VERSION ""

NS_ :

BS_:

BU_:

BO_ 2566889249 VCU_CHMSL: 8 Vector__XXX
 SG_ FF9F_CHMSL_Status : 4|4@1- (1,0) [0|0] "" Vector__XXX

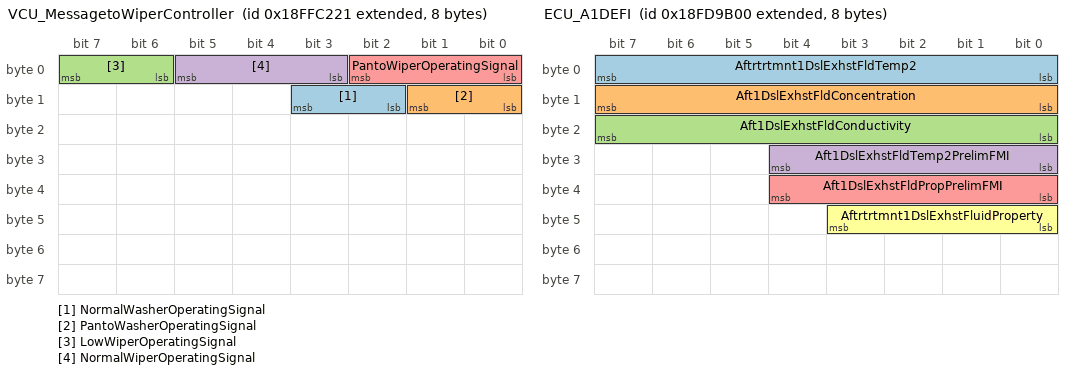
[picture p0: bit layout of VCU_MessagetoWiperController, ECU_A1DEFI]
BO_ 2566898209 VCU_MessagetoWiperController: 8 Vector__XXX
 SG_ NormalWasherOperatingSignal : 10|2@1+ (1,0) [0|3] "bit" Vector__XXX
 SG_ PantoWasherOperatingSignal : 8|2@1+ (1,0) [0|3] "bit" Vector__XXX
 SG_ LowWiperOperatingSignal : 6|2@1+ (1,0) [0|3] "count" Vector__XXX
 SG_ NormalWiperOperatingSignal : 3|3@1+ (1,0) [0|7] "bit" Vector__XXX
 SG_ PantoWiperOperatingSignal : 0|3@1+ (1,0) [0|7] "bit" Vector__XXX

BO_ 2566868921 RPM_Dial_CAN_Type: 8 Vector__XXX
 SG_ FF4F_RPM_Dial_Volt : 0|8@1+ (0.02044,0) [0|0] "" Vector__XXX
 SG_ FF4F_RPM_Dail_Step : 8|4@1+ (1,0) [0|0] "" Vector__XXX

BO_ 2566896387 TCU_TM4V: 8 Vector__XXX
 SG_ FFBB_HSTcutoffSV_State : 4|2@1+ (1,0) [0|3] "" Vector__XXX
 SG_ FFBB_Creep_Symbol : 0|2@1+ (1,0) [0|3] "" Vector__XXX
 SG_ FFBB_2speedSV_State : 2|2@1+ (1,0) [0|3] "" Vector__XXX

BO_ 2566896131 TCU_TM5V: 8 Vector__XXX
 SG_ FFBA_CTL_RH_R_TravelPS : 16|16@1+ (0.0625,0) [0|4095.9375] "bar" Vector__XXX
 SG_ FFBA_CTL_LH_R_TravelPS : 48|16@1+ (0.0625,0) [0|4095.9375] "bar" Vector__XXX
 SG_ FFBA_CTL_LH_F_TravelPS : 32|16@1+ (0.0625,0) [0|4095.9375] "bar" Vector__XXX
 SG_ FFBA_CTL_RH_F_TravelPS : 0|16@1+ (0.0625,0) [0|4095.9375] "bar" Vector__XXX

BO_ 2566575433 EVSE1_ACS1: 8 Vector__XXX
 SG_ EVSE_AC_RMS_Current_Limit_N : 48|16@1+ (0.0625,0) [0|4095.9375] "A" Vector__XXX
 SG_ EVSE_AC_RMS_Current_Limit_3 : 32|16@1+ (0.0625,0) [0|4095.9375] "A" Vector__XXX
 SG_ EVSE_AC_RMS_Current_Limit_2 : 16|16@1+ (0.0625,0) [0|4095.9375] "A" Vector__XXX
 SG_ EVSE_AC_RMS_Current_Limit_1 : 0|16@1+ (0.0625,0) [0|4095.9375] "A" Vector__XXX

BO_ 2365571361 VCU_VM2T: 8 Vector__XXX
 SG_ FFC1_VCU_Counter : 56|4@1+ (1,0) [0|15] "State" Vector__XXX
 SG_ FFC1_VCU_CheckSum : 60|4@1+ (1,0) [0|15] "State" Vector__XXX
 SG_ FFC1_VCU_OPS : 8|2@1+ (1,0) [0|3] "state" Vector__XXX
 SG_ FFC1_VCU_EngineControlDial : 0|8@1+ (0.02044,0) [0|5.11] "V" Vector__XXX

BO_ 2566758144 ECU_ATS1AC1: 8 Vector__XXX
 SG_ FD9F_ATS1AirPressAP : 48|8@1+ (0.4,0) [0|100] "%" Vector__XXX
 SG_ FD9F_ATS1AirPressCTRL : 32|16@1+ (0.0025,0) [0|160.6375] "%" Vector__XXX

BO_ 2566757120 ECU_A1DEFI: 8 Vector__XXX
 SG_ Aftrtrtmnt1DslExhstFldTemp2 : 0|8@1+ (1,-40) [-40|210] "deg C" Vector__XXX
 SG_ Aft1DslExhstFldConcentration : 8|8@1+ (0.25,0) [0|62.5] "%" Vector__XXX
 SG_ Aft1DslExhstFldConductivity : 16|8@1+ (5,0) [0|1250] "uS/mm" Vector__XXX
 SG_ Aft1DslExhstFldTemp2PrelimFMI : 24|5@1+ (1,0) [0|31] "" Vector__XXX
 SG_ Aft1DslExhstFldPropPrelimFMI : 32|5@1+ (1,0) [0|31] "" Vector__XXX
 SG_ Aftrtrtmnt1DslExhstFluidProperty : 40|4@1+ (1,0) [0|15] "" Vector__XXX

BO_ 2566753280 ECU_ATS1GasPara: 8 Vector__XXX
 SG_ FD8C_DPFIntakePress1 : 0|16@1+ (0.1,0) [0|6425.5] "kpa" Vector__XXX

BO_ 2566745344 ECU_ATS1AC2: 8 Vector__XXX
 SG_ FD6D_ATS12edAirPress : 48|16@1+ (0.1,0) [0|6425.5] "kPa" Vector__XXX
 SG_ FD6D_ATS12edAirMassFlow : 32|16@1+ (0.2,0) [0|12851] "kg" Vector__XXX

BO_ 2566743296 ECU_ATS1FC2: 8 Vector__XXX
 SG_ FD65_AT1FuelFlowPress2ActCTRL : 24|16@1+ (0.0025,0) [0|160.6375] "%" Vector__XXX
 SG_ FD65_AT1FuelFlowDiverValveCTRL : 18|2@1+ (1,0) [0|3] "" Vector__XXX
 SG_ FD65_AT1FuelPumpRelayCTRL : 16|2@1+ (1,0) [0|3] "" Vector__XXX
 SG_ FD65_AT1FuelPress2 : 0|16@1+ (0.1,0) [0|6425.5] "kPa" Vector__XXX

BO_ 2566708736 ECU_AT1AC3: 8 Vector__XXX
 SG_ FCDE_AT1SeAirAbPress : 0|16@1+ (0.1,0) [0|6553.5] "kPa" Vector__XXX

BO_ 2566700288 ECU_A1SCRSI2: 8 Vector__XXX
 SG_ FCBD_Af1TotalDieExFluUsed : 0|32@1+ (0.5,0) [0|2105540607.5] "Liter" Vector__XXX

BO_ 2566699264 ECU_AT1S2: 8 Vector__XXX
 SG_ FCB9_Af1DPFTimeToNextActRegen : 0|32@1+ (1,0) [0|4211081215] "Sec" Vector__XXX

BO_ 2566890792 GP_GPCCS: 8 Vector__XXX
 SG_ FFA5_Counter : 56|4@1+ (1,0) [0|15] "State" Vector__XXX
 SG_ FFA5_CheckSum : 60|4@1+ (1,0) [0|15] "State" Vector__XXX
 SG_ FFA5_JoystickPatternChange : 0|3@1+ (1,0) [0|7] "" Vector__XXX

BO_ 2365542433 VCU_Pwr_Work_Btn: 8 Vector__XXX
 SG_ FF50_WorkModeButton : 8|2@1+ (1,0) [0|3] "" Vector__XXX
 SG_ FF50_Power_Btn : 0|3@1+ (1,0) [0|7] "" Vector__XXX

BO_ 2566847521 VCU_DD1: 8 Vector__XXX
 SG_ FEFC_FuelTankLevel2 : 48|8@1+ (0.4,0) [0|102] "%" Vector__XXX
 SG_ FEFC_EngineOilFilterPressure : 24|8@1+ (0.5,0) [0|127.5] "kPa" Vector__XXX
 SG_ FEFC_EngineFuelFilterPressure : 16|8@1+ (2,0) [0|510] "kPa" Vector__XXX
 SG_ FEFC_CargoAmbientTemperature : 32|16@1+ (0.03125,0) [0|2047.96875] "กษ" Vector__XXX
 SG_ FEFC_WasherFluidLevel : 0|8@1+ (0.4,0) [0|102] "%" Vector__XXX
 SG_ FEFC_FuelTankLevel1 : 8|8@1+ (0.4,0) [0|102] "%" Vector__XXX

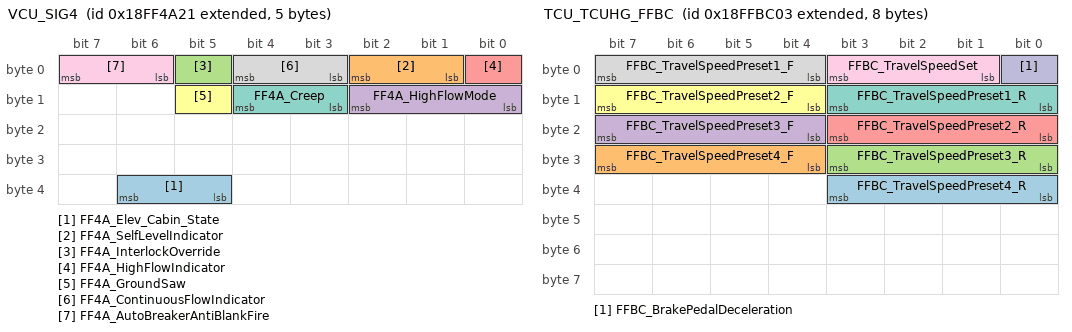
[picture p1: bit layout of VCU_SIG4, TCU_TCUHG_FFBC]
BO_ 2566867489 VCU_SIG4: 5 Vector__XXX
 SG_ FF4A_Elev_Cabin_State : 37|2@1+ (1,0) [0|3] "" Vector__XXX
 SG_ FF4A_SelfLevelIndicator : 1|2@1+ (1,0) [0|3] "" Vector__XXX
 SG_ FF4A_InterlockOverride : 5|1@1+ (1,0) [0|1] "" Vector__XXX
 SG_ FF4A_HighFlowMode : 8|3@1+ (1,0) [0|7] "" Vector__XXX
 SG_ FF4A_HighFlowIndicator : 0|1@1+ (1,0) [0|1] "" Vector__XXX
 SG_ FF4A_GroundSaw : 13|1@1+ (1,0) [0|1] "" Vector__XXX
 SG_ FF4A_Creep : 11|2@1+ (1,0) [0|3] "" Vector__XXX
 SG_ FF4A_ContinuousFlowIndicator : 3|2@1+ (1,0) [0|3] "" Vector__XXX
 SG_ FF4A_AutoBreakerAntiBlankFire : 6|2@1+ (1,0) [0|3] "" Vector__XXX

BO_ 2566835017 OBC_DM02_SA49: 42 Vector__XXX
 SG_ FECA_10_SPNConversionMethod : 335|1@1+ (1,0) [0|1] "" Vector__XXX
 SG_ FECA_10_SPN3 : 325|3@1+ (1,0) [0|7] "" Vector__XXX
 SG_ FECA_10_SPN1_2 : 304|16@1+ (1,0) [0|65535] "" Vector__XXX
 SG_ FECA_10_OccurenceCount : 328|7@1+ (1,0) [0|127] "" Vector__XXX
 SG_ FECA_10_FMI : 320|5@1+ (1,0) [0|31] "" Vector__XXX
 SG_ FECA_09_SPNConversionMethod : 303|1@1+ (1,0) [0|1] "" Vector__XXX
 SG_ FECA_09_SPN3 : 293|3@1+ (1,0) [0|7] "" Vector__XXX
 SG_ FECA_09_SPN1_2 : 272|16@1+ (1,0) [0|65535] "" Vector__XXX
 SG_ FECA_09_OccurenceCount : 296|7@1+ (1,0) [0|127] "" Vector__XXX
 SG_ FECA_09_FMI : 288|5@1+ (1,0) [0|31] "" Vector__XXX
 SG_ FECA_08_SPNConversionMethod : 271|1@1+ (1,0) [0|1] "" Vector__XXX
 SG_ FECA_08_SPN3 : 261|3@1+ (1,0) [0|7] "" Vector__XXX
 SG_ FECA_08_SPN1_2 : 240|16@1+ (1,0) [0|65535] "" Vector__XXX
 SG_ FECA_08_OccurenceCount : 264|7@1+ (1,0) [0|127] "" Vector__XXX
 SG_ FECA_08_FMI : 256|5@1+ (1,0) [0|31] "" Vector__XXX
 SG_ FECA_07_SPNConversionMethod : 239|1@1+ (1,0) [0|1] "" Vector__XXX
 SG_ FECA_07_SPN3 : 229|3@1+ (1,0) [0|7] "" Vector__XXX
 SG_ FECA_07_SPN1_2 : 208|16@1+ (1,0) [0|65535] "" Vector__XXX
 SG_ FECA_07_OccurenceCount : 232|7@1+ (1,0) [0|127] "" Vector__XXX
 SG_ FECA_07_FMI : 224|5@1+ (1,0) [0|31] "" Vector__XXX
 SG_ FECA_06_SPNConversionMethod : 207|1@1+ (1,0) [0|1] "" Vector__XXX
 SG_ FECA_06_SPN3 : 197|3@1+ (1,0) [0|7] "" Vector__XXX
 SG_ FECA_06_SPN1_2 : 176|16@1+ (1,0) [0|65535] "" Vector__XXX
 SG_ FECA_06_OccurenceCount : 200|7@1+ (1,0) [0|127] "" Vector__XXX
 SG_ FECA_06_FMI : 192|5@1+ (1,0) [0|31] "" Vector__XXX
 SG_ FECA_05_SPNConversionMethod : 175|1@1+ (1,0) [0|1] "" Vector__XXX
 SG_ FECA_05_SPN3 : 165|3@1+ (1,0) [0|7] "" Vector__XXX
 SG_ FECA_05_SPN1_2 : 144|16@1+ (1,0) [0|65535] "" Vector__XXX
 SG_ FECA_05_OccurenceCount : 168|7@1+ (1,0) [0|127] "" Vector__XXX
 SG_ FECA_05_FMI : 160|5@1+ (1,0) [0|31] "" Vector__XXX
 SG_ FECA_04_SPNConversionMethod : 143|1@1+ (1,0) [0|1] "" Vector__XXX
 SG_ FECA_04_SPN3 : 133|3@1+ (1,0) [0|7] "" Vector__XXX
 SG_ FECA_04_SPN1_2 : 112|16@1+ (1,0) [0|65535] "" Vector__XXX
 SG_ FECA_04_OccurenceCount : 136|7@1+ (1,0) [0|127] "" Vector__XXX
 SG_ FECA_04_FMI : 128|5@1+ (1,0) [0|31] "" Vector__XXX
 SG_ FECA_03_SPNConversionMethod : 111|1@1+ (1,0) [0|1] "" Vector__XXX
 SG_ FECA_03_SPN3 : 101|3@1+ (1,0) [0|7] "" Vector__XXX
 SG_ FECA_03_SPN1_2 : 80|16@1+ (1,0) [0|65535] "" Vector__XXX
 SG_ FECA_03_OccurenceCount : 104|7@1+ (1,0) [0|127] "" Vector__XXX
 SG_ FECA_03_FMI : 96|5@1+ (1,0) [0|31] "" Vector__XXX
 SG_ FECA_02_SPNConversionMethod : 79|1@1+ (1,0) [0|1] "" Vector__XXX
 SG_ FECA_02_SPN3 : 69|3@1+ (1,0) [0|7] "" Vector__XXX
 SG_ FECA_02_SPN1_2 : 48|16@1+ (1,0) [0|65535] "" Vector__XXX
 SG_ FECA_02_OccurenceCount : 72|7@1+ (1,0) [0|127] "" Vector__XXX
 SG_ FECA_02_FMI : 64|5@1+ (1,0) [0|31] "" Vector__XXX
 SG_ FECA_01_SPNConversionMethod : 47|1@1+ (1,0) [0|1] "" Vector__XXX
 SG_ FECA_01_SPN3 : 37|3@1+ (1,0) [0|7] "" Vector__XXX
 SG_ FECA_01_SPN1_2 : 16|16@1+ (1,0) [0|65535] "" Vector__XXX
 SG_ FECA_01_RedStopLampStatus : 4|2@1+ (1,0) [0|3] "" Vector__XXX
 SG_ FECA_01_ProtectLampStatus : 0|2@1+ (1,0) [0|3] "" Vector__XXX
 SG_ FECA_01_OccurenceCount : 40|7@1+ (1,0) [0|127] "" Vector__XXX
 SG_ FECA_01_MalFucIndicatorStatus : 6|2@1+ (1,0) [0|3] "" Vector__XXX
 SG_ FECA_01_FMI : 32|5@1+ (1,0) [0|31] "" Vector__XXX
 SG_ FECA_01_FlashRedStopLamp : 12|2@1+ (1,0) [0|3] "" Vector__XXX
 SG_ FECA_01_FlashProtectLamp : 8|2@1+ (1,0) [0|3] "" Vector__XXX
 SG_ FECA_01_FlashAmberLamp : 10|2@1+ (1,0) [0|3] "" Vector__XXX
 SG_ FECA_01_Flash_MalFuncIndiLamp : 14|2@1+ (1,0) [0|3] "" Vector__XXX
 SG_ FECA_01_AmberWarmingLampStatus : 2|2@1+ (1,0) [0|3] "" Vector__XXX

BO_ 2566834761 OBC_DM01_SA49: 42 Vector__XXX
 SG_ FECA_10_SPNConversionMethod : 335|1@1+ (1,0) [0|1] "" Vector__XXX
 SG_ FECA_10_SPN3 : 325|3@1+ (1,0) [0|7] "" Vector__XXX
 SG_ FECA_10_SPN1_2 : 304|16@1+ (1,0) [0|65535] "" Vector__XXX
 SG_ FECA_10_OccurenceCount : 328|7@1+ (1,0) [0|127] "" Vector__XXX
 SG_ FECA_10_FMI : 320|5@1+ (1,0) [0|31] "" Vector__XXX
 SG_ FECA_09_SPNConversionMethod : 303|1@1+ (1,0) [0|1] "" Vector__XXX
 SG_ FECA_09_SPN3 : 293|3@1+ (1,0) [0|7] "" Vector__XXX
 SG_ FECA_09_SPN1_2 : 272|16@1+ (1,0) [0|65535] "" Vector__XXX
 SG_ FECA_09_OccurenceCount : 296|7@1+ (1,0) [0|127] "" Vector__XXX
 SG_ FECA_09_FMI : 288|5@1+ (1,0) [0|31] "" Vector__XXX
 SG_ FECA_08_SPNConversionMethod : 271|1@1+ (1,0) [0|1] "" Vector__XXX
 SG_ FECA_08_SPN3 : 261|3@1+ (1,0) [0|7] "" Vector__XXX
 SG_ FECA_08_SPN1_2 : 240|16@1+ (1,0) [0|65535] "" Vector__XXX
 SG_ FECA_08_OccurenceCount : 264|7@1+ (1,0) [0|127] "" Vector__XXX
 SG_ FECA_08_FMI : 256|5@1+ (1,0) [0|31] "" Vector__XXX
 SG_ FECA_07_SPNConversionMethod : 239|1@1+ (1,0) [0|1] "" Vector__XXX
 SG_ FECA_07_SPN3 : 229|3@1+ (1,0) [0|7] "" Vector__XXX
 SG_ FECA_07_SPN1_2 : 208|16@1+ (1,0) [0|65535] "" Vector__XXX
 SG_ FECA_07_OccurenceCount : 232|7@1+ (1,0) [0|127] "" Vector__XXX
 SG_ FECA_07_FMI : 224|5@1+ (1,0) [0|31] "" Vector__XXX
 SG_ FECA_06_SPNConversionMethod : 207|1@1+ (1,0) [0|1] "" Vector__XXX
 SG_ FECA_06_SPN3 : 197|3@1+ (1,0) [0|7] "" Vector__XXX
 SG_ FECA_06_SPN1_2 : 176|16@1+ (1,0) [0|65535] "" Vector__XXX
 SG_ FECA_06_OccurenceCount : 200|7@1+ (1,0) [0|127] "" Vector__XXX
 SG_ FECA_06_FMI : 192|5@1+ (1,0) [0|31] "" Vector__XXX
 SG_ FECA_05_SPNConversionMethod : 175|1@1+ (1,0) [0|1] "" Vector__XXX
 SG_ FECA_05_SPN3 : 165|3@1+ (1,0) [0|7] "" Vector__XXX
 SG_ FECA_05_SPN1_2 : 144|16@1+ (1,0) [0|65535] "" Vector__XXX
 SG_ FECA_05_OccurenceCount : 168|7@1+ (1,0) [0|127] "" Vector__XXX
 SG_ FECA_05_FMI : 160|5@1+ (1,0) [0|31] "" Vector__XXX
 SG_ FECA_04_SPNConversionMethod : 143|1@1+ (1,0) [0|1] "" Vector__XXX
 SG_ FECA_04_SPN3 : 133|3@1+ (1,0) [0|7] "" Vector__XXX
 SG_ FECA_04_SPN1_2 : 112|16@1+ (1,0) [0|65535] "" Vector__XXX
 SG_ FECA_04_OccurenceCount : 136|7@1+ (1,0) [0|127] "" Vector__XXX
 SG_ FECA_04_FMI : 128|5@1+ (1,0) [0|31] "" Vector__XXX
 SG_ FECA_03_SPNConversionMethod : 111|1@1+ (1,0) [0|1] "" Vector__XXX
 SG_ FECA_03_SPN3 : 101|3@1+ (1,0) [0|7] "" Vector__XXX
 SG_ FECA_03_SPN1_2 : 80|16@1+ (1,0) [0|65535] "" Vector__XXX
 SG_ FECA_03_OccurenceCount : 104|7@1+ (1,0) [0|127] "" Vector__XXX
 SG_ FECA_03_FMI : 96|5@1+ (1,0) [0|31] "" Vector__XXX
 SG_ FECA_02_SPNConversionMethod : 79|1@1+ (1,0) [0|1] "" Vector__XXX
 SG_ FECA_02_SPN3 : 69|3@1+ (1,0) [0|7] "" Vector__XXX
 SG_ FECA_02_SPN1_2 : 48|16@1+ (1,0) [0|65535] "" Vector__XXX
 SG_ FECA_02_OccurenceCount : 72|7@1+ (1,0) [0|127] "" Vector__XXX
 SG_ FECA_02_FMI : 64|5@1+ (1,0) [0|31] "" Vector__XXX
 SG_ FECA_01_SPNConversionMethod : 47|1@1+ (1,0) [0|1] "" Vector__XXX
 SG_ FECA_01_SPN3 : 37|3@1+ (1,0) [0|7] "" Vector__XXX
 SG_ FECA_01_SPN1_2 : 16|16@1+ (1,0) [0|65535] "" Vector__XXX
 SG_ FECA_01_RedStopLampStatus : 4|2@1+ (1,0) [0|3] "" Vector__XXX
 SG_ FECA_01_ProtectLampStatus : 0|2@1+ (1,0) [0|3] "" Vector__XXX
 SG_ FECA_01_OccurenceCount : 40|7@1+ (1,0) [0|127] "" Vector__XXX
 SG_ FECA_01_MalFucIndicatorStatus : 6|2@1+ (1,0) [0|3] "" Vector__XXX
 SG_ FECA_01_FMI : 32|5@1+ (1,0) [0|31] "" Vector__XXX
 SG_ FECA_01_FlashRedStopLamp : 12|2@1+ (1,0) [0|3] "" Vector__XXX
 SG_ FECA_01_FlashProtectLamp : 8|2@1+ (1,0) [0|3] "" Vector__XXX
 SG_ FECA_01_FlashAmberLamp : 10|2@1+ (1,0) [0|3] "" Vector__XXX
 SG_ FECA_01_Flash_MalFuncIndiLamp : 14|2@1+ (1,0) [0|3] "" Vector__XXX
 SG_ FECA_01_AmberWarmingLampStatus : 2|2@1+ (1,0) [0|3] "" Vector__XXX

BO_ 2566722633 OBC_BCH2_SA49: 9 Vector__XXX
 SG_ FD14_Bat_Charger2_OutputCurrent : 24|16@1+ (0.05,-1600) [-1600|1676.75] "0" Vector__XXX
 SG_ FD14_Bat_Charger2_OutputVolt : 8|2@1+ (0.05,0) [0|0.15] "" Vector__XXX
 SG_ FD14_Bat_Charger2_RestartState : 6|2@1+ (1,0) [0|3] "" Vector__XXX
 SG_ FD14_Bat_Charger2_PowerLineState : 4|2@1+ (1,0) [0|3] "" Vector__XXX
 SG_ FD14_Bat_Charger2_State : 0|4@1+ (1,0) [0|15] "" Vector__XXX

BO_ 2566722989 OBC_BCH1: 9 Vector__XXX
 SG_ FD15_Reserved : 40|32@1- (1,0) [-2147483648|2147483647] "" Vector__XXX
 SG_ FD15_Battery_Charger1_State : 0|4@1+ (1,0) [0|15] "bit" Vector__XXX
 SG_ FD15_Battery_Charger1_Pow_State : 4|4@1+ (1,0) [0|3] "bit" Vector__XXX
 SG_ FD15_Battery_Charger1_Out_Volt : 8|16@1+ (0.05,0) [0|210] "V" Vector__XXX
 SG_ FD15_Battery_Charger1_Out_Curr : 24|16@1+ (0.05,-1600) [-1600|1612.75] "A" Vector__XXX

BO_ 2566722733 OBC_BCH2: 9 Vector__XXX
 SG_ FD14_Bat_Charger2_OutputCurrent : 24|16@1+ (0.05,-1600) [-1600|1676.75] "0" Vector__XXX
 SG_ FD14_Bat_Charger2_OutputVolt : 8|2@1+ (0.05,0) [0|0.15] "" Vector__XXX
 SG_ FD14_Bat_Charger2_RestartState : 6|2@1+ (1,0) [0|3] "" Vector__XXX
 SG_ FD14_Bat_Charger2_PowerLineState : 4|2@1+ (1,0) [0|3] "" Vector__XXX
 SG_ FD14_Bat_Charger2_State : 0|4@1+ (1,0) [0|15] "" Vector__XXX

BO_ 2354970657 VCU_MG1ReqDC: 8 Vector__XXX
 SG_ _5E00_ReqDC_S_CurMaxRegen : 48|12@1+ (0.0625,-125) [-125|125] "" Vector__XXX
 SG_ _5E00_ReqDC_S_CurMaxDrive : 36|12@1+ (0.0625,-125) [-125|125] "" Vector__XXX
 SG_ _5E00_Reserved : 0|36@1+ (1,0) [0|68719476735] "" Vector__XXX

BO_ 2566901763 TCU_HSDI_FFD0: 8 Vector__XXX
 SG_ FFD0_TCU_Randomvalue : 0|16@1+ (1,0) [0|65535] "" Vector__XXX

BO_ 2566896643 TCU_TCUHG_FFBC: 8 Vector__XXX
 SG_ FFBC_TravelSpeedPreset4_R : 32|4@1+ (1,0) [0|15] "" Vector__XXX
 SG_ FFBC_TravelSpeedPreset4_F : 28|4@1+ (1,0) [0|15] "" Vector__XXX
 SG_ FFBC_TravelSpeedPreset3_R : 24|4@1+ (1,0) [0|15] "" Vector__XXX
 SG_ FFBC_TravelSpeedPreset3_F : 20|4@1+ (1,0) [0|15] "" Vector__XXX
 SG_ FFBC_TravelSpeedPreset2_R : 16|4@1+ (1,0) [0|15] "" Vector__XXX
 SG_ FFBC_TravelSpeedPreset2_F : 12|4@1+ (1,0) [0|15] "" Vector__XXX
 SG_ FFBC_TravelSpeedPreset1_R : 8|4@1+ (1,0) [0|15] "" Vector__XXX
 SG_ FFBC_TravelSpeedPreset1_F : 4|4@1+ (1,0) [0|15] "" Vector__XXX
 SG_ FFBC_TravelSpeedSet : 1|3@1+ (1,0) [0|7] "" Vector__XXX
 SG_ FFBC_BrakePedalDeceleration : 0|1@1+ (1,0) [0|1] "" Vector__XXX

BO_ 2365544737 Keypad_KEYPADI3_xC: 8 Vector__XXX
 SG_ FF59_TrackExpansion_L : 58|2@1+ (1,0) [0|3] "" Vector__XXX
 SG_ FF59_TrackExpansion_Center : 56|2@1+ (1,0) [0|3] "" Vector__XXX
 SG_ FF59_TrackExpansion_R : 54|2@1+ (1,0) [0|3] "" Vector__XXX
 SG_ FF59_Indicate_Wiper_Front_R : 48|2@1+ (1,0) [0|3] "" Vector__XXX
 SG_ FF59_Indicate_Wiper_Front_L : 52|2@1+ (1,0) [0|3] "" Vector__XXX
 SG_ FF59_Indicate_Wiper_Front_C : 50|2@1+ (1,0) [0|3] "" Vector__XXX
 SG_ FF59_Indicate_Wiper_Rear_R : 42|2@1+ (1,0) [0|3] "" Vector__XXX
 SG_ FF59_Indicate_Wiper_Rear_L : 46|2@1+ (1,0) [0|3] "" Vector__XXX
 SG_ FF59_Indicate_Wiper_Rear_C : 44|2@1+ (1,0) [0|3] "" Vector__XXX
 SG_ FF59_Indicate_Wiper_Side_R : 36|2@1+ (1,0) [0|3] "" Vector__XXX
 SG_ FF59_Indicate_Wiper_Side_L : 40|2@1+ (1,0) [0|3] "" Vector__XXX
 SG_ FF59_Indicate_Wiper_Side_C : 38|2@1+ (1,0) [0|3] "" Vector__XXX
 SG_ FF59_Indicate_Washer_Front_R : 30|2@1+ (1,0) [0|3] "" Vector__XXX
 SG_ FF59_Indicate_Washer_Front_L : 34|2@1+ (1,0) [0|3] "" Vector__XXX
 SG_ FF59_Indicate_Washer_Front_C : 32|2@1+ (1,0) [0|3] "" Vector__XXX
 SG_ FF59_Indicate_Washer_Side_R : 24|2@1+ (1,0) [0|3] "" Vector__XXX
 SG_ FF59_Indicate_Washer_Side_L : 28|2@1+ (1,0) [0|3] "" Vector__XXX
 SG_ FF59_Indicate_Washer_Side_C : 26|2@1+ (1,0) [0|3] "" Vector__XXX
 SG_ FF59_Indicate_AirComp_R : 12|2@1+ (1,0) [0|3] "" Vector__XXX
 SG_ FF59_Indicate_AirComp_L : 16|2@1+ (1,0) [0|3] "" Vector__XXX
 SG_ FF59_Indicate_AirComp_C : 14|2@1+ (1,0) [0|3] "" Vector__XXX
 SG_ FF59_Indicate_TraveSpeed_R : 6|2@1+ (1,0) [0|3] "" Vector__XXX
 SG_ FF59_Indicate_TraveSpeed_L : 10|2@1+ (1,0) [0|3] "" Vector__XXX
 SG_ FF59_Indicate_TraveSpeed_C : 8|2@1+ (1,0) [0|3] "" Vector__XXX
 SG_ FF59_Indicate_BuzzerStop_R : 0|2@1+ (1,0) [0|3] "" Vector__XXX
 SG_ FF59_Indicate_BuzzerStop_L : 4|2@1+ (1,0) [0|3] "" Vector__XXX
 SG_ FF59_Indicate_BuzzerStop_C : 2|2@1+ (1,0) [0|3] "" Vector__XXX

BO_ 2566890561 GW_2DMGBC: 8 Vector__XXX
 SG_ FFA4_HeightLimitAlarm : 8|1@1+ (1,0) [0|1] "" Vector__XXX
 SG_ FFA4_LaserStrikeAlarm : 7|1@1+ (1,0) [0|1] "" Vector__XXX
 SG_ FFA4_MGSoundGuidanceStep : 3|4@1+ (1,0) [0|15] "" Vector__XXX
 SG_ FFA4_AlarmState : 0|3@1+ (1,0) [0|7] "" Vector__XXX

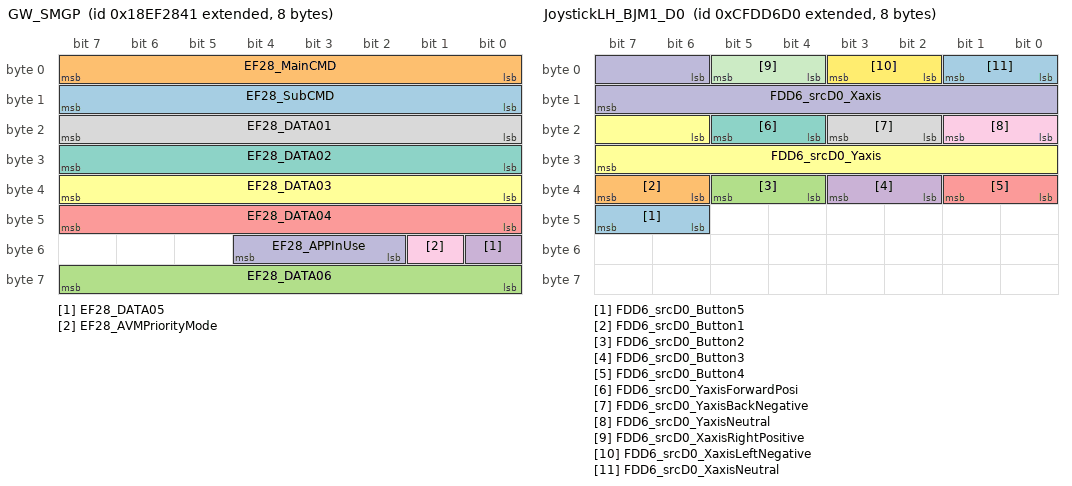
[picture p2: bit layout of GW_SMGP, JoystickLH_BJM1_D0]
BO_ 2565810241 GW_SMGP: 8 Vector__XXX
 SG_ EF28_SubCMD : 8|8@1+ (1,0) [0|255] "" Vector__XXX
 SG_ EF28_MainCMD : 0|8@1+ (1,0) [0|255] "" Vector__XXX
 SG_ EF28_DATA06 : 56|8@1+ (1,0) [0|255] "" Vector__XXX
 SG_ EF28_DATA05 : 48|1@1+ (1,0) [0|1] "" Vector__XXX
 SG_ EF28_DATA04 : 40|8@1+ (1,0) [0|255] "" Vector__XXX
 SG_ EF28_DATA03 : 32|8@1+ (1,0) [0|255] "" Vector__XXX
 SG_ EF28_DATA02 : 24|8@1+ (1,0) [0|255] "" Vector__XXX
 SG_ EF28_DATA01 : 16|8@1+ (1,0) [0|255] "" Vector__XXX
 SG_ EF28_AVMPriorityMode : 49|1@1+ (1,0) [0|1] "" Vector__XXX
 SG_ EF28_APPInUse : 50|3@1+ (1,0) [0|7] "" Vector__XXX

BO_ 2365446096 JoystickLH_EJM1_D0: 8 Vector__XXX
 SG_ FDD7_srcD0_Grip_Xaxis : 6|10@1+ (0.1,0) [0|102.3] "" Vector__XXX
 SG_ FDD7_srcD0_Grip_XaxisRight : 4|2@1+ (1,0) [0|3] "" Vector__XXX
 SG_ FDD7_srcD0_Grip_XaxisLeftNega : 2|2@1+ (1,0) [0|3] "" Vector__XXX
 SG_ FDD7_srcD0_Grip_XaxisNeutral : 0|2@1+ (1,0) [0|3] "" Vector__XXX

BO_ 2365445840 JoystickLH_BJM1_D0: 8 Vector__XXX
 SG_ FDD6_srcD0_Button5 : 46|2@1+ (1,0) [0|3] "" Vector__XXX
 SG_ FDD6_srcD0_Button1 : 38|2@1+ (1,0) [0|3] "" Vector__XXX
 SG_ FDD6_srcD0_Button2 : 36|2@1+ (1,0) [0|3] "" Vector__XXX
 SG_ FDD6_srcD0_Button3 : 34|2@1+ (1,0) [0|3] "" Vector__XXX
 SG_ FDD6_srcD0_Button4 : 32|2@1+ (1,0) [0|3] "" Vector__XXX
 SG_ FDD6_srcD0_Yaxis : 22|10@1+ (0.1,0) [0|102.3] "" Vector__XXX
 SG_ FDD6_srcD0_YaxisForwardPosi : 20|2@1+ (1,0) [0|3] "" Vector__XXX
 SG_ FDD6_srcD0_YaxisBackNegative : 18|2@1+ (1,0) [0|3] "" Vector__XXX
 SG_ FDD6_srcD0_YaxisNeutral : 16|2@1+ (1,0) [0|3] "" Vector__XXX
 SG_ FDD6_srcD0_Xaxis : 6|10@1+ (0.1,0) [0|102.3] "" Vector__XXX
 SG_ FDD6_srcD0_XaxisRightPositive : 4|2@1+ (1,0) [0|3] "" Vector__XXX
 SG_ FDD6_srcD0_XaxisLeftNegative : 2|2@1+ (1,0) [0|3] "" Vector__XXX
 SG_ FDD6_srcD0_XaxisNeutral : 0|2@1+ (1,0) [0|3] "" Vector__XXX

BO_ 2566616464 PMI_MG1IR1: 8 Vector__XXX
 SG_ FB75_MG1InverterReferenceTorque : 16|16@1+ (0.5,0) [0|32127.5] "Nm" Vector__XXX
 SG_ FB75_MG1InverterReferenceSpeed : 32|16@1+ (4,0) [0|257020] "rpm" Vector__XXX
 SG_ FB75_MG1InverterReferencePower : 48|16@1+ (0.0625,0) [0|4015.9375] "kW" Vector__XXX
 SG_ FB75_MG1InverterReference1CRC : 0|8@1+ (1,0) [0|255] "count" Vector__XXX
 SG_ FB75_MG1InverterReference1Count : 8|4@1+ (1,0) [0|15] "bit" Vector__XXX

BO_ 2566835088 PMI_DM02: 42 Vector__XXX
 SG_ FECA_10_SPNConversionMethod : 335|1@1+ (1,0) [0|1] "" Vector__XXX
 SG_ FECA_10_SPN3 : 325|3@1+ (1,0) [0|7] "" Vector__XXX
 SG_ FECA_10_SPN1_2 : 304|16@1+ (1,0) [0|65535] "" Vector__XXX
 SG_ FECA_10_OccurenceCount : 328|7@1+ (1,0) [0|127] "" Vector__XXX
 SG_ FECA_10_FMI : 320|5@1+ (1,0) [0|31] "" Vector__XXX
 SG_ FECA_09_SPNConversionMethod : 303|1@1+ (1,0) [0|1] "" Vector__XXX
 SG_ FECA_09_SPN3 : 293|3@1+ (1,0) [0|7] "" Vector__XXX
 SG_ FECA_09_SPN1_2 : 272|16@1+ (1,0) [0|65535] "" Vector__XXX
 SG_ FECA_09_OccurenceCount : 296|7@1+ (1,0) [0|127] "" Vector__XXX
 SG_ FECA_09_FMI : 288|5@1+ (1,0) [0|31] "" Vector__XXX
 SG_ FECA_08_SPNConversionMethod : 271|1@1+ (1,0) [0|1] "" Vector__XXX
 SG_ FECA_08_SPN3 : 261|3@1+ (1,0) [0|7] "" Vector__XXX
 SG_ FECA_08_SPN1_2 : 240|16@1+ (1,0) [0|65535] "" Vector__XXX
 SG_ FECA_08_OccurenceCount : 264|7@1+ (1,0) [0|127] "" Vector__XXX
 SG_ FECA_08_FMI : 256|5@1+ (1,0) [0|31] "" Vector__XXX
 SG_ FECA_07_SPNConversionMethod : 239|1@1+ (1,0) [0|1] "" Vector__XXX
 SG_ FECA_07_SPN3 : 229|3@1+ (1,0) [0|7] "" Vector__XXX
 SG_ FECA_07_SPN1_2 : 208|16@1+ (1,0) [0|65535] "" Vector__XXX
 SG_ FECA_07_OccurenceCount : 232|7@1+ (1,0) [0|127] "" Vector__XXX
 SG_ FECA_07_FMI : 224|5@1+ (1,0) [0|31] "" Vector__XXX
 SG_ FECA_06_SPNConversionMethod : 207|1@1+ (1,0) [0|1] "" Vector__XXX
 SG_ FECA_06_SPN3 : 197|3@1+ (1,0) [0|7] "" Vector__XXX
 SG_ FECA_06_SPN1_2 : 176|16@1+ (1,0) [0|65535] "" Vector__XXX
 SG_ FECA_06_OccurenceCount : 200|7@1+ (1,0) [0|127] "" Vector__XXX
 SG_ FECA_06_FMI : 192|5@1+ (1,0) [0|31] "" Vector__XXX
 SG_ FECA_05_SPNConversionMethod : 175|1@1+ (1,0) [0|1] "" Vector__XXX
 SG_ FECA_05_SPN3 : 165|3@1+ (1,0) [0|7] "" Vector__XXX
 SG_ FECA_05_SPN1_2 : 144|16@1+ (1,0) [0|65535] "" Vector__XXX
 SG_ FECA_05_OccurenceCount : 168|7@1+ (1,0) [0|127] "" Vector__XXX
 SG_ FECA_05_FMI : 160|5@1+ (1,0) [0|31] "" Vector__XXX
 SG_ FECA_04_SPNConversionMethod : 143|1@1+ (1,0) [0|1] "" Vector__XXX
 SG_ FECA_04_SPN3 : 133|3@1+ (1,0) [0|7] "" Vector__XXX
 SG_ FECA_04_SPN1_2 : 112|16@1+ (1,0) [0|65535] "" Vector__XXX
 SG_ FECA_04_OccurenceCount : 136|7@1+ (1,0) [0|127] "" Vector__XXX
 SG_ FECA_04_FMI : 128|5@1+ (1,0) [0|31] "" Vector__XXX
 SG_ FECA_03_SPNConversionMethod : 111|1@1+ (1,0) [0|1] "" Vector__XXX
 SG_ FECA_03_SPN3 : 101|3@1+ (1,0) [0|7] "" Vector__XXX
 SG_ FECA_03_SPN1_2 : 80|16@1+ (1,0) [0|65535] "" Vector__XXX
 SG_ FECA_03_OccurenceCount : 104|7@1+ (1,0) [0|127] "" Vector__XXX
 SG_ FECA_03_FMI : 96|5@1+ (1,0) [0|31] "" Vector__XXX
 SG_ FECA_02_SPNConversionMethod : 79|1@1+ (1,0) [0|1] "" Vector__XXX
 SG_ FECA_02_SPN3 : 69|3@1+ (1,0) [0|7] "" Vector__XXX
 SG_ FECA_02_SPN1_2 : 48|16@1+ (1,0) [0|65535] "" Vector__XXX
 SG_ FECA_02_OccurenceCount : 72|7@1+ (1,0) [0|127] "" Vector__XXX
 SG_ FECA_02_FMI : 64|5@1+ (1,0) [0|31] "" Vector__XXX
 SG_ FECA_01_SPNConversionMethod : 47|1@1+ (1,0) [0|1] "" Vector__XXX
 SG_ FECA_01_SPN3 : 37|3@1+ (1,0) [0|7] "" Vector__XXX
 SG_ FECA_01_SPN1_2 : 16|16@1+ (1,0) [0|65535] "" Vector__XXX
 SG_ FECA_01_RedStopLampStatus : 4|2@1+ (1,0) [0|3] "" Vector__XXX
 SG_ FECA_01_ProtectLampStatus : 0|2@1+ (1,0) [0|3] "" Vector__XXX
 SG_ FECA_01_OccurenceCount : 40|7@1+ (1,0) [0|127] "" Vector__XXX
 SG_ FECA_01_MalFucIndicatorStatus : 6|2@1+ (1,0) [0|3] "" Vector__XXX
 SG_ FECA_01_FMI : 32|5@1+ (1,0) [0|31] "" Vector__XXX
 SG_ FECA_01_FlashRedStopLamp : 12|2@1+ (1,0) [0|3] "" Vector__XXX
 SG_ FECA_01_FlashProtectLamp : 8|2@1+ (1,0) [0|3] "" Vector__XXX
 SG_ FECA_01_FlashAmberLamp : 10|2@1+ (1,0) [0|3] "" Vector__XXX
 SG_ FECA_01_Flash_MalFuncIndiLamp : 14|2@1+ (1,0) [0|3] "" Vector__XXX
 SG_ FECA_01_AmberWarmingLampStatus : 2|2@1+ (1,0) [0|3] "" Vector__XXX

BO_ 2566834832 PMI_DM01: 42 Vector__XXX
 SG_ FECA_10_SPNConversionMethod : 335|1@1+ (1,0) [0|1] "" Vector__XXX
 SG_ FECA_10_SPN3 : 325|3@1+ (1,0) [0|7] "" Vector__XXX
 SG_ FECA_10_SPN1_2 : 304|16@1+ (1,0) [0|65535] "" Vector__XXX
 SG_ FECA_10_OccurenceCount : 328|7@1+ (1,0) [0|127] "" Vector__XXX
 SG_ FECA_10_FMI : 320|5@1+ (1,0) [0|31] "" Vector__XXX
 SG_ FECA_09_SPNConversionMethod : 303|1@1+ (1,0) [0|1] "" Vector__XXX
 SG_ FECA_09_SPN3 : 293|3@1+ (1,0) [0|7] "" Vector__XXX
 SG_ FECA_09_SPN1_2 : 272|16@1+ (1,0) [0|65535] "" Vector__XXX
 SG_ FECA_09_OccurenceCount : 296|7@1+ (1,0) [0|127] "" Vector__XXX
 SG_ FECA_09_FMI : 288|5@1+ (1,0) [0|31] "" Vector__XXX
 SG_ FECA_08_SPNConversionMethod : 271|1@1+ (1,0) [0|1] "" Vector__XXX
 SG_ FECA_08_SPN3 : 261|3@1+ (1,0) [0|7] "" Vector__XXX
 SG_ FECA_08_SPN1_2 : 240|16@1+ (1,0) [0|65535] "" Vector__XXX
 SG_ FECA_08_OccurenceCount : 264|7@1+ (1,0) [0|127] "" Vector__XXX
 SG_ FECA_08_FMI : 256|5@1+ (1,0) [0|31] "" Vector__XXX
 SG_ FECA_07_SPNConversionMethod : 239|1@1+ (1,0) [0|1] "" Vector__XXX
 SG_ FECA_07_SPN3 : 229|3@1+ (1,0) [0|7] "" Vector__XXX
 SG_ FECA_07_SPN1_2 : 208|16@1+ (1,0) [0|65535] "" Vector__XXX
 SG_ FECA_07_OccurenceCount : 232|7@1+ (1,0) [0|127] "" Vector__XXX
 SG_ FECA_07_FMI : 224|5@1+ (1,0) [0|31] "" Vector__XXX
 SG_ FECA_06_SPNConversionMethod : 207|1@1+ (1,0) [0|1] "" Vector__XXX
 SG_ FECA_06_SPN3 : 197|3@1+ (1,0) [0|7] "" Vector__XXX
 SG_ FECA_06_SPN1_2 : 176|16@1+ (1,0) [0|65535] "" Vector__XXX
 SG_ FECA_06_OccurenceCount : 200|7@1+ (1,0) [0|127] "" Vector__XXX
 SG_ FECA_06_FMI : 192|5@1+ (1,0) [0|31] "" Vector__XXX
 SG_ FECA_05_SPNConversionMethod : 175|1@1+ (1,0) [0|1] "" Vector__XXX
 SG_ FECA_05_SPN3 : 165|3@1+ (1,0) [0|7] "" Vector__XXX
 SG_ FECA_05_SPN1_2 : 144|16@1+ (1,0) [0|65535] "" Vector__XXX
 SG_ FECA_05_OccurenceCount : 168|7@1+ (1,0) [0|127] "" Vector__XXX
 SG_ FECA_05_FMI : 160|5@1+ (1,0) [0|31] "" Vector__XXX
 SG_ FECA_04_SPNConversionMethod : 143|1@1+ (1,0) [0|1] "" Vector__XXX
 SG_ FECA_04_SPN3 : 133|3@1+ (1,0) [0|7] "" Vector__XXX
 SG_ FECA_04_SPN1_2 : 112|16@1+ (1,0) [0|65535] "" Vector__XXX
 SG_ FECA_04_OccurenceCount : 136|7@1+ (1,0) [0|127] "" Vector__XXX
 SG_ FECA_04_FMI : 128|5@1+ (1,0) [0|31] "" Vector__XXX
 SG_ FECA_03_SPNConversionMethod : 111|1@1+ (1,0) [0|1] "" Vector__XXX
 SG_ FECA_03_SPN3 : 101|3@1+ (1,0) [0|7] "" Vector__XXX
 SG_ FECA_03_SPN1_2 : 80|16@1+ (1,0) [0|65535] "" Vector__XXX
 SG_ FECA_03_OccurenceCount : 104|7@1+ (1,0) [0|127] "" Vector__XXX
 SG_ FECA_03_FMI : 96|5@1+ (1,0) [0|31] "" Vector__XXX
 SG_ FECA_02_SPNConversionMethod : 79|1@1+ (1,0) [0|1] "" Vector__XXX
 SG_ FECA_02_SPN3 : 69|3@1+ (1,0) [0|7] "" Vector__XXX
 SG_ FECA_02_SPN1_2 : 48|16@1+ (1,0) [0|65535] "" Vector__XXX
 SG_ FECA_02_OccurenceCount : 72|7@1+ (1,0) [0|127] "" Vector__XXX
 SG_ FECA_02_FMI : 64|5@1+ (1,0) [0|31] "" Vector__XXX
 SG_ FECA_01_SPNConversionMethod : 47|1@1+ (1,0) [0|1] "" Vector__XXX
 SG_ FECA_01_SPN3 : 37|3@1+ (1,0) [0|7] "" Vector__XXX
 SG_ FECA_01_SPN1_2 : 16|16@1+ (1,0) [0|65535] "" Vector__XXX
 SG_ FECA_01_RedStopLampStatus : 4|2@1+ (1,0) [0|3] "" Vector__XXX
 SG_ FECA_01_ProtectLampStatus : 0|2@1+ (1,0) [0|3] "" Vector__XXX
 SG_ FECA_01_OccurenceCount : 40|7@1+ (1,0) [0|127] "" Vector__XXX
 SG_ FECA_01_MalFucIndicatorStatus : 6|2@1+ (1,0) [0|3] "" Vector__XXX
 SG_ FECA_01_FMI : 32|5@1+ (1,0) [0|31] "" Vector__XXX
 SG_ FECA_01_FlashRedStopLamp : 12|2@1+ (1,0) [0|3] "" Vector__XXX
 SG_ FECA_01_FlashProtectLamp : 8|2@1+ (1,0) [0|3] "" Vector__XXX
 SG_ FECA_01_FlashAmberLamp : 10|2@1+ (1,0) [0|3] "" Vector__XXX
 SG_ FECA_01_Flash_MalFuncIndiLamp : 14|2@1+ (1,0) [0|3] "" Vector__XXX
 SG_ FECA_01_AmberWarmingLampStatus : 2|2@1+ (1,0) [0|3] "" Vector__XXX

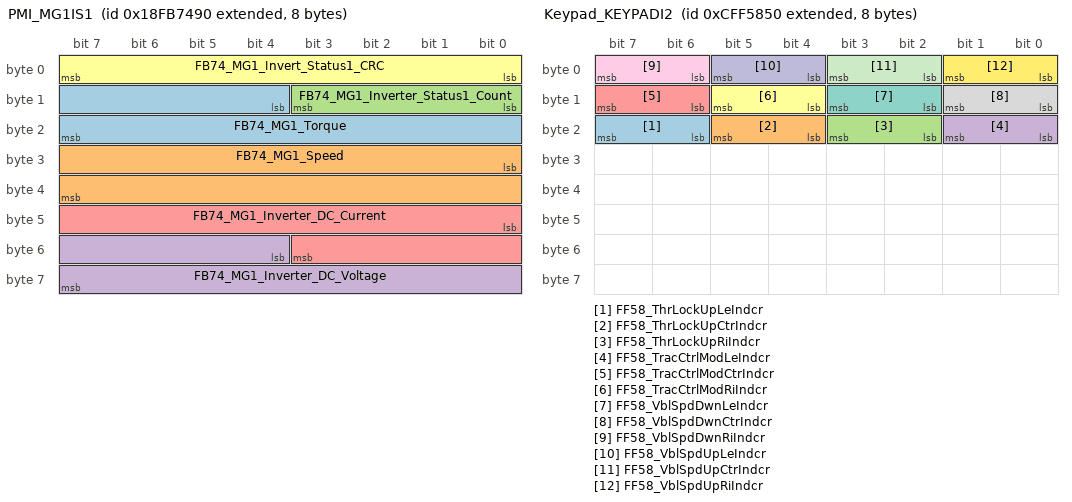
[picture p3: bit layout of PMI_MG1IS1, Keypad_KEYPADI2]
BO_ 2566616208 PMI_MG1IS1: 8 Vector__XXX
 SG_ FB74_MG1_Torque : 12|12@1+ (0.0625,-125) [-125|125.9375] "%" Vector__XXX
 SG_ FB74_MG1_Speed : 24|16@1+ (0.00390625,-125) [-125|125.99609375] "%" Vector__XXX
 SG_ FB74_MG1_Inverter_Status1_Count : 8|4@1+ (1,0) [0|15] "bit" Vector__XXX
 SG_ FB74_MG1_Inverter_DC_Voltage : 52|12@1+ (0.0625,-125) [-125|125.9375] "%" Vector__XXX
 SG_ FB74_MG1_Inverter_DC_Current : 40|12@1+ (0.0625,-125) [-125|125.9375] "%" Vector__XXX
 SG_ FB74_MG1_Invert_Status1_CRC : 0|8@1+ (1,0) [0|255] "count" Vector__XXX

BO_ 2566615952 PMI_MG1IR2: 8 Vector__XXX
 SG_ FB73_Reserved : 12|20@1- (1,0) [-524288|524287] "" Vector__XXX
 SG_ FB73_MG1_Inverter_Ref_Voltage : 48|16@1+ (0.125,0) [0|8031.875] "V" Vector__XXX
 SG_ FB73_MG1_Inverter_Ref_Current : 32|16@1+ (0.125,0) [0|8031.875] "A" Vector__XXX
 SG_ FB73_MG1_Inverter_Ref2_Counter : 8|4@1+ (1,0) [0|15] "bit" Vector__XXX
 SG_ FB73_MG1_Invert_Ref2_CRC : 0|8@1+ (1,0) [0|255] "count" Vector__XXX

BO_ 2566615696 PMI_MG1IT: 8 Vector__XXX
 SG_ FB72_Reserved : 32|32@1- (1,-40) [-2147483688|2147483607] "" Vector__XXX
 SG_ FB72_MG1_Inverter_Temp4 : 24|8@1+ (1,-40) [-40|210] "กษ" Vector__XXX
 SG_ FB72_MG1_Inverter_Temp3 : 16|8@1+ (1,-40) [-40|210] "กษ" Vector__XXX
 SG_ FB72_MG1_Inverter_Temp2 : 8|8@1+ (1,-40) [-40|210] "กษ" Vector__XXX
 SG_ FB72_MG1_Inverter_Temp1 : 0|8@1+ (1,-40) [-40|210] "กษ" Vector__XXX

BO_ 2566615440 PMI_MG1IMT: 8 Vector__XXX
 SG_ FB71_Reserved : 32|32@1- (1,0) [-2147483648|2147483647] "" Vector__XXX
 SG_ FB71_MG1_Temp4av : 24|8@1+ (1,-40) [-40|210] "กษ" Vector__XXX
 SG_ FB71_MG1_Temp3 : 16|8@1+ (1,-40) [-40|210] "กษ" Vector__XXX
 SG_ FB71_MG1_Temp1 : 0|8@1+ (1,-40) [-40|210] "กษ" Vector__XXX
 SG_ FB71_MG1_Temp2 : 8|8@1+ (1,-40) [-40|210] "กษ" Vector__XXX

BO_ 2565964176 PMI_MG1IMF1: 9 Vector__XXX
 SG_ F181_Reserved : 24|40@1+ (1,0) [0|1099511627775] "" Vector__XXX
 SG_ F181_MG1_Inverter_HVIL_Status : 21|3@1+ (1,0) [0|3] "" Vector__XXX
 SG_ F181_MG1_Invert_Ctrl_Setpt_Mod : 16|5@1+ (1,0) [0|31] "" Vector__XXX
 SG_ F181_MG1_Inverter_Feed_Counter : 8|4@1+ (1,0) [0|15] "bit" Vector__XXX
 SG_ F181_MG1_Invert_Ctrl_Lim_Ovr_Mod : 12|4@1+ (1,0) [0|15] "bit" Vector__XXX
 SG_ F181_MG1_Inverter_feed_CRC : 0|8@1+ (1,0) [0|255] "count" Vector__XXX

BO_ 2566835117 OBC_DM02: 42 Vector__XXX
 SG_ FECA_10_SPNConversionMethod : 335|1@1+ (1,0) [0|1] "" Vector__XXX
 SG_ FECA_10_SPN3 : 325|3@1+ (1,0) [0|7] "" Vector__XXX
 SG_ FECA_10_SPN1_2 : 304|16@1+ (1,0) [0|65535] "" Vector__XXX
 SG_ FECA_10_OccurenceCount : 328|7@1+ (1,0) [0|127] "" Vector__XXX
 SG_ FECA_10_FMI : 320|5@1+ (1,0) [0|31] "" Vector__XXX
 SG_ FECA_09_SPNConversionMethod : 303|1@1+ (1,0) [0|1] "" Vector__XXX
 SG_ FECA_09_SPN3 : 293|3@1+ (1,0) [0|7] "" Vector__XXX
 SG_ FECA_09_SPN1_2 : 272|16@1+ (1,0) [0|65535] "" Vector__XXX
 SG_ FECA_09_OccurenceCount : 296|7@1+ (1,0) [0|127] "" Vector__XXX
 SG_ FECA_09_FMI : 288|5@1+ (1,0) [0|31] "" Vector__XXX
 SG_ FECA_08_SPNConversionMethod : 271|1@1+ (1,0) [0|1] "" Vector__XXX
 SG_ FECA_08_SPN3 : 261|3@1+ (1,0) [0|7] "" Vector__XXX
 SG_ FECA_08_SPN1_2 : 240|16@1+ (1,0) [0|65535] "" Vector__XXX
 SG_ FECA_08_OccurenceCount : 264|7@1+ (1,0) [0|127] "" Vector__XXX
 SG_ FECA_08_FMI : 256|5@1+ (1,0) [0|31] "" Vector__XXX
 SG_ FECA_07_SPNConversionMethod : 239|1@1+ (1,0) [0|1] "" Vector__XXX
 SG_ FECA_07_SPN3 : 229|3@1+ (1,0) [0|7] "" Vector__XXX
 SG_ FECA_07_SPN1_2 : 208|16@1+ (1,0) [0|65535] "" Vector__XXX
 SG_ FECA_07_OccurenceCount : 232|7@1+ (1,0) [0|127] "" Vector__XXX
 SG_ FECA_07_FMI : 224|5@1+ (1,0) [0|31] "" Vector__XXX
 SG_ FECA_06_SPNConversionMethod : 207|1@1+ (1,0) [0|1] "" Vector__XXX
 SG_ FECA_06_SPN3 : 197|3@1+ (1,0) [0|7] "" Vector__XXX
 SG_ FECA_06_SPN1_2 : 176|16@1+ (1,0) [0|65535] "" Vector__XXX
 SG_ FECA_06_OccurenceCount : 200|7@1+ (1,0) [0|127] "" Vector__XXX
 SG_ FECA_06_FMI : 192|5@1+ (1,0) [0|31] "" Vector__XXX
 SG_ FECA_05_SPNConversionMethod : 175|1@1+ (1,0) [0|1] "" Vector__XXX
 SG_ FECA_05_SPN3 : 165|3@1+ (1,0) [0|7] "" Vector__XXX
 SG_ FECA_05_SPN1_2 : 144|16@1+ (1,0) [0|65535] "" Vector__XXX
 SG_ FECA_05_OccurenceCount : 168|7@1+ (1,0) [0|127] "" Vector__XXX
 SG_ FECA_05_FMI : 160|5@1+ (1,0) [0|31] "" Vector__XXX
 SG_ FECA_04_SPNConversionMethod : 143|1@1+ (1,0) [0|1] "" Vector__XXX
 SG_ FECA_04_SPN3 : 133|3@1+ (1,0) [0|7] "" Vector__XXX
 SG_ FECA_04_SPN1_2 : 112|16@1+ (1,0) [0|65535] "" Vector__XXX
 SG_ FECA_04_OccurenceCount : 136|7@1+ (1,0) [0|127] "" Vector__XXX
 SG_ FECA_04_FMI : 128|5@1+ (1,0) [0|31] "" Vector__XXX
 SG_ FECA_03_SPNConversionMethod : 111|1@1+ (1,0) [0|1] "" Vector__XXX
 SG_ FECA_03_SPN3 : 101|3@1+ (1,0) [0|7] "" Vector__XXX
 SG_ FECA_03_SPN1_2 : 80|16@1+ (1,0) [0|65535] "" Vector__XXX
 SG_ FECA_03_OccurenceCount : 104|7@1+ (1,0) [0|127] "" Vector__XXX
 SG_ FECA_03_FMI : 96|5@1+ (1,0) [0|31] "" Vector__XXX
 SG_ FECA_02_SPNConversionMethod : 79|1@1+ (1,0) [0|1] "" Vector__XXX
 SG_ FECA_02_SPN3 : 69|3@1+ (1,0) [0|7] "" Vector__XXX
 SG_ FECA_02_SPN1_2 : 48|16@1+ (1,0) [0|65535] "" Vector__XXX
 SG_ FECA_02_OccurenceCount : 72|7@1+ (1,0) [0|127] "" Vector__XXX
 SG_ FECA_02_FMI : 64|5@1+ (1,0) [0|31] "" Vector__XXX
 SG_ FECA_01_SPNConversionMethod : 47|1@1+ (1,0) [0|1] "" Vector__XXX
 SG_ FECA_01_SPN3 : 37|3@1+ (1,0) [0|7] "" Vector__XXX
 SG_ FECA_01_SPN1_2 : 16|16@1+ (1,0) [0|65535] "" Vector__XXX
 SG_ FECA_01_RedStopLampStatus : 4|2@1+ (1,0) [0|3] "" Vector__XXX
 SG_ FECA_01_ProtectLampStatus : 0|2@1+ (1,0) [0|3] "" Vector__XXX
 SG_ FECA_01_OccurenceCount : 40|7@1+ (1,0) [0|127] "" Vector__XXX
 SG_ FECA_01_MalFucIndicatorStatus : 6|2@1+ (1,0) [0|3] "" Vector__XXX
 SG_ FECA_01_FMI : 32|5@1+ (1,0) [0|31] "" Vector__XXX
 SG_ FECA_01_FlashRedStopLamp : 12|2@1+ (1,0) [0|3] "" Vector__XXX
 SG_ FECA_01_FlashProtectLamp : 8|2@1+ (1,0) [0|3] "" Vector__XXX
 SG_ FECA_01_FlashAmberLamp : 10|2@1+ (1,0) [0|3] "" Vector__XXX
 SG_ FECA_01_Flash_MalFuncIndiLamp : 14|2@1+ (1,0) [0|3] "" Vector__XXX
 SG_ FECA_01_AmberWarmingLampStatus : 2|2@1+ (1,0) [0|3] "" Vector__XXX

BO_ 2566834861 OBC_DM01: 42 Vector__XXX
 SG_ FECA_10_SPNConversionMethod : 335|1@1+ (1,0) [0|1] "" Vector__XXX
 SG_ FECA_10_SPN3 : 325|3@1+ (1,0) [0|7] "" Vector__XXX
 SG_ FECA_10_SPN1_2 : 304|16@1+ (1,0) [0|65535] "" Vector__XXX
 SG_ FECA_10_OccurenceCount : 328|7@1+ (1,0) [0|127] "" Vector__XXX
 SG_ FECA_10_FMI : 320|5@1+ (1,0) [0|31] "" Vector__XXX
 SG_ FECA_09_SPNConversionMethod : 303|1@1+ (1,0) [0|1] "" Vector__XXX
 SG_ FECA_09_SPN3 : 293|3@1+ (1,0) [0|7] "" Vector__XXX
 SG_ FECA_09_SPN1_2 : 272|16@1+ (1,0) [0|65535] "" Vector__XXX
 SG_ FECA_09_OccurenceCount : 296|7@1+ (1,0) [0|127] "" Vector__XXX
 SG_ FECA_09_FMI : 288|5@1+ (1,0) [0|31] "" Vector__XXX
 SG_ FECA_08_SPNConversionMethod : 271|1@1+ (1,0) [0|1] "" Vector__XXX
 SG_ FECA_08_SPN3 : 261|3@1+ (1,0) [0|7] "" Vector__XXX
 SG_ FECA_08_SPN1_2 : 240|16@1+ (1,0) [0|65535] "" Vector__XXX
 SG_ FECA_08_OccurenceCount : 264|7@1+ (1,0) [0|127] "" Vector__XXX
 SG_ FECA_08_FMI : 256|5@1+ (1,0) [0|31] "" Vector__XXX
 SG_ FECA_07_SPNConversionMethod : 239|1@1+ (1,0) [0|1] "" Vector__XXX
 SG_ FECA_07_SPN3 : 229|3@1+ (1,0) [0|7] "" Vector__XXX
 SG_ FECA_07_SPN1_2 : 208|16@1+ (1,0) [0|65535] "" Vector__XXX
 SG_ FECA_07_OccurenceCount : 232|7@1+ (1,0) [0|127] "" Vector__XXX
 SG_ FECA_07_FMI : 224|5@1+ (1,0) [0|31] "" Vector__XXX
 SG_ FECA_06_SPNConversionMethod : 207|1@1+ (1,0) [0|1] "" Vector__XXX
 SG_ FECA_06_SPN3 : 197|3@1+ (1,0) [0|7] "" Vector__XXX
 SG_ FECA_06_SPN1_2 : 176|16@1+ (1,0) [0|65535] "" Vector__XXX
 SG_ FECA_06_OccurenceCount : 200|7@1+ (1,0) [0|127] "" Vector__XXX
 SG_ FECA_06_FMI : 192|5@1+ (1,0) [0|31] "" Vector__XXX
 SG_ FECA_05_SPNConversionMethod : 175|1@1+ (1,0) [0|1] "" Vector__XXX
 SG_ FECA_05_SPN3 : 165|3@1+ (1,0) [0|7] "" Vector__XXX
 SG_ FECA_05_SPN1_2 : 144|16@1+ (1,0) [0|65535] "" Vector__XXX
 SG_ FECA_05_OccurenceCount : 168|7@1+ (1,0) [0|127] "" Vector__XXX
 SG_ FECA_05_FMI : 160|5@1+ (1,0) [0|31] "" Vector__XXX
 SG_ FECA_04_SPNConversionMethod : 143|1@1+ (1,0) [0|1] "" Vector__XXX
 SG_ FECA_04_SPN3 : 133|3@1+ (1,0) [0|7] "" Vector__XXX
 SG_ FECA_04_SPN1_2 : 112|16@1+ (1,0) [0|65535] "" Vector__XXX
 SG_ FECA_04_OccurenceCount : 136|7@1+ (1,0) [0|127] "" Vector__XXX
 SG_ FECA_04_FMI : 128|5@1+ (1,0) [0|31] "" Vector__XXX
 SG_ FECA_03_SPNConversionMethod : 111|1@1+ (1,0) [0|1] "" Vector__XXX
 SG_ FECA_03_SPN3 : 101|3@1+ (1,0) [0|7] "" Vector__XXX
 SG_ FECA_03_SPN1_2 : 80|16@1+ (1,0) [0|65535] "" Vector__XXX
 SG_ FECA_03_OccurenceCount : 104|7@1+ (1,0) [0|127] "" Vector__XXX
 SG_ FECA_03_FMI : 96|5@1+ (1,0) [0|31] "" Vector__XXX
 SG_ FECA_02_SPNConversionMethod : 79|1@1+ (1,0) [0|1] "" Vector__XXX
 SG_ FECA_02_SPN3 : 69|3@1+ (1,0) [0|7] "" Vector__XXX
 SG_ FECA_02_SPN1_2 : 48|16@1+ (1,0) [0|65535] "" Vector__XXX
 SG_ FECA_02_OccurenceCount : 72|7@1+ (1,0) [0|127] "" Vector__XXX
 SG_ FECA_02_FMI : 64|5@1+ (1,0) [0|31] "" Vector__XXX
 SG_ FECA_01_SPNConversionMethod : 47|1@1+ (1,0) [0|1] "" Vector__XXX
 SG_ FECA_01_SPN3 : 37|3@1+ (1,0) [0|7] "" Vector__XXX
 SG_ FECA_01_SPN1_2 : 16|16@1+ (1,0) [0|65535] "" Vector__XXX
 SG_ FECA_01_RedStopLampStatus : 4|2@1+ (1,0) [0|3] "" Vector__XXX
 SG_ FECA_01_ProtectLampStatus : 0|2@1+ (1,0) [0|3] "" Vector__XXX
 SG_ FECA_01_OccurenceCount : 40|7@1+ (1,0) [0|127] "" Vector__XXX
 SG_ FECA_01_MalFucIndicatorStatus : 6|2@1+ (1,0) [0|3] "" Vector__XXX
 SG_ FECA_01_FMI : 32|5@1+ (1,0) [0|31] "" Vector__XXX
 SG_ FECA_01_FlashRedStopLamp : 12|2@1+ (1,0) [0|3] "" Vector__XXX
 SG_ FECA_01_FlashProtectLamp : 8|2@1+ (1,0) [0|3] "" Vector__XXX
 SG_ FECA_01_FlashAmberLamp : 10|2@1+ (1,0) [0|3] "" Vector__XXX
 SG_ FECA_01_Flash_MalFuncIndiLamp : 14|2@1+ (1,0) [0|3] "" Vector__XXX
 SG_ FECA_01_AmberWarmingLampStatus : 2|2@1+ (1,0) [0|3] "" Vector__XXX

BO_ 2566835187 BMS_DM02: 42 Vector__XXX
 SG_ FECA_10_SPNConversionMethod : 335|1@1+ (1,0) [0|1] "" Vector__XXX
 SG_ FECA_10_SPN3 : 325|3@1+ (1,0) [0|7] "" Vector__XXX
 SG_ FECA_10_SPN1_2 : 304|16@1+ (1,0) [0|65535] "" Vector__XXX
 SG_ FECA_10_OccurenceCount : 328|7@1+ (1,0) [0|127] "" Vector__XXX
 SG_ FECA_10_FMI : 320|5@1+ (1,0) [0|31] "" Vector__XXX
 SG_ FECA_09_SPNConversionMethod : 303|1@1+ (1,0) [0|1] "" Vector__XXX
 SG_ FECA_09_SPN3 : 293|3@1+ (1,0) [0|7] "" Vector__XXX
 SG_ FECA_09_SPN1_2 : 272|16@1+ (1,0) [0|65535] "" Vector__XXX
 SG_ FECA_09_OccurenceCount : 296|7@1+ (1,0) [0|127] "" Vector__XXX
 SG_ FECA_09_FMI : 288|5@1+ (1,0) [0|31] "" Vector__XXX
 SG_ FECA_08_SPNConversionMethod : 271|1@1+ (1,0) [0|1] "" Vector__XXX
 SG_ FECA_08_SPN3 : 261|3@1+ (1,0) [0|7] "" Vector__XXX
 SG_ FECA_08_SPN1_2 : 240|16@1+ (1,0) [0|65535] "" Vector__XXX
 SG_ FECA_08_OccurenceCount : 264|7@1+ (1,0) [0|127] "" Vector__XXX
 SG_ FECA_08_FMI : 256|5@1+ (1,0) [0|31] "" Vector__XXX
 SG_ FECA_07_SPNConversionMethod : 239|1@1+ (1,0) [0|1] "" Vector__XXX
 SG_ FECA_07_SPN3 : 229|3@1+ (1,0) [0|7] "" Vector__XXX
 SG_ FECA_07_SPN1_2 : 208|16@1+ (1,0) [0|65535] "" Vector__XXX
 SG_ FECA_07_OccurenceCount : 232|7@1+ (1,0) [0|127] "" Vector__XXX
 SG_ FECA_07_FMI : 224|5@1+ (1,0) [0|31] "" Vector__XXX
 SG_ FECA_06_SPNConversionMethod : 207|1@1+ (1,0) [0|1] "" Vector__XXX
 SG_ FECA_06_SPN3 : 197|3@1+ (1,0) [0|7] "" Vector__XXX
 SG_ FECA_06_SPN1_2 : 176|16@1+ (1,0) [0|65535] "" Vector__XXX
 SG_ FECA_06_OccurenceCount : 200|7@1+ (1,0) [0|127] "" Vector__XXX
 SG_ FECA_06_FMI : 192|5@1+ (1,0) [0|31] "" Vector__XXX
 SG_ FECA_05_SPNConversionMethod : 175|1@1+ (1,0) [0|1] "" Vector__XXX
 SG_ FECA_05_SPN3 : 165|3@1+ (1,0) [0|7] "" Vector__XXX
 SG_ FECA_05_SPN1_2 : 144|16@1+ (1,0) [0|65535] "" Vector__XXX
 SG_ FECA_05_OccurenceCount : 168|7@1+ (1,0) [0|127] "" Vector__XXX
 SG_ FECA_05_FMI : 160|5@1+ (1,0) [0|31] "" Vector__XXX
 SG_ FECA_04_SPNConversionMethod : 143|1@1+ (1,0) [0|1] "" Vector__XXX
 SG_ FECA_04_SPN3 : 133|3@1+ (1,0) [0|7] "" Vector__XXX
 SG_ FECA_04_SPN1_2 : 112|16@1+ (1,0) [0|65535] "" Vector__XXX
 SG_ FECA_04_OccurenceCount : 136|7@1+ (1,0) [0|127] "" Vector__XXX
 SG_ FECA_04_FMI : 128|5@1+ (1,0) [0|31] "" Vector__XXX
 SG_ FECA_03_SPNConversionMethod : 111|1@1+ (1,0) [0|1] "" Vector__XXX
 SG_ FECA_03_SPN3 : 101|3@1+ (1,0) [0|7] "" Vector__XXX
 SG_ FECA_03_SPN1_2 : 80|16@1+ (1,0) [0|65535] "" Vector__XXX
 SG_ FECA_03_OccurenceCount : 104|7@1+ (1,0) [0|127] "" Vector__XXX
 SG_ FECA_03_FMI : 96|5@1+ (1,0) [0|31] "" Vector__XXX
 SG_ FECA_02_SPNConversionMethod : 79|1@1+ (1,0) [0|1] "" Vector__XXX
 SG_ FECA_02_SPN3 : 69|3@1+ (1,0) [0|7] "" Vector__XXX
 SG_ FECA_02_SPN1_2 : 48|16@1+ (1,0) [0|65535] "" Vector__XXX
 SG_ FECA_02_OccurenceCount : 72|7@1+ (1,0) [0|127] "" Vector__XXX
 SG_ FECA_02_FMI : 64|5@1+ (1,0) [0|31] "" Vector__XXX
 SG_ FECA_01_SPNConversionMethod : 47|1@1+ (1,0) [0|1] "" Vector__XXX
 SG_ FECA_01_SPN3 : 37|3@1+ (1,0) [0|7] "" Vector__XXX
 SG_ FECA_01_SPN1_2 : 16|16@1+ (1,0) [0|65535] "" Vector__XXX
 SG_ FECA_01_RedStopLampStatus : 4|2@1+ (1,0) [0|3] "" Vector__XXX
 SG_ FECA_01_ProtectLampStatus : 0|2@1+ (1,0) [0|3] "" Vector__XXX
 SG_ FECA_01_OccurenceCount : 40|7@1+ (1,0) [0|127] "" Vector__XXX
 SG_ FECA_01_MalFucIndicatorStatus : 6|2@1+ (1,0) [0|3] "" Vector__XXX
 SG_ FECA_01_FMI : 32|5@1+ (1,0) [0|31] "" Vector__XXX
 SG_ FECA_01_FlashRedStopLamp : 12|2@1+ (1,0) [0|3] "" Vector__XXX
 SG_ FECA_01_FlashProtectLamp : 8|2@1+ (1,0) [0|3] "" Vector__XXX
 SG_ FECA_01_FlashAmberLamp : 10|2@1+ (1,0) [0|3] "" Vector__XXX
 SG_ FECA_01_Flash_MalFuncIndiLamp : 14|2@1+ (1,0) [0|3] "" Vector__XXX
 SG_ FECA_01_AmberWarmingLampStatus : 2|2@1+ (1,0) [0|3] "" Vector__XXX

BO_ 2566834931 BMS_DM01: 42 Vector__XXX
 SG_ FECA_10_SPNConversionMethod : 335|1@1+ (1,0) [0|1] "" Vector__XXX
 SG_ FECA_10_SPN3 : 325|3@1+ (1,0) [0|7] "" Vector__XXX
 SG_ FECA_10_SPN1_2 : 304|16@1+ (1,0) [0|65535] "" Vector__XXX
 SG_ FECA_10_OccurenceCount : 328|7@1+ (1,0) [0|127] "" Vector__XXX
 SG_ FECA_10_FMI : 320|5@1+ (1,0) [0|31] "" Vector__XXX
 SG_ FECA_09_SPNConversionMethod : 303|1@1+ (1,0) [0|1] "" Vector__XXX
 SG_ FECA_09_SPN3 : 293|3@1+ (1,0) [0|7] "" Vector__XXX
 SG_ FECA_09_SPN1_2 : 272|16@1+ (1,0) [0|65535] "" Vector__XXX
 SG_ FECA_09_OccurenceCount : 296|7@1+ (1,0) [0|127] "" Vector__XXX
 SG_ FECA_09_FMI : 288|5@1+ (1,0) [0|31] "" Vector__XXX
 SG_ FECA_08_SPNConversionMethod : 271|1@1+ (1,0) [0|1] "" Vector__XXX
 SG_ FECA_08_SPN3 : 261|3@1+ (1,0) [0|7] "" Vector__XXX
 SG_ FECA_08_SPN1_2 : 240|16@1+ (1,0) [0|65535] "" Vector__XXX
 SG_ FECA_08_OccurenceCount : 264|7@1+ (1,0) [0|127] "" Vector__XXX
 SG_ FECA_08_FMI : 256|5@1+ (1,0) [0|31] "" Vector__XXX
 SG_ FECA_07_SPNConversionMethod : 239|1@1+ (1,0) [0|1] "" Vector__XXX
 SG_ FECA_07_SPN3 : 229|3@1+ (1,0) [0|7] "" Vector__XXX
 SG_ FECA_07_SPN1_2 : 208|16@1+ (1,0) [0|65535] "" Vector__XXX
 SG_ FECA_07_OccurenceCount : 232|7@1+ (1,0) [0|127] "" Vector__XXX
 SG_ FECA_07_FMI : 224|5@1+ (1,0) [0|31] "" Vector__XXX
 SG_ FECA_06_SPNConversionMethod : 207|1@1+ (1,0) [0|1] "" Vector__XXX
 SG_ FECA_06_SPN3 : 197|3@1+ (1,0) [0|7] "" Vector__XXX
 SG_ FECA_06_SPN1_2 : 176|16@1+ (1,0) [0|65535] "" Vector__XXX
 SG_ FECA_06_OccurenceCount : 200|7@1+ (1,0) [0|127] "" Vector__XXX
 SG_ FECA_06_FMI : 192|5@1+ (1,0) [0|31] "" Vector__XXX
 SG_ FECA_05_SPNConversionMethod : 175|1@1+ (1,0) [0|1] "" Vector__XXX
 SG_ FECA_05_SPN3 : 165|3@1+ (1,0) [0|7] "" Vector__XXX
 SG_ FECA_05_SPN1_2 : 144|16@1+ (1,0) [0|65535] "" Vector__XXX
 SG_ FECA_05_OccurenceCount : 168|7@1+ (1,0) [0|127] "" Vector__XXX
 SG_ FECA_05_FMI : 160|5@1+ (1,0) [0|31] "" Vector__XXX
 SG_ FECA_04_SPNConversionMethod : 143|1@1+ (1,0) [0|1] "" Vector__XXX
 SG_ FECA_04_SPN3 : 133|3@1+ (1,0) [0|7] "" Vector__XXX
 SG_ FECA_04_SPN1_2 : 112|16@1+ (1,0) [0|65535] "" Vector__XXX
 SG_ FECA_04_OccurenceCount : 136|7@1+ (1,0) [0|127] "" Vector__XXX
 SG_ FECA_04_FMI : 128|5@1+ (1,0) [0|31] "" Vector__XXX
 SG_ FECA_03_SPNConversionMethod : 111|1@1+ (1,0) [0|1] "" Vector__XXX
 SG_ FECA_03_SPN3 : 101|3@1+ (1,0) [0|7] "" Vector__XXX
 SG_ FECA_03_SPN1_2 : 80|16@1+ (1,0) [0|65535] "" Vector__XXX
 SG_ FECA_03_OccurenceCount : 104|7@1+ (1,0) [0|127] "" Vector__XXX
 SG_ FECA_03_FMI : 96|5@1+ (1,0) [0|31] "" Vector__XXX
 SG_ FECA_02_SPNConversionMethod : 79|1@1+ (1,0) [0|1] "" Vector__XXX
 SG_ FECA_02_SPN3 : 69|3@1+ (1,0) [0|7] "" Vector__XXX
 SG_ FECA_02_SPN1_2 : 48|16@1+ (1,0) [0|65535] "" Vector__XXX
 SG_ FECA_02_OccurenceCount : 72|7@1+ (1,0) [0|127] "" Vector__XXX
 SG_ FECA_02_FMI : 64|5@1+ (1,0) [0|31] "" Vector__XXX
 SG_ FECA_01_SPNConversionMethod : 47|1@1+ (1,0) [0|1] "" Vector__XXX
 SG_ FECA_01_SPN3 : 37|3@1+ (1,0) [0|7] "" Vector__XXX
 SG_ FECA_01_SPN1_2 : 16|16@1+ (1,0) [0|65535] "" Vector__XXX
 SG_ FECA_01_RedStopLampStatus : 4|2@1+ (1,0) [0|3] "" Vector__XXX
 SG_ FECA_01_ProtectLampStatus : 0|2@1+ (1,0) [0|3] "" Vector__XXX
 SG_ FECA_01_OccurenceCount : 40|7@1+ (1,0) [0|127] "" Vector__XXX
 SG_ FECA_01_MalFucIndicatorStatus : 6|2@1+ (1,0) [0|3] "" Vector__XXX
 SG_ FECA_01_FMI : 32|5@1+ (1,0) [0|31] "" Vector__XXX
 SG_ FECA_01_FlashRedStopLamp : 12|2@1+ (1,0) [0|3] "" Vector__XXX
 SG_ FECA_01_FlashProtectLamp : 8|2@1+ (1,0) [0|3] "" Vector__XXX
 SG_ FECA_01_FlashAmberLamp : 10|2@1+ (1,0) [0|3] "" Vector__XXX
 SG_ FECA_01_Flash_MalFuncIndiLamp : 14|2@1+ (1,0) [0|3] "" Vector__XXX
 SG_ FECA_01_AmberWarmingLampStatus : 2|2@1+ (1,0) [0|3] "" Vector__XXX

BO_ 2365544016 Keypad_KEYPADMI1: 8 Vector__XXX
 SG_ FF56_AutoIdle_Left_Indi : 58|2@1+ (1,0) [0|3] "" Vector__XXX
 SG_ FF56_AutoIdle_Center_Indi : 56|2@1+ (1,0) [0|3] "" Vector__XXX
 SG_ FF56_AutoIdle_Right_Indi : 54|2@1+ (1,0) [0|3] "" Vector__XXX
 SG_ FF56_Power_Mode_Left_Indi : 16|2@1+ (1,0) [0|3] "" Vector__XXX
 SG_ FF56_Power_Mode_Center_Indi : 14|2@1+ (1,0) [0|3] "" Vector__XXX
 SG_ FF56_Power_Mode_Right_Indi : 12|2@1+ (1,0) [0|3] "" Vector__XXX
 SG_ FF56_Travel_Alarm_Left_Indi : 10|2@1+ (1,0) [0|3] "" Vector__XXX
 SG_ FF56_Travel_Alarm_Center_Indi : 8|2@1+ (1,0) [0|3] "" Vector__XXX
 SG_ FF56_Travel_Alarm_Right_Indi : 6|2@1+ (1,0) [0|3] "" Vector__XXX
 SG_ FF56_OWD_Left_Indi : 4|2@1+ (1,0) [0|3] "" Vector__XXX
 SG_ FF56_OWD_Center_Indi : 2|2@1+ (1,0) [0|3] "" Vector__XXX
 SG_ FF56_OWD_Right_Indi : 0|2@1+ (1,0) [0|3] "" Vector__XXX
 SG_ FF56_WorkModeRight : 18|2@1- (1,0) [-2|1] "" Vector__XXX
 SG_ FF56_WorkModeLeft : 22|2@1- (1,0) [-2|1] "" Vector__XXX
 SG_ FF56_WorkModeCenter : 20|2@1- (1,0) [-2|1] "" Vector__XXX
 SG_ FF56_TrailerHitchBrakeRight : 36|2@1- (1,0) [-2|1] "" Vector__XXX
 SG_ FF56_TrailerHitchBrakeLeft : 40|2@1- (1,0) [-2|1] "" Vector__XXX
 SG_ FF56_TrailerHitchBrakeCenter : 38|2@1- (1,0) [-2|1] "" Vector__XXX
 SG_ FF56_JoystickSteeringRight : 48|2@1- (1,0) [-2|1] "" Vector__XXX
 SG_ FF56_JoystickSteeringLeft : 52|2@1- (1,0) [-2|1] "" Vector__XXX
 SG_ FF56_JoystickSteeringCenter : 50|2@1- (1,0) [-2|1] "" Vector__XXX
 SG_ FF56_FineSwingRight : 42|2@1- (1,0) [-2|1] "" Vector__XXX
 SG_ FF56_FineSwingLeft : 46|2@1- (1,0) [-2|1] "" Vector__XXX
 SG_ FF56_FineSwingCenter : 44|2@1- (1,0) [-2|1] "" Vector__XXX
 SG_ FF56_BoomSwingModeRight : 24|2@1- (1,0) [-2|1] "" Vector__XXX
 SG_ FF56_BoomSwingModeLeft : 28|2@1- (1,0) [-2|1] "" Vector__XXX
 SG_ FF56_BoomSwingModeCenter : 26|2@1- (1,0) [-2|1] "" Vector__XXX
 SG_ FF56_AutoHoldBrakeRight : 30|2@1- (1,0) [-2|1] "" Vector__XXX
 SG_ ZFENG_ESLC : 32|4@1+ (1,0) [0|15] "" Vector__XXX

BO_ 2566871376 Keypad_KEYPADI3: 8 Vector__XXX
 SG_ FF59_Indicate_Wiper_Front_R : 48|2@1+ (1,0) [0|3] "" Vector__XXX
 SG_ FF59_Indicate_Wiper_Front_L : 52|2@1+ (1,0) [0|3] "" Vector__XXX
 SG_ FF59_Indicate_Wiper_Front_C : 50|2@1+ (1,0) [0|3] "" Vector__XXX
 SG_ FF59_Indicate_Wiper_Rear_R : 42|2@1+ (1,0) [0|3] "" Vector__XXX
 SG_ FF59_Indicate_Wiper_Rear_L : 46|2@1+ (1,0) [0|3] "" Vector__XXX
 SG_ FF59_Indicate_Wiper_Rear_C : 44|2@1+ (1,0) [0|3] "" Vector__XXX
 SG_ FF59_Indicate_Wiper_Side_R : 36|2@1+ (1,0) [0|3] "" Vector__XXX
 SG_ FF59_Indicate_Wiper_Side_L : 40|2@1+ (1,0) [0|3] "" Vector__XXX
 SG_ FF59_Indicate_Wiper_Side_C : 38|2@1+ (1,0) [0|3] "" Vector__XXX
 SG_ FF59_Indicate_Washer_Front_R : 30|2@1+ (1,0) [0|3] "" Vector__XXX
 SG_ FF59_Indicate_Washer_Front_L : 34|2@1+ (1,0) [0|3] "" Vector__XXX
 SG_ FF59_Indicate_Washer_Front_C : 32|2@1+ (1,0) [0|3] "" Vector__XXX
 SG_ FF59_Indicate_Washer_Side_R : 24|2@1+ (1,0) [0|3] "" Vector__XXX
 SG_ FF59_Indicate_Washer_Side_L : 28|2@1+ (1,0) [0|3] "" Vector__XXX
 SG_ FF59_Indicate_Washer_Side_C : 26|2@1+ (1,0) [0|3] "" Vector__XXX
 SG_ FF59_Indicate_AirComp_R : 12|2@1+ (1,0) [0|3] "" Vector__XXX
 SG_ FF59_Indicate_AirComp_L : 16|2@1+ (1,0) [0|3] "" Vector__XXX
 SG_ FF59_Indicate_AirComp_C : 14|2@1+ (1,0) [0|3] "" Vector__XXX
 SG_ FF59_Indicate_TraveSpeed_R : 6|2@1+ (1,0) [0|3] "" Vector__XXX
 SG_ FF59_Indicate_TraveSpeed_L : 10|2@1+ (1,0) [0|3] "" Vector__XXX
 SG_ FF59_Indicate_TraveSpeed_C : 8|2@1+ (1,0) [0|3] "" Vector__XXX
 SG_ FF59_Indicate_BuzzerStop_R : 0|2@1+ (1,0) [0|3] "" Vector__XXX
 SG_ FF59_Indicate_BuzzerStop_L : 4|2@1+ (1,0) [0|3] "" Vector__XXX
 SG_ FF59_Indicate_BuzzerStop_C : 2|2@1+ (1,0) [0|3] "" Vector__XXX

BO_ 2365544528 Keypad_KEYPADI2: 8 Vector__XXX
 SG_ FF58_ThrLockUpLeIndcr : 22|2@1+ (1,0) [0|3] "" Vector__XXX
 SG_ FF58_ThrLockUpCtrIndcr : 20|2@1+ (1,0) [0|3] "" Vector__XXX
 SG_ FF58_ThrLockUpRiIndcr : 18|2@1+ (1,0) [0|3] "" Vector__XXX
 SG_ FF58_TracCtrlModLeIndcr : 16|2@1+ (1,0) [0|3] "" Vector__XXX
 SG_ FF58_TracCtrlModCtrIndcr : 14|2@1+ (1,0) [0|3] "" Vector__XXX
 SG_ FF58_TracCtrlModRiIndcr : 12|2@1+ (1,0) [0|3] "" Vector__XXX
 SG_ FF58_VblSpdDwnLeIndcr : 10|2@1+ (1,0) [0|3] "" Vector__XXX
 SG_ FF58_VblSpdDwnCtrIndcr : 8|2@1+ (1,0) [0|3] "" Vector__XXX
 SG_ FF58_VblSpdDwnRiIndcr : 6|2@1+ (1,0) [0|3] "" Vector__XXX
 SG_ FF58_VblSpdUpLeIndcr : 4|2@1+ (1,0) [0|3] "" Vector__XXX
 SG_ FF58_VblSpdUpCtrIndcr : 2|2@1+ (1,0) [0|3] "" Vector__XXX
 SG_ FF58_VblSpdUpRiIndcr : 0|2@1+ (1,0) [0|3] "" Vector__XXX

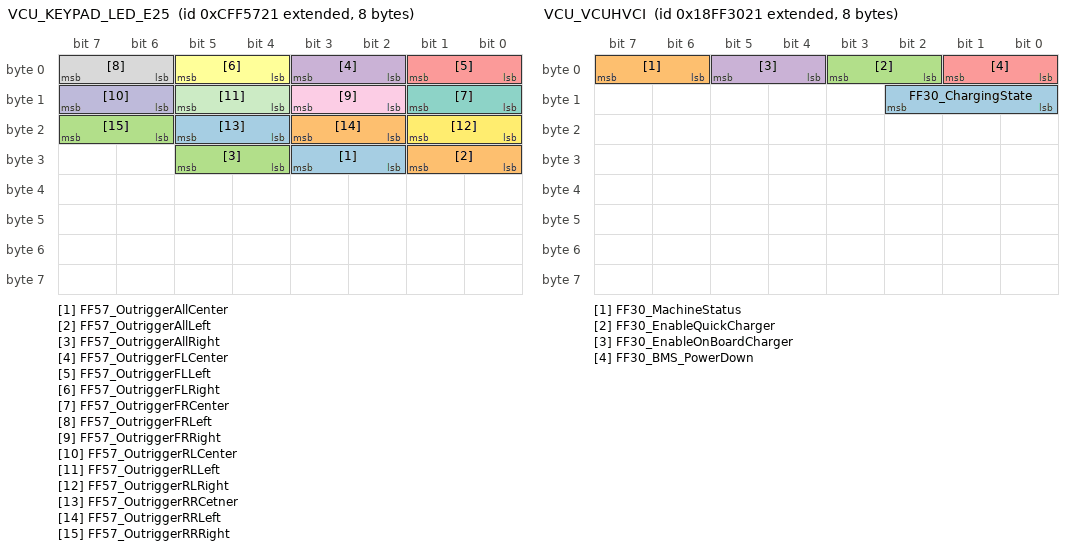
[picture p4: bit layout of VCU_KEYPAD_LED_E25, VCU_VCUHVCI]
BO_ 2365544225 VCU_KEYPAD_LED_E25: 8 Vector__XXX
 SG_ FF57_OutriggerAllCenter : 26|2@1+ (1,0) [0|3] "" Vector__XXX
 SG_ FF57_OutriggerAllLeft : 24|2@1+ (1,0) [0|3] "" Vector__XXX
 SG_ FF57_OutriggerAllRight : 28|2@1+ (1,0) [0|3] "" Vector__XXX
 SG_ FF57_OutriggerFLCenter : 2|2@1+ (1,0) [0|3] "" Vector__XXX
 SG_ FF57_OutriggerFLLeft : 0|2@1+ (1,0) [0|3] "" Vector__XXX
 SG_ FF57_OutriggerFLRight : 4|2@1+ (1,0) [0|3] "" Vector__XXX
 SG_ FF57_OutriggerFRCenter : 8|2@1+ (1,0) [0|3] "" Vector__XXX
 SG_ FF57_OutriggerFRLeft : 6|2@1+ (1,0) [0|3] "" Vector__XXX
 SG_ FF57_OutriggerFRRight : 10|2@1+ (1,0) [0|3] "" Vector__XXX
 SG_ FF57_OutriggerRLCenter : 14|2@1+ (1,0) [0|3] "" Vector__XXX
 SG_ FF57_OutriggerRLLeft : 12|2@1+ (1,0) [0|3] "" Vector__XXX
 SG_ FF57_OutriggerRLRight : 16|2@1+ (1,0) [0|3] "" Vector__XXX
 SG_ FF57_OutriggerRRCetner : 20|2@1+ (1,0) [0|3] "" Vector__XXX
 SG_ FF57_OutriggerRRLeft : 18|2@1+ (1,0) [0|3] "" Vector__XXX
 SG_ FF57_OutriggerRRRight : 22|2@1+ (1,0) [0|3] "" Vector__XXX

BO_ 2365543760 Keypad_KEYPADI1: 8 Vector__XXX
 SG_ FF55_TrsmModeSelectRight : 36|2@1+ (1,0) [0|3] "" Vector__XXX
 SG_ FF55_TrsmModeSelectLeft : 40|2@1+ (1,0) [0|3] "" Vector__XXX
 SG_ FF55_TrsmModeSelectCenter : 38|2@1+ (1,0) [0|3] "" Vector__XXX
 SG_ FF55_TorqueConverterLockUpRight : 48|2@1+ (1,0) [0|3] "" Vector__XXX
 SG_ FF55_TorqueConverterLockUpLeft : 52|2@1+ (1,0) [0|3] "" Vector__XXX
 SG_ FF55_TorqueConverterLockUpCenter : 50|2@1+ (1,0) [0|3] "" Vector__XXX
 SG_ FF55_ClutchCutOffRight : 42|2@1+ (1,0) [0|3] "" Vector__XXX
 SG_ FF55_ClutchCutOffLeft : 46|2@1+ (1,0) [0|3] "" Vector__XXX
 SG_ FF55_ClutchCutOffCenter : 44|2@1+ (1,0) [0|3] "" Vector__XXX
 SG_ FF55_MaxSpeedDownLeft : 34|2@1+ (1,0) [0|3] "" Vector__XXX
 SG_ FF55_MaxSpeedDownCenter : 32|2@1+ (1,0) [0|3] "" Vector__XXX
 SG_ FF55_MaxSpeedDownRight : 30|2@1+ (1,0) [0|3] "" Vector__XXX
 SG_ FF55_MaxSpeedUpLeft : 28|2@1+ (1,0) [0|3] "" Vector__XXX
 SG_ FF55_MaxSpeedUpCenter : 26|2@1+ (1,0) [0|3] "" Vector__XXX
 SG_ FF55_MaxSpeedUpRight : 24|2@1+ (1,0) [0|3] "" Vector__XXX
 SG_ FF55_BucketDetentLeft : 22|2@1+ (1,0) [0|3] "" Vector__XXX
 SG_ FF55_BucketDetentCenter : 20|2@1+ (1,0) [0|3] "" Vector__XXX
 SG_ FF55_BucketDetentRight : 18|2@1+ (1,0) [0|3] "" Vector__XXX
 SG_ FF55_BoomDetentLeft : 16|2@1+ (1,0) [0|3] "" Vector__XXX
 SG_ FF55_BoomDetentCenter : 14|2@1+ (1,0) [0|3] "" Vector__XXX
 SG_ FF55_BoomDetentRight : 12|2@1+ (1,0) [0|3] "" Vector__XXX
 SG_ FF55_DiffLockEngagedLeft : 10|2@1+ (1,0) [0|3] "" Vector__XXX
 SG_ FF55_DiffLockEngagedCenter : 8|2@1+ (1,0) [0|3] "" Vector__XXX
 SG_ FF55_DiffLockEngagedRight : 6|2@1+ (1,0) [0|3] "" Vector__XXX
 SG_ FF55_ModeSelectLeft : 4|2@1+ (1,0) [0|3] "" Vector__XXX
 SG_ FF55_ModeSelectCenter : 2|2@1+ (1,0) [0|3] "" Vector__XXX
 SG_ FF55_ModeSelectRight : 0|2@1+ (1,0) [0|3] "" Vector__XXX

BO_ 2365543248 Keypad_KEYPADBI: 8 Vector__XXX
 SG_ FF53_CabinLamp_Right : 54|2@1+ (1,0) [0|3] "" Vector__XXX
 SG_ FF53_CabinLamp_Left : 58|2@1+ (1,0) [0|3] "" Vector__XXX
 SG_ FF53_CabinLamp_Center : 56|2@1+ (1,0) [0|3] "" Vector__XXX
 SG_ FF53_RearWorkingLampRight : 12|2@1+ (1,0) [0|3] "" Vector__XXX
 SG_ FF53_RearWorkingLampLeft : 16|2@1+ (1,0) [0|3] "" Vector__XXX
 SG_ FF53_RearWorkingLampCenter : 14|2@1+ (1,0) [0|3] "" Vector__XXX
 SG_ FF53_RearWiperWasherRight : 24|2@1+ (1,0) [0|3] "" Vector__XXX
 SG_ FF53_RearWiperWasherLeft : 28|2@1+ (1,0) [0|3] "" Vector__XXX
 SG_ FF53_RearWiperWasherCenter : 26|2@1+ (1,0) [0|3] "" Vector__XXX
 SG_ FF53_MirrorHeatRight : 30|2@1+ (1,0) [0|3] "" Vector__XXX
 SG_ FF53_MirrorHeatLeft : 34|2@1+ (1,0) [0|3] "" Vector__XXX
 SG_ FF53_MirrorHeatCenter : 32|2@1+ (1,0) [0|3] "" Vector__XXX
 SG_ FF53_LoadIsolationRight : 36|2@1+ (1,0) [0|3] "" Vector__XXX
 SG_ FF53_LoadIsolationLeft : 40|2@1+ (1,0) [0|3] "" Vector__XXX
 SG_ FF53_LoadIsolationCenter : 38|2@1+ (1,0) [0|3] "" Vector__XXX
 SG_ FF53_InformationRight : 48|2@1+ (1,0) [0|3] "" Vector__XXX
 SG_ FF53_InformationLeft : 52|2@1+ (1,0) [0|3] "" Vector__XXX
 SG_ FF53_InformationCenter : 50|2@1+ (1,0) [0|3] "" Vector__XXX
 SG_ FF53_HeadLampRight : 0|2@1+ (1,0) [0|3] "" Vector__XXX
 SG_ FF53_HeadLampLeft : 4|2@1+ (1,0) [0|3] "" Vector__XXX
 SG_ FF53_HeadLampCenter : 2|2@1+ (1,0) [0|3] "" Vector__XXX
 SG_ FF53_FrontWorkingLampRight : 6|2@1+ (1,0) [0|3] "" Vector__XXX
 SG_ FF53_FrontWorkingLampLeft : 10|2@1+ (1,0) [0|3] "" Vector__XXX
 SG_ FF53_FrontWorkingLampCenter : 8|2@1+ (1,0) [0|3] "" Vector__XXX
 SG_ FF53_EmergencySteeringRight : 42|2@1+ (1,0) [0|3] "" Vector__XXX
 SG_ FF53_EmergencySteeringLeft : 46|2@1+ (1,0) [0|3] "" Vector__XXX
 SG_ FF53_EmergencySteeringCenter : 44|2@1+ (1,0) [0|3] "" Vector__XXX
 SG_ FF53_BeaconLampRight : 18|2@1+ (1,0) [0|3] "" Vector__XXX
 SG_ FF53_BeaconLampLeft : 22|2@1+ (1,0) [0|3] "" Vector__XXX
 SG_ FF53_BeaconLampCenter : 20|2@1+ (1,0) [0|3] "" Vector__XXX

BO_ 2566864627 BMS_BMSSG: 8 Vector__XXX
 SG_ FF3E_ChargingState : 40|3@1+ (1,0) [0|7] "" Vector__XXX
 SG_ FF3E_HeatingPadStatus : 2|1@1+ (1,0) [0|1] "" Vector__XXX
 SG_ FF3E_EstimatedChargingTime : 48|16@1+ (1,0) [0|65535] "" Vector__XXX
 SG_ FF3E_BMSChargingSourceType : 0|2@1+ (1,0) [0|3] "" Vector__XXX

BO_ 2565820456 GP_GPSMPD: 10 Vector__XXX
 SG_ EF50_DataField : 24|48@1+ (1,0) [0|281474976710655] "" Vector__XXX
 SG_ EF50_Reserved : 19|5@1+ (1,0) [0|31] "" Vector__XXX
 SG_ EF50_SuspectParameterNumber : 0|19@1+ (1,0) [0|524287] "" Vector__XXX

BO_ 2566864680 GP_USUHDI: 65 Vector__XXX
 SG_ FF3F_DailyIdleOperatingHour : 456|32@1+ (1,0) [0|4294967295] "min" Vector__XXX
 SG_ FF3F_DailyFuelEfficiency : 440|16@1+ (1,0) [0|65535] "" Vector__XXX
 SG_ FF3F_DailyTotalOperatingHour : 408|32@1+ (1,0) [0|4211081215] "min" Vector__XXX
 SG_ FF3F_DailyFuelUsageHour : 376|32@1+ (1,0) [0|4294967295] "" Vector__XXX
 SG_ FF3F_FuelEfficiency : 360|16@1+ (1,0) [0|65535] "" Vector__XXX
 SG_ FF3F_EconomymodeFuelUsage : 328|32@1+ (1,0) [0|4294967295] "" Vector__XXX
 SG_ FF3F_StandardmodeFuelUsage : 296|32@1+ (1,0) [0|4294967295] "" Vector__XXX
 SG_ FF3F_PowermodeFuelUsage : 264|32@1+ (1,0) [0|4294967295] "" Vector__XXX
 SG_ FF3F_PowerplusmodeFuelUsage : 232|32@1+ (1,0) [0|4294967295] "" Vector__XXX
 SG_ FF3F_TotalFuelUsage : 200|32@1+ (1,0) [0|4294967295] "" Vector__XXX
 SG_ FF3F_EconomyModeOperatingHour : 168|32@1+ (1,0) [0|4211081215] "min" Vector__XXX
 SG_ FF3F_StandardModeOperatingHour : 136|32@1+ (1,0) [0|4211081215] "min" Vector__XXX
 SG_ FF3F_PowermodeOperatingHour : 104|32@1+ (1,0) [0|4211081215] "min" Vector__XXX
 SG_ FF3F_PowerPlusModeOperatingHour : 72|32@1+ (1,0) [0|4211081215] "min" Vector__XXX
 SG_ FF3F_IdleOperatingHour : 40|32@1+ (1,0) [0|4211081215] "min" Vector__XXX
 SG_ FF3F_TotlaOperatingHour : 8|32@1+ (1,0) [0|4211081215] "min" Vector__XXX
 SG_ FF3F_UserSeparator : 0|8@1+ (1,0) [0|255] "" Vector__XXX

BO_ 2566860833 VCU_VCUHVCI: 8 Vector__XXX
 SG_ FF30_ChargingState : 8|3@1+ (1,0) [0|7] "" Vector__XXX
 SG_ FF30_MachineStatus : 6|2@1+ (1,0) [0|3] "" Vector__XXX
 SG_ FF30_EnableQuickCharger : 2|2@1+ (1,0) [0|3] "" Vector__XXX
 SG_ FF30_EnableOnBoardCharger : 4|2@1+ (1,0) [0|3] "" Vector__XXX
 SG_ FF30_BMS_PowerDown : 0|2@1+ (1,0) [0|3] "" Vector__XXX

BO_ 2566839027 BMS_SOFT: 8 Vector__XXX
 SG_ FEDA_NumberOfSoftIdentifFields : 0|8@1+ (1,0) [0|250] "step" Vector__XXX

BO_ 2566723059 BMS_BCH1: 9 Vector__XXX
 SG_ FD15_Reserved : 40|32@1- (1,0) [-2147483648|2147483647] "" Vector__XXX
 SG_ FD15_Battery_Charger1_State : 0|4@1+ (1,0) [0|15] "bit" Vector__XXX
 SG_ FD15_Battery_Charger1_Pow_State : 4|4@1+ (1,0) [0|3] "bit" Vector__XXX
 SG_ FD15_Battery_Charger1_Out_Volt : 8|16@1+ (0.05,0) [0|210] "V" Vector__XXX
 SG_ FD15_Battery_Charger1_Out_Curr : 24|16@1+ (0.05,-1600) [-1600|1612.75] "A" Vector__XXX

BO_ 2566676211 BMS_HVESSHIST: 19 Vector__XXX
 SG_ HVESSHIST_TotalLifetimeEnergyOut : 120|32@1+ (1,0) [0|4211081215] "kWh" Vector__XXX
 SG_ HVESSHIST_TotalLifetimeEnergyIn : 88|32@1+ (1,0) [0|4211081215] "kWh" Vector__XXX
 SG_ HVESSHIST_TotalEnergyThroughput : 24|32@1+ (100,0) [0|421108121500] "Wh" Vector__XXX
 SG_ HVESSHIST_TotalAcculmulCharge : 56|32@1+ (100,0) [0|421108121500] "Ah" Vector__XXX
 SG_ HVESSHIST_State0fHealth : 0|8@1+ (0.4,0) [0|100] "%" Vector__XXX
 SG_ HVESSHIST_CntctrOpenUnderLoadCnt : 8|16@1+ (1,0) [0|64255] "count" Vector__XXX

BO_ 2566675955 BMS_HVESSCFG: 17 Vector__XXX
 SG_ FC5D_Recomm_Min_SOC : 48|16@1+ (0.0015625,0) [0|100.3984375] "%" Vector__XXX
 SG_ FC5D_Recomm_Min_Op_Volt : 16|16@1+ (0.05,0) [0|3212.75] "V" Vector__XXX
 SG_ FC5D_Recomm_Min_Op_Temp : 96|16@1+ (0.03125,-273) [-273|1734.96875] "กษ" Vector__XXX
 SG_ FC5D_Recomm_Max_SOC : 64|16@1+ (0.0015625,0) [0|100.3984375] "%" Vector__XXX
 SG_ FC5D_Recomm_Max_Op_Volt : 32|16@1+ (0.05,0) [0|3212.75] "V" Vector__XXX
 SG_ FC5D_Recomm_Max_Op_Temp : 80|16@1+ (0.03125,-273) [-273|1734.96875] "กษ" Vector__XXX
 SG_ FC5D_NumberOfHVESPsConfigure : 128|8@1+ (1,0) [0|250] "count" Vector__XXX
 SG_ FC5D_Nominal_Voltage : 0|16@1+ (0.05,0) [0|3212.75] "V" Vector__XXX
 SG_ FC5D_Cell_Min_Volt_Limit : 120|8@1+ (0.02044,0) [0|5.11] "V" Vector__XXX
 SG_ FC5D_Cell_Max_Volt_Limit : 112|8@1+ (0.02044,0) [0|5.11] "V" Vector__XXX

BO_ 2565904115 BMS_HVESSS1: 8 Vector__XXX
 SG_ HVESSS1_HighVoltPassivTestStatus : 16|4@1+ (1,0) [0|15] "bit" Vector__XXX
 SG_ HVESSS1_Status1_CRC : 56|8@1+ (1,0) [0|255] "count" Vector__XXX
 SG_ HVESSS1_Status1_Counter : 36|4@1+ (1,0) [0|15] "bit" Vector__XXX
 SG_ HVESSS1_SOC_Status : 24|4@1+ (1,0) [0|15] "bit" Vector__XXX
 SG_ HVESSS1_Reserved : 34|2@1- (1,0) [-2|1] "" Vector__XXX
 SG_ HVESSS1_Operational_Status : 44|4@1+ (1,0) [0|15] "bit" Vector__XXX
 SG_ HVESSS1_NumberOfHVESPsReady : 48|8@1+ (1,0) [0|250] "count" Vector__XXX
 SG_ HVESSS1_Internal_Charger_Status : 32|2@1+ (1,0) [0|3] "bit" Vector__XXX
 SG_ HVESSS1_Inertia_Switch_Status : 22|2@1+ (1,0) [0|3] "bit" Vector__XXX
 SG_ HVESSS1_HighVoltPreChrgRelayStat : 8|2@1+ (1,0) [0|3] "bit" Vector__XXX
 SG_ HVESSS1_HighVoltActiveTestStatus : 12|4@1+ (1,0) [0|15] "bit" Vector__XXX
 SG_ HVESSS1_High_Volt_P_Cntctr_State : 0|2@1+ (1,0) [0|3] "bit" Vector__XXX
 SG_ HVESSS1_High_Volt_N_Cntctr_State : 2|2@1+ (1,0) [0|3] "bit" Vector__XXX
 SG_ HVESSS1_High_Volt_Discn_Forewarn : 4|4@1+ (1,0) [0|15] "bit" Vector__XXX
 SG_ HVESSS1_High_Volt_Connect_Status : 40|4@1+ (1,0) [0|15] "bit" Vector__XXX
 SG_ HVESSS1_CenterOfPackCntctrState : 10|2@1+ (1,0) [0|3] "bit" Vector__XXX
 SG_ HVESSS1_HVIL_Status : 20|2@1+ (1,0) [0|3] "bit" Vector__XXX
 SG_ HVESSS1_Cell_Balance_Status : 28|2@1+ (1,0) [0|3] "bit" Vector__XXX
 SG_ HVESSS1_Cell_Balancing_Active : 30|2@1+ (1,0) [0|3] "bit" Vector__XXX

BO_ 2565906675 BMS_HVESSD7: 8 Vector__XXX
 SG_ F0A0_HVESS_Max_Charge_Vot_Lim : 48|16@1+ (0.05,0) [0|3212.75] "V" Vector__XXX
 SG_ F0A0_HVESS_Disch_Energy_Capacity : 0|24@1+ (0.001,0) [0|16449.535] "kWh" Vector__XXX
 SG_ F0A0_HVESS_Charg_Energy_Capacity : 24|24@1+ (0.001,0) [0|16449.535] "kWh" Vector__XXX

BO_ 2565903859 BMS_HVESSD6: 8 Vector__XXX
 SG_ F095_HVESS_Temp : 56|8@1+ (1,-40) [-40|210] "กษ" Vector__XXX
 SG_ F095_HVESS_Outlet_Coolant_Temp : 40|8@1+ (1,-40) [-40|210] "กษ" Vector__XXX
 SG_ F095_HVESS_Intanke_Coolant_Temp : 32|8@1+ (1,-40) [-40|210] "กษ" Vector__XXX
 SG_ F095_HVESS_Ignition_Voltage : 16|16@1+ (0.01,0) [0|642.55] "V" Vector__XXX
 SG_ F095_HVESS_Electro_Temp : 48|8@1+ (1,-40) [-40|210] "กษ" Vector__XXX
 SG_ F095_HVESS_Bus_Voltage : 0|16@1+ (0.05,0) [0|3212.75] "V" Vector__XXX

BO_ 2565903603 BMS_HVESSD5: 8 Vector__XXX
 SG_ F094_HVESS_Min_Cell_SOC : 32|16@1+ (0.0015625,0) [0|100.3984375] "%" Vector__XXX
 SG_ F094_HVESS_Max_Cell_SOC : 48|16@1+ (0.0015625,0) [0|100.3984375] "%" Vector__XXX
 SG_ F094_HVESS_Discharge_Curr_Lim : 0|16@1+ (0.05,-1600) [-1600|1612.75] "A" Vector__XXX
 SG_ F094_HVESS_Charge_Curr_Lim : 16|16@1+ (0.05,-1600) [-1600|1612.75] "A" Vector__XXX

BO_ 2565903347 BMS_HVESSD4: 8 Vector__XXX
 SG_ F093_Reserved : 48|16@1- (1,0) [-32768|32767] "" Vector__XXX
 SG_ F093_HVESS_Discharge_Capacity : 0|16@1+ (0.01,0) [0|642.55] "Ah" Vector__XXX
 SG_ F093_HVESS_Charge_Capacity : 16|16@1+ (0.01,0) [0|642.55] "Ah" Vector__XXX
 SG_ F093_HVESS_Cell_Balancing_Count : 32|16@1+ (1,0) [0|64255] "count" Vector__XXX

BO_ 2565903091 BMS_HVESSD3: 8 Vector__XXX
 SG_ F092_Reserved : 50|6@1- (1,0) [-32|31] "" Vector__XXX
 SG_ F092_HVESS_Lowest_Cell_Temp : 16|16@1+ (0.03125,-273) [-273|1774.96875] "กษ" Vector__XXX
 SG_ F092_HVESS_Highest_Cell_Temp : 0|16@1+ (0.03125,-273) [-273|1774.96875] "กษ" Vector__XXX
 SG_ F092_HVESS_Cell_Temp_Diff_Status : 48|2@1+ (1,0) [0|3] "bit" Vector__XXX
 SG_ F092_HVESS_Avg_Cell_Temp : 32|16@1+ (0.03125,-273) [-273|1774.96875] "กษ" Vector__XXX

BO_ 2565902835 BMS_HVESSD2: 8 Vector__XXX
 SG_ F091_Reserved : 52|4@1- (1,0) [-8|7] "" Vector__XXX
 SG_ F091_HVESS_Lowest_Cell_Volt : 32|16@1+ (0.001,0) [0|64.255] "V" Vector__XXX
 SG_ F091_HVESS_Highest_Cell_Volt : 16|16@1+ (0.001,0) [0|64.255] "V" Vector__XXX
 SG_ F091_HVESS_Fast_Update_SOC : 0|16@1+ (0.0015625,0) [0|100.3984375] "%" Vector__XXX
 SG_ F091_HVESS_Cell_Volt_Diff_Status : 48|4@1+ (1,0) [0|15] "bit" Vector__XXX

BO_ 2565902579 BMS_HVESSD1: 8 Vector__XXX
 SG_ F090_HVESS_Voltage_Level : 32|16@1+ (0.05,0) [0|3212.75] "V" Vector__XXX
 SG_ F090_HVESS_Discharge_Power : 0|16@1+ (0.05,0) [0|3212.75] "kW" Vector__XXX
 SG_ F090_HVESS_Current : 48|16@1+ (0.05,-1600) [-1600|1612.75] "A" Vector__XXX
 SG_ F090_HVESS_Charge_Power : 16|16@1+ (0.05,0) [0|3212.75] "kW" Vector__XXX

BO_ 2566722889 OBC_BCH1_SA49: 9 Vector__XXX
 SG_ FD15_Reserved : 40|32@1- (1,0) [-2147483648|2147483647] "" Vector__XXX
 SG_ FD15_Battery_Charger1_State : 0|4@1+ (1,0) [0|15] "bit" Vector__XXX
 SG_ FD15_Battery_Charger1_Pow_State : 4|4@1+ (1,0) [0|3] "bit" Vector__XXX
 SG_ FD15_Battery_Charger1_Out_Volt : 8|16@1+ (0.05,0) [0|210] "V" Vector__XXX
 SG_ FD15_Battery_Charger1_Out_Curr : 24|16@1+ (0.05,-1600) [-1600|1612.75] "A" Vector__XXX

BO_ 2551906337 VCU_HVESSC1: 10 Vector__XXX
 SG_ LowWiperOperatingSignal : 64|2@1+ (1,0) [0|3] "count" Vector__XXX
 SG_ NormalWiperOperatingSignal : 60|3@1+ (1,0) [0|7] "bit" Vector__XXX
 SG_ _1B00_Reserved2 : 56|4@1+ (1,0) [0|15] "" Vector__XXX
 SG_ _1B00_Reserved1 : 24|32@1+ (1,0) [0|4294967295] "" Vector__XXX
 SG_ _1B00_Reserved : 18|6@1+ (1,0) [0|63] "" Vector__XXX
 SG_ _1B00_PowerDown : 2|2@1+ (1,0) [0|3] "bit" Vector__XXX
 SG_ _1B00_OperationConsent : 12|2@1+ (1,0) [0|3] "bit" Vector__XXX
 SG_ _1B00_HV_BusHighSideRConnect : 14|2@1+ (1,0) [0|3] "bit" Vector__XXX
 SG_ _1B00_HV_BusLowSideRConnect : 16|2@1+ (1,0) [0|3] "bit" Vector__XXX
 SG_ _1B00_HighV_BusPas_Isol_Test : 6|2@1+ (1,0) [0|3] "bit" Vector__XXX
 SG_ _1B00_HighV_BusConnect : 0|2@1+ (1,0) [0|3] "bit" Vector__XXX
 SG_ NormalWasherOperatingSignal : 4|2@1+ (1,0) [0|3] "bit" Vector__XXX
 SG_ PantoWasherOperatingSignal : 10|2@1+ (1,0) [0|3] "bit" Vector__XXX
 SG_ PantoWiperOperatingSignal : 8|3@1+ (1,0) [0|7] "bit" Vector__XXX

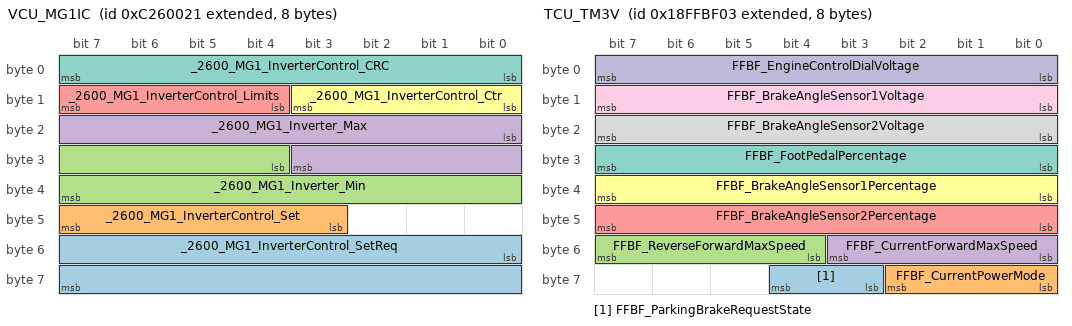
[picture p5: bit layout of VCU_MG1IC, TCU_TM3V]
BO_ 2351300641 VCU_MG1IC: 8 Vector__XXX
 SG_ _2600_MG1_InverterControl_SetReq : 48|16@1+ (0.00390625,-125) [-125|125.99609375] "%" Vector__XXX
 SG_ _2600_MG1_InverterControl_Set : 43|5@1+ (1,0) [0|31] "bit" Vector__XXX
 SG_ _2600_MG1_Inverter_Min : 28|12@1+ (1,-125) [-125|125.09375] "%" Vector__XXX
 SG_ _2600_MG1_Inverter_Max : 16|12@1+ (1,-125) [-125|125.09375] "%" Vector__XXX
 SG_ _2600_MG1_InverterControl_Limits : 12|4@1+ (1,0) [0|15] "bit" Vector__XXX
 SG_ _2600_MG1_InverterControl_Ctr : 8|4@1+ (1,0) [0|15] "bit" Vector__XXX
 SG_ _2600_MG1_InverterControl_CRC : 0|8@1+ (1,0) [0|255] "count" Vector__XXX

BO_ 2566791424 ECU_LFC1_EDC7: 8 Vector__XXX
 SG_ FE21_EngineTotalFuelUsed : 32|32@1+ (1,0) [0|4294967295] "" Vector__XXX
 SG_ FE21_EngineTripFuel : 0|32@1+ (1,0) [0|4294967295] "" Vector__XXX

BO_ 2365517089 VCU_ZFCCSS: 8 Vector__XXX
 SG_ FEED_MaxVehicleSpeedLimit : 0|8@1+ (1,0) [0|250] "km/h" Vector__XXX

BO_ 2566847015 VCU_B_T4F: 8 Vector__XXX
 SG_ BParkingBrakeActuator : 24|2@1+ (1,0) [0|3] "" Vector__XXX

BO_ 2365554727 VCU_DLN1_T4F: 8 Vector__XXX
 SG_ FF80_APPscania : 8|8@1+ (0.4,0) [0|102] "" Vector__XXX
 SG_ FF80_EngineStart : 20|2@1+ (1,0) [0|3] "" Vector__XXX
 SG_ FF80_VersionOfDLN1_Msg : 0|8@1+ (1,0) [0|255] "" Vector__XXX
 SG_ FF80_APLowIdleSwitchReleased : 16|2@1+ (1,0) [0|3] "" Vector__XXX
 SG_ FF80_APKickdownSwitch : 18|2@1+ (1,0) [0|3] "" Vector__XXX
 SG_ FF80_EngineStop : 22|2@1+ (1,0) [0|3] "" Vector__XXX
 SG_ FF80_EngEmergencyStopDemand : 24|2@1+ (1,0) [0|3] "" Vector__XXX
 SG_ FF80_RetarderSpeedCtlSetSW : 28|2@1+ (1,0) [0|3] "" Vector__XXX
 SG_ FF80_RetarderSpeedCtlOffSW : 30|2@1+ (1,0) [0|3] "" Vector__XXX
 SG_ FF80_LampTest : 36|2@1+ (1,0) [0|3] "" Vector__XXX
 SG_ FF80_CC_Off : 38|2@1+ (1,0) [0|3] "" Vector__XXX
 SG_ FF80_ExhaustBrakeAssistSW : 50|2@1+ (1,0) [0|3] "" Vector__XXX
 SG_ FF80_ExhaustBrakeFloorSW : 48|2@1+ (1,0) [0|3] "" Vector__XXX
 SG_ FF80_IdleCommand : 52|2@1+ (1,0) [0|3] "" Vector__XXX
 SG_ FF80_IncreasedIdleSpeedSW1 : 40|2@1+ (1,0) [0|3] "" Vector__XXX
 SG_ FF80_IncreasedIdleSpeedSW2 : 42|2@1+ (1,0) [0|3] "" Vector__XXX
 SG_ FF80_RetarderSelection : 56|8@1+ (1,0) [0|255] "" Vector__XXX
 SG_ FF80_TorqueLimit1 : 44|2@1+ (1,0) [0|3] "" Vector__XXX
 SG_ FF80_TorqueLimit2 : 46|2@1+ (1,0) [0|3] "" Vector__XXX
 SG_ FF80_WhiteSmokeLimitRequest : 54|2@1+ (1,0) [0|3] "" Vector__XXX

BO_ 2364539943 VCU_EEC1_T4F: 8 Vector__XXX
 SG_ EngineSpeed : 24|16@1+ (0.125,0) [0|8031.875] "rpm" Vector__XXX
 SG_ ActualEnginePercentTorque : 16|8@1+ (1,-125) [-125|125] "%" Vector__XXX
 SG_ DriversDemandEnginePercentTorque : 8|8@1+ (1,-125) [-125|125] "%" Vector__XXX

BO_ 2565868547 TCU_ETC8: 8 Vector__XXX
 SG_ F00C_TransmissionClutConInputSp : 16|16@1+ (0.125,0) [0|8031.875] "RPM" Vector__XXX
 SG_ F00C_TransmissionTrqConRatio : 0|16@1+ (0.001,0) [0|64.255] "" Vector__XXX

BO_ 2566826755 TCU_ETC6: 8 Vector__XXX
 SG_ FEAB_ClutchLifeTimeRemaining : 24|8@1+ (0.4,0) [0|100] "%" Vector__XXX
 SG_ FEAB_LowestPossibleGear : 16|8@1+ (1,-125) [-125|125] "gear" Vector__XXX
 SG_ FEAB_HighestPossibleGear : 8|8@1+ (1,-125) [-125|125] "gear" Vector__XXX
 SG_ FEAB_RecommendedGear : 0|8@1+ (1,-125) [-125|125] "gear" Vector__XXX

BO_ 2566843651 TCU_ZFCCSS: 8 Vector__XXX
 SG_ FEED_MaxVehicleSpeedLimit : 0|8@1- (1,0) [0|127] "km/h" Vector__XXX

BO_ 2566897411 TCU_TM3V: 8 Vector__XXX
 SG_ FFBF_ParkingBrakeRequestState : 59|2@1+ (1,0) [0|3] "" Vector__XXX
 SG_ FFBF_CurrentPowerMode : 56|3@1+ (1,0) [0|7] "" Vector__XXX
 SG_ FFBF_ReverseForwardMaxSpeed : 52|4@1+ (1,0) [0|15] "" Vector__XXX
 SG_ FFBF_CurrentForwardMaxSpeed : 48|4@1+ (1,0) [0|15] "" Vector__XXX
 SG_ FFBF_BrakeAngleSensor2Percentage : 40|8@1+ (0.4,0) [0|100] "%" Vector__XXX
 SG_ FFBF_BrakeAngleSensor1Percentage : 32|8@1+ (0.4,0) [0|100] "%" Vector__XXX
 SG_ FFBF_FootPedalPercentage : 24|8@1+ (0.4,0) [0|100] "%" Vector__XXX
 SG_ FFBF_BrakeAngleSensor2Voltage : 16|8@1+ (0.025,0) [0|6.25] "V" Vector__XXX
 SG_ FFBF_BrakeAngleSensor1Voltage : 8|8@1+ (0.025,0) [0|6.25] "V" Vector__XXX
 SG_ FFBF_EngineControlDialVoltage : 0|8@1+ (0.025,0) [0|6.25] "V" Vector__XXX

BO_ 2566897155 TCU_TM2V: 8 Vector__XXX
 SG_ FFBE_RHTravelMotorSpeedSensor : 32|16@1+ (1,0) [0|65535] "" Vector__XXX
 SG_ FFBE_RHRevTravelPumpPress : 8|8@1+ (1,0) [0|255] "" Vector__XXX
 SG_ FFBE_RHFwdTravelPumpPress : 0|8@1+ (1,0) [0|255] "" Vector__XXX
 SG_ FFBE_LHTravelMotorSpeedSensor : 48|16@1+ (1,0) [0|65535] "" Vector__XXX
 SG_ FFBE_LHRevTravelPumpPress : 24|8@1+ (1,0) [0|255] "" Vector__XXX
 SG_ FFBE_LHFwdTravelPumpPress : 16|8@1+ (1,0) [0|255] "" Vector__XXX

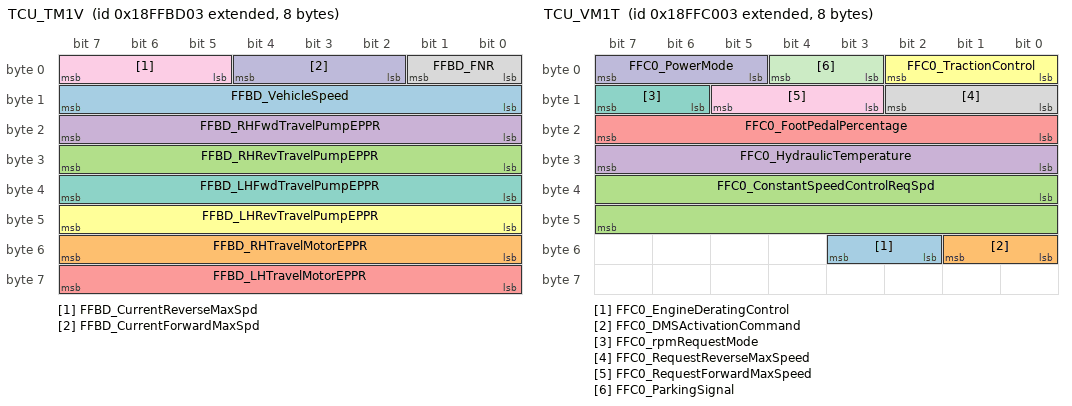
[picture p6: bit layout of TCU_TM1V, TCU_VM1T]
BO_ 2566896899 TCU_TM1V: 8 Vector__XXX
 SG_ FFBD_VehicleSpeed : 8|8@1+ (1,0) [0|255] "" Vector__XXX
 SG_ FFBD_RHTravelMotorEPPR : 48|8@1+ (1,0) [0|255] "" Vector__XXX
 SG_ FFBD_RHRevTravelPumpEPPR : 24|8@1+ (1,0) [0|255] "" Vector__XXX
 SG_ FFBD_RHFwdTravelPumpEPPR : 16|8@1+ (1,0) [0|255] "" Vector__XXX
 SG_ FFBD_LHTravelMotorEPPR : 56|8@1+ (1,0) [0|255] "" Vector__XXX
 SG_ FFBD_LHRevTravelPumpEPPR : 40|8@1+ (1,0) [0|255] "" Vector__XXX
 SG_ FFBD_LHFwdTravelPumpEPPR : 32|8@1+ (1,0) [0|255] "" Vector__XXX
 SG_ FFBD_FNR : 0|2@1+ (1,0) [0|3] "" Vector__XXX
 SG_ FFBD_CurrentReverseMaxSpd : 5|3@1+ (1,0) [0|7] "" Vector__XXX
 SG_ FFBD_CurrentForwardMaxSpd : 2|3@1+ (1,0) [0|7] "" Vector__XXX

BO_ 2566875937 VCU_ACRM_FEEDBACK: 8 Vector__XXX
 SG_ FF6B_VCU_ACP_PS : 56|8@1+ (16,0) [0|4000] "kPa" Vector__XXX
 SG_ FF6B_VCU_TemperatureState : 44|4@1+ (1,0) [0|15] "" Vector__XXX
 SG_ FF6B_VCU_CurrentAmbientTemperatu : 48|8@1+ (1,0) [0|255] "" Vector__XXX
 SG_ FF6B_VCU_CurrentBlowerSpeed : 40|4@1+ (1,0) [0|15] "" Vector__XXX
 SG_ FF6B_VCU_CurrentAmbientTemp_0000 : 32|8@1+ (1,0) [0|255] "" Vector__XXX
 SG_ FF6B_VCU_CurrentTemperatureSetti : 24|5@1+ (1,0) [0|31] "" Vector__XXX
 SG_ FF6B_VCU_TempSettingValueBelowSt : 20|2@1+ (1,0) [0|3] "" Vector__XXX
 SG_ FF6B_VCU_TempSettingValueOverSta : 18|2@1+ (1,0) [0|3] "" Vector__XXX
 SG_ FF6B_VCU_HVACPowerState : 16|2@1+ (1,0) [0|3] "" Vector__XXX
 SG_ FF6B_VCU_WindDirectDEFIndicState : 14|2@1+ (1,0) [0|3] "" Vector__XXX
 SG_ FF6B_VCU_WindDirectFloorIndicSta : 12|2@1+ (1,0) [0|3] "" Vector__XXX
 SG_ FF6B_VCU_WindDirectRearIndicStat : 10|2@1+ (1,0) [0|3] "" Vector__XXX
 SG_ FF6B_VCU_WindDirectFrontIndicSta : 8|2@1+ (1,0) [0|3] "" Vector__XXX
 SG_ FF6B_VCU_DEFModeState_Copy : 6|2@1+ (1,0) [0|3] "" Vector__XXX
 SG_ FF6B_VCU_OuttakeIntakeModeSelect : 4|2@1+ (1,0) [0|3] "" Vector__XXX
 SG_ FF6B_VCU_ACModeState : 2|2@1+ (1,0) [0|3] "" Vector__XXX
 SG_ FF6B_VCU_ManualAutoModeState : 0|2@1+ (1,0) [0|3] "" Vector__XXX

BO_ 2566897667 TCU_VM1T: 8 Vector__XXX
 SG_ FFC0_EngineDeratingControl : 50|2@1+ (1,0) [0|3] "" Vector__XXX
 SG_ FFC0_DMSActivationCommand : 48|2@1+ (1,0) [0|3] "" Vector__XXX
 SG_ FFC0_ConstantSpeedControlReqSpd : 32|16@1+ (1,0) [0|65535] "" Vector__XXX
 SG_ FFC0_HydraulicTemperature : 24|8@1+ (1,0) [0|255] "" Vector__XXX
 SG_ FFC0_FootPedalPercentage : 16|8@1+ (1,0) [0|255] "" Vector__XXX
 SG_ FFC0_TractionControl : 0|3@1+ (1,0) [0|7] "" Vector__XXX
 SG_ FFC0_rpmRequestMode : 14|2@1+ (1,0) [0|3] "" Vector__XXX
 SG_ FFC0_RequestReverseMaxSpeed : 8|3@1+ (1,0) [0|7] "" Vector__XXX
 SG_ FFC0_RequestForwardMaxSpeed : 11|3@1+ (1,0) [0|7] "" Vector__XXX
 SG_ FFC0_PowerMode : 5|3@1+ (1,0) [0|7] "" Vector__XXX
 SG_ FFC0_ParkingSignal : 3|2@1+ (1,0) [0|3] "" Vector__XXX

BO_ 2565800744 GP_SMTCU: 8 Vector__XXX
 SG_ EF03_SuspectParameterNumber : 0|19@1+ (1,0) [0|524287] "" Vector__XXX
 SG_ EF03_GSPNidentifier : 19|1@1+ (1,0) [0|1] "" Vector__XXX
 SG_ EF03_DataField : 24|40@1+ (1,0) [0|1099511627775] "" Vector__XXX

BO_ 2566841377 FEE4_Engine_shutdown: 8 Vector__XXX
 SG_ Engineshutdown01 : 32|2@1- (1,0) [-2|1] "" Vector__XXX

BO_ 2566857475 TCU_TCU5: 8 Vector__XXX
 SG_ FF23_TransFNR : 0|2@1+ (1,0) [0|3] "" Vector__XXX
 SG_ FF23_InchPedalPos_TCU : 48|8@1+ (1,0) [0|255] "" Vector__XXX

BO_ 2566857219 TCU_TCU4: 8 Vector__XXX
 SG_ FF22_ConverterTurbinTorque : 16|16@1+ (1,0) [0|65535] "" Vector__XXX
 SG_ FF22_ConverterPumpTorque : 0|16@1+ (1,0) [0|65535] "" Vector__XXX

BO_ 2565876164 GG_SlopeSensor_C4: 8 Vector__XXX
 SG_ F029_RollAngle_C4 : 24|24@1- (3.0517578125E-005,-250) [-506|5.99996948242188] "" Vector__XXX
 SG_ F029_PitchAngle_C4 : 0|24@1- (3.0517578125E-005,-250) [-506|5.99996948242188] "" Vector__XXX

BO_ 2565876163 GG_SlopeSensor_C3: 8 Vector__XXX
 SG_ F029_RollAngle_C3 : 24|24@1- (3.0517578125E-005,-250) [-506|5.99996948242188] "" Vector__XXX
 SG_ F029_PitchAngle_C3 : 0|24@1- (3.0517578125E-005,-250) [-506|5.99996948242188] "" Vector__XXX

BO_ 2365445940 JoystickLH_EJM1_DZ: 8 Vector__XXX
 SG_ FDD7_DZ_Button16_src34 : 56|2@1+ (1,0) [0|3] "" Vector__XXX
 SG_ FDD7_DZ_Button15_src34 : 58|2@1+ (1,0) [0|3] "" Vector__XXX
 SG_ FDD7_DZ_Button14_src34 : 60|2@1+ (1,0) [0|3] "" Vector__XXX
 SG_ FDD7_DZ_Button13_src34 : 62|2@1+ (1,0) [0|3] "" Vector__XXX
 SG_ FDD7_DZ_Theta_axisDetent_src34 : 50|2@1+ (1,0) [0|3] "" Vector__XXX
 SG_ FDD7_DZ_Grip_YaxisDetent_src34 : 52|2@1+ (1,0) [0|3] "" Vector__XXX
 SG_ FDD7_DZ_Grip_XaxisDetent_src34 : 54|2@1+ (1,0) [0|3] "" Vector__XXX
 SG_ FDD7_DZ_Theta_axisRight_src34 : 36|2@1+ (1,0) [0|3] "" Vector__XXX
 SG_ FDD7_DZ_Theta_axisNeutral_src34 : 32|2@1+ (1,0) [0|3] "" Vector__XXX
 SG_ FDD7_DZ_Theta_axisLeftNega_src34 : 34|2@1+ (1,0) [0|3] "" Vector__XXX
 SG_ FDD7_DZ_Theta_axis_posi_src34 : 38|10@1+ (0.1,0) [0|102.3] "" Vector__XXX
 SG_ FDD7_DZ_Grip_YaxisRight_src34 : 20|2@1+ (1,0) [0|3] "" Vector__XXX
 SG_ FDD7_DZ_Grip_YaxisNeutral_src34 : 16|2@1+ (1,0) [0|3] "" Vector__XXX
 SG_ FDD7_DZ_Grip_YaxisLeftNega_src34 : 18|2@1+ (1,0) [0|3] "" Vector__XXX
 SG_ FDD7_DZ_Grip_Yaxis_src34 : 22|10@1+ (0.1,0) [0|102.3] "" Vector__XXX
 SG_ FDD7_DZ_Grip_XaxisRight_src34 : 4|2@1+ (1,0) [0|3] "" Vector__XXX
 SG_ FDD7_DZ_Grip_XaxisNeutral_src34 : 0|2@1+ (1,0) [0|3] "" Vector__XXX
 SG_ FDD7_DZ_Grip_XaxisLeftNega_src34 : 2|2@1+ (1,0) [0|3] "" Vector__XXX
 SG_ FDD7_DZ_Grip_Xaxis_src34 : 6|10@1+ (0.1,0) [0|102.3] "" Vector__XXX

BO_ 2365445684 JoystickLH_BJM1_DZ: 8 Vector__XXX
 SG_ FDD6_DZ_Button9_src34 : 62|2@1+ (1,0) [0|3] "" Vector__XXX
 SG_ FDD6_DZ_Button8_src34 : 48|2@1+ (1,0) [0|3] "" Vector__XXX
 SG_ FDD6_DZ_Button7_src34 : 50|2@1+ (1,0) [0|3] "" Vector__XXX
 SG_ FDD6_DZ_Button6_src34 : 52|2@1+ (1,0) [0|3] "" Vector__XXX
 SG_ FDD6_DZ_Button5_src34 : 54|2@1+ (1,0) [0|3] "" Vector__XXX
 SG_ FDD6_DZ_Button12_src34 : 56|2@1+ (1,0) [0|3] "" Vector__XXX
 SG_ FDD6_DZ_Button11_src34 : 58|2@1+ (1,0) [0|3] "" Vector__XXX
 SG_ FDD6_DZ_Button10_src34 : 60|2@1+ (1,0) [0|3] "" Vector__XXX
 SG_ FDD6_DZ_YaxisNeutral_src34 : 16|2@1+ (1,0) [0|3] "" Vector__XXX
 SG_ FDD6_DZ_YaxisForwardPosi_src34 : 20|2@1+ (1,0) [0|3] "" Vector__XXX
 SG_ FDD6_DZ_YaxisDetentSts_src34 : 36|2@1+ (1,0) [0|3] "" Vector__XXX
 SG_ FDD6_DZ_YaxisBackNegative_src34 : 18|2@1+ (1,0) [0|3] "" Vector__XXX
 SG_ FDD6_DZ_Yaxis_src34 : 22|10@1+ (0.1,0) [0|102.3] "" Vector__XXX
 SG_ FDD6_DZ_XaxisRightPositive_src34 : 4|2@1+ (1,0) [0|3] "" Vector__XXX
 SG_ FDD6_DZ_XaxisNeutral_src34 : 0|2@1+ (1,0) [0|3] "" Vector__XXX
 SG_ FDD6_DZ_XaxisLeftNegative_src34 : 2|2@1+ (1,0) [0|3] "" Vector__XXX
 SG_ FDD6_DZ_XaxisDetentSts_src34 : 38|2@1+ (1,0) [0|3] "" Vector__XXX
 SG_ FDD6_DZ_Xaxis_src34 : 6|10@1+ (0.1,0) [0|102.3] "" Vector__XXX
 SG_ FDD6_DZ_Button4_src34 : 40|2@1+ (1,0) [0|3] "" Vector__XXX
 SG_ FDD6_DZ_Button3_src34 : 42|2@1+ (1,0) [0|3] "" Vector__XXX
 SG_ FDD6_DZ_Button2_src34 : 44|2@1+ (1,0) [0|3] "" Vector__XXX
 SG_ FDD6_DZ_Button1_src34 : 46|2@1+ (1,0) [0|3] "" Vector__XXX

BO_ 2566906401 VCU_ARTFI: 28 Vector__XXX
 SG_ FFE0_RT_Failure14_FMI : 219|5@1+ (1,0) [0|31] "" Vector__XXX
 SG_ FFE0_RT_Failure14_Code : 208|11@1+ (1,0) [0|2047] "" Vector__XXX
 SG_ FFE0_RT_Failure13_FMI : 203|5@1+ (1,0) [0|31] "" Vector__XXX
 SG_ FFE0_RT_Failure13_Code : 192|11@1+ (1,0) [0|2047] "" Vector__XXX
 SG_ FFE0_RT_Failure12_FMI : 187|5@1+ (1,0) [0|31] "" Vector__XXX
 SG_ FFE0_RT_Failure12_Code : 176|11@1+ (1,0) [0|2047] "" Vector__XXX
 SG_ FFE0_RT_Failure11_FMI : 171|5@1+ (1,0) [0|31] "" Vector__XXX
 SG_ FFE0_RT_Failure11_Code : 160|11@1+ (1,0) [0|2047] "" Vector__XXX
 SG_ FFE0_RT_Failure10_FMI : 155|5@1+ (1,0) [0|31] "" Vector__XXX
 SG_ FFE0_RT_Failure10_Code : 144|11@1+ (1,0) [0|2047] "" Vector__XXX
 SG_ FFE0_RT_Failure09_FMI : 139|5@1+ (1,0) [0|31] "" Vector__XXX
 SG_ FFE0_RT_Failure09_Code : 128|11@1+ (1,0) [0|2047] "" Vector__XXX
 SG_ FFE0_RT_Failure08_FMI : 123|5@1+ (1,0) [0|31] "" Vector__XXX
 SG_ FFE0_RT_Failure08_Code : 112|11@1+ (1,0) [0|2047] "" Vector__XXX
 SG_ FFE0_RT_Failure07_FMI : 107|5@1+ (1,0) [0|31] "" Vector__XXX
 SG_ FFE0_RT_Failure07_Code : 96|11@1+ (1,0) [0|2047] "" Vector__XXX
 SG_ FFE0_RT_Failure06_FMI : 91|5@1+ (1,0) [0|31] "" Vector__XXX
 SG_ FFE0_RT_Failure06_Code : 80|11@1+ (1,0) [0|2047] "" Vector__XXX
 SG_ FFE0_RT_Failure05_FMI : 75|5@1+ (1,0) [0|31] "" Vector__XXX
 SG_ FFE0_RT_Failure05_Code : 64|11@1+ (1,0) [0|2047] "" Vector__XXX
 SG_ FFE0_RT_Failure04_FMI : 59|5@1+ (1,0) [0|31] "" Vector__XXX
 SG_ FFE0_RT_Failure04_Code : 48|11@1+ (1,0) [0|2047] "" Vector__XXX
 SG_ FFE0_RT_Failure03_FMI : 43|5@1+ (1,0) [0|31] "" Vector__XXX
 SG_ FFE0_RT_Failure03_Code : 32|11@1+ (1,0) [0|2047] "" Vector__XXX
 SG_ FFE0_RT_Failure02_FMI : 27|5@1+ (1,0) [0|31] "" Vector__XXX
 SG_ FFE0_RT_Failure02_Code : 16|11@1+ (1,0) [0|2047] "" Vector__XXX
 SG_ FFE0_RT_Failure01_FMI : 11|5@1+ (1,0) [0|31] "" Vector__XXX
 SG_ FFE0_RT_Failure01_Code : 0|11@1+ (1,0) [0|2047] "" Vector__XXX

BO_ 2566871329 VCU_KEYPADI3: 8 Vector__XXX
 SG_ FF59_Indicate_Wiper_Front_R : 48|2@1+ (1,0) [0|3] "" Vector__XXX
 SG_ FF59_Indicate_Wiper_Front_L : 52|2@1+ (1,0) [0|3] "" Vector__XXX
 SG_ FF59_Indicate_Wiper_Front_C : 50|2@1+ (1,0) [0|3] "" Vector__XXX
 SG_ FF59_Indicate_Wiper_Rear_R : 42|2@1+ (1,0) [0|3] "" Vector__XXX
 SG_ FF59_Indicate_Wiper_Rear_L : 46|2@1+ (1,0) [0|3] "" Vector__XXX
 SG_ FF59_Indicate_Wiper_Rear_C : 44|2@1+ (1,0) [0|3] "" Vector__XXX
 SG_ FF59_Indicate_Wiper_Side_R : 36|2@1+ (1,0) [0|3] "" Vector__XXX
 SG_ FF59_Indicate_Wiper_Side_L : 40|2@1+ (1,0) [0|3] "" Vector__XXX
 SG_ FF59_Indicate_Wiper_Side_C : 38|2@1+ (1,0) [0|3] "" Vector__XXX
 SG_ FF59_Indicate_Washer_Front_R : 30|2@1+ (1,0) [0|3] "" Vector__XXX
 SG_ FF59_Indicate_Washer_Front_L : 34|2@1+ (1,0) [0|3] "" Vector__XXX
 SG_ FF59_Indicate_Washer_Front_C : 32|2@1+ (1,0) [0|3] "" Vector__XXX
 SG_ FF59_Indicate_Washer_Side_R : 24|2@1+ (1,0) [0|3] "" Vector__XXX
 SG_ FF59_Indicate_Washer_Side_L : 28|2@1+ (1,0) [0|3] "" Vector__XXX
 SG_ FF59_Indicate_Washer_Side_C : 26|2@1+ (1,0) [0|3] "" Vector__XXX
 SG_ FF59_Indicate_AirComp_R : 12|2@1+ (1,0) [0|3] "" Vector__XXX
 SG_ FF59_Indicate_AirComp_L : 16|2@1+ (1,0) [0|3] "" Vector__XXX
 SG_ FF59_Indicate_AirComp_C : 14|2@1+ (1,0) [0|3] "" Vector__XXX
 SG_ FF59_Indicate_TraveSpeed_R : 6|2@1+ (1,0) [0|3] "" Vector__XXX
 SG_ FF59_Indicate_TraveSpeed_L : 10|2@1+ (1,0) [0|3] "" Vector__XXX
 SG_ FF59_Indicate_TraveSpeed_C : 8|2@1+ (1,0) [0|3] "" Vector__XXX
 SG_ FF59_Indicate_BuzzerStop_R : 0|2@1+ (1,0) [0|3] "" Vector__XXX
 SG_ FF59_Indicate_BuzzerStop_L : 4|2@1+ (1,0) [0|3] "" Vector__XXX
 SG_ FF59_Indicate_BuzzerStop_C : 2|2@1+ (1,0) [0|3] "" Vector__XXX

BO_ 2566849057 VCU_DPM1: 8 Vector__XXX
 SG_ FF02_DPM1 : 0|1@1+ (1,0) [0|1] "" Vector__XXX

BO_ 2365445939 JoystickRH_EJM1_DZ: 8 Vector__XXX
 SG_ FDD7_DZ_Button16_src33 : 56|2@1+ (1,0) [0|3] "" Vector__XXX
 SG_ FDD7_DZ_Button15_src33 : 58|2@1+ (1,0) [0|3] "" Vector__XXX
 SG_ FDD7_DZ_Button14_src33 : 60|2@1+ (1,0) [0|3] "" Vector__XXX
 SG_ FDD7_DZ_Button13_src33 : 62|2@1+ (1,0) [0|3] "" Vector__XXX
 SG_ FDD7_DZ_Theta_axisDetent_src33 : 50|2@1+ (1,0) [0|3] "" Vector__XXX
 SG_ FDD7_DZ_Grip_YaxisDetent_src33 : 52|2@1+ (1,0) [0|3] "" Vector__XXX
 SG_ FDD7_DZ_Grip_XaxisDetent_src33 : 54|2@1+ (1,0) [0|3] "" Vector__XXX
 SG_ FDD7_DZ_Theta_axisRight_src33 : 36|2@1+ (1,0) [0|3] "" Vector__XXX
 SG_ FDD7_DZ_Theta_axisNeutral_src33 : 32|2@1+ (1,0) [0|3] "" Vector__XXX
 SG_ FDD7_DZ_Theta_axisLeftNega_src33 : 34|2@1+ (1,0) [0|3] "" Vector__XXX
 SG_ FDD7_DZ_Theta_axis_posi_src33 : 38|10@1+ (0.1,0) [0|102.3] "" Vector__XXX
 SG_ FDD7_DZ_Grip_YaxisRight_src33 : 20|2@1+ (1,0) [0|3] "" Vector__XXX
 SG_ FDD7_DZ_Grip_YaxisNeutral_src33 : 16|2@1+ (1,0) [0|3] "" Vector__XXX
 SG_ FDD7_DZ_Grip_YaxisLeftNega_src33 : 18|2@1+ (1,0) [0|3] "" Vector__XXX
 SG_ FDD7_DZ_Grip_Yaxis_src33 : 22|10@1+ (0.1,0) [0|102.3] "" Vector__XXX
 SG_ FDD7_DZ_Grip_XaxisRight_src33 : 4|2@1+ (1,0) [0|3] "" Vector__XXX
 SG_ FDD7_DZ_Grip_XaxisNeutral_src33 : 0|2@1+ (1,0) [0|3] "" Vector__XXX
 SG_ FDD7_DZ_Grip_XaxisLeftNega_src33 : 2|2@1+ (1,0) [0|3] "" Vector__XXX
 SG_ FDD7_DZ_Grip_Xaxis_src33 : 6|10@1+ (0.1,0) [0|102.3] "" Vector__XXX

BO_ 2365445683 JoystickRH_BJM1_DZ: 8 Vector__XXX
 SG_ FDD6_DZ_Button9_src33 : 62|2@1+ (1,0) [0|3] "" Vector__XXX
 SG_ FDD6_DZ_Button8_src33 : 48|2@1+ (1,0) [0|3] "" Vector__XXX
 SG_ FDD6_DZ_Button7_src33 : 50|2@1+ (1,0) [0|3] "" Vector__XXX
 SG_ FDD6_DZ_Button6_src33 : 52|2@1+ (1,0) [0|3] "" Vector__XXX
 SG_ FDD6_DZ_Button5_src33 : 54|2@1+ (1,0) [0|3] "" Vector__XXX
 SG_ FDD6_DZ_Button12_src33 : 56|2@1+ (1,0) [0|3] "" Vector__XXX
 SG_ FDD6_DZ_Button11_src33 : 58|2@1+ (1,0) [0|3] "" Vector__XXX
 SG_ FDD6_DZ_Button10_src33 : 60|2@1+ (1,0) [0|3] "" Vector__XXX
 SG_ FDD6_DZ_YaxisNeutral_src33 : 16|2@1+ (1,0) [0|3] "" Vector__XXX
 SG_ FDD6_DZ_YaxisForwardPosi_src33 : 20|2@1+ (1,0) [0|3] "" Vector__XXX
 SG_ FDD6_DZ_YaxisDetentSts_src33 : 36|2@1+ (1,0) [0|3] "" Vector__XXX
 SG_ FDD6_DZ_YaxisBackNegative_src33 : 18|2@1+ (1,0) [0|3] "" Vector__XXX
 SG_ FDD6_DZ_Yaxis_src33 : 22|10@1+ (0.1,0) [0|102.3] "" Vector__XXX
 SG_ FDD6_DZ_XaxisRightPositive_src33 : 4|2@1+ (1,0) [0|3] "" Vector__XXX
 SG_ FDD6_DZ_XaxisNeutral_src33 : 0|2@1+ (1,0) [0|3] "" Vector__XXX
 SG_ FDD6_DZ_XaxisLeftNegative_src33 : 2|2@1+ (1,0) [0|3] "" Vector__XXX
 SG_ FDD6_DZ_XaxisDetentSts_src33 : 38|2@1+ (1,0) [0|3] "" Vector__XXX
 SG_ FDD6_DZ_Xaxis_src33 : 6|10@1+ (0.1,0) [0|102.3] "" Vector__XXX
 SG_ FDD6_DZ_Button4_src33 : 40|2@1+ (1,0) [0|3] "" Vector__XXX
 SG_ FDD6_DZ_Button3_src33 : 42|2@1+ (1,0) [0|3] "" Vector__XXX
 SG_ FDD6_DZ_Button2_src33 : 44|2@1+ (1,0) [0|3] "" Vector__XXX
 SG_ FDD6_DZ_Button1_src33 : 46|2@1+ (1,0) [0|3] "" Vector__XXX

BO_ 2566869288 Cluster_JCM: 8 Vector__XXX
 SG_ FF51_IIlluminationBrightness : 0|8@1+ (1,0) [0|255] "" Vector__XXX

BO_ 2566867233 VCU_GPG3: 8 Vector__XXX
 SG_ FF49_TargetRollSlope : 48|16@1- (0.01,-321.27) [-648.95|6.40000000000003] "%" Vector__XXX
 SG_ FF49_TargetPitchSlope : 32|16@1- (0.01,-321.27) [-648.95|6.40000000000003] "%" Vector__XXX
 SG_ FF49_CorrectedRollSlope : 16|16@1- (0.01,-321.27) [-648.95|6.40000000000003] "%" Vector__XXX
 SG_ FF49_CorrectedPitchSlope : 0|16@1- (0.01,-321.27) [-648.95|6.40000000000003] "%" Vector__XXX

BO_ 2565875998 ACU_SlopeSensorInfo2: 8 Vector__XXX
 SG_ F029_RollAngle : 24|24@1+ (3.0517578125E-005,-250) [-250|261.999969482422] "" Vector__XXX
 SG_ F029_PitchAngle : 0|24@1- (3.0517578125E-005,-250) [-506|5.99996948242188] "" Vector__XXX

BO_ 2566913825 VCU_MAWI: 16 Vector__XXX
 SG_ FFFF_TotalAccumulatedWeight : 32|32@1+ (1,0) [0|4294967295] "kg" Vector__XXX
 SG_ FFFF_TotalAccumulatedBucketCount : 0|24@1+ (1,0) [0|16777215] "" Vector__XXX

BO_ 2566913569 VCU_MTSI: 128 Vector__XXX
 SG_ FFFE_MaterialsLoadingStatus : 448|1@1+ (1,0) [0|1] "" Vector__XXX
 SG_ FFFE_TotalWeightOfCurrent : 432|16@1+ (1,0) [0|65535] "kg" Vector__XXX
 SG_ FFFE_BucketCountOfCurrent : 416|16@1+ (1,0) [0|65535] "count" Vector__XXX
 SG_ FFFE_SelectedMaterialDensity : 400|16@1+ (1,0) [0|64255] "kg/m2" Vector__XXX

BO_ 2566913313 VCU_MWTSV: 32 Vector__XXX
 SG_ FFFD_SwingAssistAngle_Left : 120|24@1+ (1,0) [0|16777215] "" Vector__XXX
 SG_ FFFD_SwingAssistAngle_Right : 96|24@1+ (1,0) [0|16777215] "" Vector__XXX
 SG_ FFFD_EfenceTarget_SwingRight : 72|24@1+ (1,0) [0|16777215] "" Vector__XXX
 SG_ FFFD_EfenceTarget_SwingLeft : 48|24@1+ (1,0) [0|16777215] "" Vector__XXX
 SG_ FFFD_EfenceTarget_Ceiling : 32|16@1+ (1,0) [0|65535] "" Vector__XXX
 SG_ FFFD_EfenceTarget_Floor : 16|16@1+ (1,0) [0|65535] "" Vector__XXX
 SG_ FFFD_EfenceTarget_Wall : 0|16@1+ (1,0) [0|65535] "" Vector__XXX

BO_ 2566913057 VCU_MWHG3: 64 Vector__XXX
 SG_ FFFC_Benchmark_Zoffset : 120|16@1+ (1,0) [0|65535] "" Vector__XXX
 SG_ FFFC_Benchmark_Yoffset : 104|16@1+ (1,0) [0|65535] "" Vector__XXX
 SG_ FFFC_Benchmark_Xoffset : 88|16@1+ (1,0) [0|65535] "" Vector__XXX
 SG_ FFFC_TruckCount : 72|16@1+ (1,0) [0|65535] "" Vector__XXX
 SG_ FFFC_SelectedMaterialDensity : 56|16@1+ (1,0) [0|64255] "kg/m2" Vector__XXX
 SG_ FFFC_SelectedTruckTargetWeight : 40|16@1+ (1,0) [0|65535] "" Vector__XXX
 SG_ FFFC_BucketReferencePoint : 38|2@1+ (1,0) [0|3] "" Vector__XXX
 SG_ FFFC_ArtiBoom_Demension_Option : 35|3@1+ (1,0) [0|7] "" Vector__XXX
 SG_ FFFC_Arm_Demension_Option : 32|3@1+ (1,0) [0|7] "" Vector__XXX
 SG_ FFFC_Boom_Demension_Option : 27|3@1+ (1,0) [0|7] "" Vector__XXX
 SG_ FFFC_Weighing_Option : 26|1@1+ (1,0) [0|1] "" Vector__XXX
 SG_ FFFC_MC_Option : 25|1@1+ (1,0) [0|1] "" Vector__XXX
 SG_ FFFC_WeighingEnableSet : 24|1@1+ (1,0) [0|1] "" Vector__XXX
 SG_ FFFC_GradeAssistWorkMode : 20|4@1+ (1,0) [0|15] "" Vector__XXX
 SG_ FFFC_GradeAssistAccuracy : 16|4@1+ (1,0) [0|15] "" Vector__XXX
 SG_ FFFC_E_Fence_Track : 15|1@1+ (1,0) [0|1] "" Vector__XXX
 SG_ FFFC_E_Fence_Dozer : 14|1@1+ (1,0) [0|1] "" Vector__XXX
 SG_ FFFC_E_Fence_Cabin : 13|1@1+ (1,0) [0|1] "" Vector__XXX
 SG_ FFFC_E_Fence_SwingRight : 12|1@1+ (1,0) [0|1] "" Vector__XXX
 SG_ FFFC_E_Fence_SwingLeft : 11|1@1+ (1,0) [0|1] "" Vector__XXX
 SG_ FFFC_E_Fence_Ceiling : 10|1@1+ (1,0) [0|1] "" Vector__XXX
 SG_ FFFC_E_Fence_Floor : 9|1@1+ (1,0) [0|1] "" Vector__XXX
 SG_ FFFC_E_Fence_Wall : 8|1@1+ (1,0) [0|1] "" Vector__XXX
 SG_ FFFC_Enable_BucketAssist : 7|1@1+ (1,0) [0|1] "" Vector__XXX
 SG_ FFFC_Enable_SwingAssistRight : 6|1@1+ (1,0) [0|1] "" Vector__XXX
 SG_ FFFC_Enable_SwingAssistLeft : 5|1@1+ (1,0) [0|1] "" Vector__XXX
 SG_ FFFC_AssitEnableSet_GradeAssist : 4|1@1+ (1,0) [0|1] "" Vector__XXX
 SG_ FFFC_GradeAssistMode : 0|4@1+ (1,0) [0|15] "" Vector__XXX

BO_ 2566912801 VCU_MWHG2: 128 Vector__XXX
 SG_ FFFB_GradeAssist_PointZ09 : 712|16@1+ (1,0) [0|65535] "" Vector__XXX
 SG_ FFFB_GradeAssist_PointY09 : 696|16@1+ (1,0) [0|65535] "" Vector__XXX
 SG_ FFFB_GradeAssist_PointZ08 : 680|16@1+ (1,0) [0|65535] "" Vector__XXX
 SG_ FFFB_GradeAssist_PointY08 : 664|16@1+ (1,0) [0|65535] "" Vector__XXX
 SG_ FFFB_GradeAssist_PointZ07 : 648|16@1+ (1,0) [0|65535] "" Vector__XXX
 SG_ FFFB_GradeAssist_PointY07 : 632|16@1+ (1,0) [0|65535] "" Vector__XXX
 SG_ FFFB_GradeAssist_PointZ06 : 616|16@1+ (1,0) [0|65535] "" Vector__XXX
 SG_ FFFB_GradeAssist_PointY06 : 600|16@1+ (1,0) [0|65535] "" Vector__XXX
 SG_ FFFB_GradeAssist_PointZ05 : 584|16@1+ (1,0) [0|65535] "" Vector__XXX
 SG_ FFFB_GradeAssist_PointY05 : 568|16@1+ (1,0) [0|65535] "" Vector__XXX
 SG_ FFFB_GradeAssist_PointZ04 : 552|16@1+ (1,0) [0|65535] "" Vector__XXX
 SG_ FFFB_GradeAssist_PointY04 : 536|16@1+ (1,0) [0|65535] "" Vector__XXX
 SG_ FFFB_GradeAssist_PointZ03 : 520|16@1+ (1,0) [0|65535] "" Vector__XXX
 SG_ FFFB_GradeAssist_PointY03 : 504|16@1+ (1,0) [0|65535] "" Vector__XXX
 SG_ FFFB_GradeAssist_PointZ02 : 488|16@1+ (1,0) [0|65535] "" Vector__XXX
 SG_ FFFB_GradeAssist_PointY02 : 472|16@1+ (1,0) [0|65535] "" Vector__XXX
 SG_ FFFB_GradeAssist_PointZ01 : 456|16@1+ (1,0) [0|65535] "" Vector__XXX
 SG_ FFFB_GradeAssist_PointY01 : 440|16@1+ (1,0) [0|65535] "" Vector__XXX
 SG_ FFFB_CrossSlopeDesignData : 424|16@1+ (1,0) [0|65535] "" Vector__XXX
 SG_ FFFB_SlopeDesignData : 408|16@1+ (1,0) [0|65535] "" Vector__XXX
 SG_ FFFB_DepthDesignData : 392|16@1+ (1,0) [0|65535] "" Vector__XXX
 SG_ FFFB_RHThumbWheel05 : 384|8@1+ (1,0) [0|255] "" Vector__XXX
 SG_ FFFB_RHThumbWheel04 : 376|8@1+ (1,0) [0|255] "" Vector__XXX
 SG_ FFFB_RHThumbWheel03 : 368|8@1+ (1,0) [0|255] "" Vector__XXX
 SG_ FFFB_RHThumbWheel02 : 360|8@1+ (1,0) [0|255] "" Vector__XXX
 SG_ FFFB_RHThumbWheel01 : 352|8@1+ (1,0) [0|255] "" Vector__XXX
 SG_ FFFB_LHThumbWheel05 : 344|8@1+ (1,0) [0|255] "" Vector__XXX
 SG_ FFFB_LHThumbWheel04 : 336|8@1+ (1,0) [0|255] "" Vector__XXX
 SG_ FFFB_LHThumbWheel03 : 328|8@1+ (1,0) [0|255] "" Vector__XXX
 SG_ FFFB_LHThumbWheel02 : 320|8@1+ (1,0) [0|255] "" Vector__XXX
 SG_ FFFB_LHThumbWheel01 : 312|8@1+ (1,0) [0|255] "" Vector__XXX
 SG_ FFFB_RHButton10 : 304|8@1+ (1,0) [0|255] "" Vector__XXX
 SG_ FFFB_RHButton09 : 296|8@1+ (1,0) [0|255] "" Vector__XXX
 SG_ FFFB_RHButton08 : 288|8@1+ (1,0) [0|255] "" Vector__XXX
 SG_ FFFB_RHButton07 : 280|8@1+ (1,0) [0|255] "" Vector__XXX
 SG_ FFFB_RHButton06 : 272|8@1+ (1,0) [0|255] "" Vector__XXX
 SG_ FFFB_RHButton05 : 264|8@1+ (1,0) [0|255] "" Vector__XXX
 SG_ FFFB_RHButton04 : 256|8@1+ (1,0) [0|255] "" Vector__XXX
 SG_ FFFB_RHButton03 : 248|8@1+ (1,0) [0|255] "" Vector__XXX
 SG_ FFFB_RHButton02 : 240|8@1+ (1,0) [0|255] "" Vector__XXX
 SG_ FFFB_RHButton01 : 232|8@1+ (1,0) [0|255] "" Vector__XXX
 SG_ FFFB_LHButton10 : 224|8@1+ (1,0) [0|255] "" Vector__XXX
 SG_ FFFB_LHButton09 : 216|8@1+ (1,0) [0|255] "" Vector__XXX
 SG_ FFFB_LHButton08 : 208|8@1+ (1,0) [0|255] "" Vector__XXX
 SG_ FFFB_LHButton07 : 200|8@1+ (1,0) [0|255] "" Vector__XXX
 SG_ FFFB_LHButton06 : 192|8@1+ (1,0) [0|255] "" Vector__XXX
 SG_ FFFB_LHButton05 : 184|8@1+ (1,0) [0|255] "" Vector__XXX
 SG_ FFFB_LHButton04 : 176|8@1+ (1,0) [0|255] "" Vector__XXX
 SG_ FFFB_LHButton03 : 168|8@1+ (1,0) [0|255] "" Vector__XXX
 SG_ FFFB_LHButton02 : 160|8@1+ (1,0) [0|255] "" Vector__XXX
 SG_ FFFB_LHButton01 : 152|8@1+ (1,0) [0|255] "" Vector__XXX
 SG_ FFFB_Offset_Bucket : 128|24@1+ (1,0) [0|16777215] "" Vector__XXX
 SG_ FFFB_Offset_ArtiArmPitch : 104|24@1+ (1,0) [0|16777215] "" Vector__XXX
 SG_ FFFB_Offset_ArmPitch : 80|24@1+ (1,0) [0|16777215] "" Vector__XXX
 SG_ FFFB_Offset_BoomPitch : 56|24@1+ (1,0) [0|16777215] "" Vector__XXX
 SG_ FFFB_Offset_BodyRoll : 32|24@1+ (1,0) [0|16777215] "" Vector__XXX
 SG_ FFFB_Offset_BodyPitch : 8|24@1+ (1,0) [0|16777215] "" Vector__XXX
 SG_ FFFB_SelectedBucketNumber : 0|4@1+ (1,0) [0|15] "" Vector__XXX

BO_ 2566912545 VCU_MWHG1: 128 Vector__XXX
 SG_ FFFA_Bucket05_AngleGDN : 944|16@1+ (1,0) [0|65535] "" Vector__XXX
 SG_ FFFA_Bucket05_DT : 928|16@1+ (1,0) [0|65535] "" Vector__XXX
 SG_ FFFA_Bucket05_NQ3 : 912|16@1+ (1,0) [0|65535] "" Vector__XXX
 SG_ FFFA_Bucket05_DQ3 : 896|16@1+ (1,0) [0|65535] "" Vector__XXX
 SG_ FFFA_Bucket05_NQ2 : 880|16@1+ (1,0) [0|65535] "" Vector__XXX
 SG_ FFFA_Bucket05_DQ2 : 864|16@1+ (1,0) [0|65535] "" Vector__XXX
 SG_ FFFA_Bucket05_TN : 848|16@1+ (1,0) [0|65535] "" Vector__XXX
 SG_ FFFA_Bucket05_Width : 832|16@1+ (1,0) [0|65535] "" Vector__XXX
 SG_ FFFA_Bucket05_NQ1 : 816|16@1+ (1,0) [0|65535] "" Vector__XXX
 SG_ FFFA_Bucket05_DQ1 : 800|16@1+ (1,0) [0|65535] "" Vector__XXX
 SG_ FFFA_Bucket05_DN : 784|16@1+ (1,0) [0|65535] "" Vector__XXX
 SG_ FFFA_Bucket05_DG : 768|16@1+ (1,0) [0|65535] "" Vector__XXX
 SG_ FFFA_Bucket04_AngleGDN : 752|16@1+ (1,0) [0|65535] "" Vector__XXX
 SG_ FFFA_Bucket04_DT : 736|16@1+ (1,0) [0|65535] "" Vector__XXX
 SG_ FFFA_Bucket04_NQ3 : 720|16@1+ (1,0) [0|65535] "" Vector__XXX
 SG_ FFFA_Bucket04_DQ3 : 704|16@1+ (1,0) [0|65535] "" Vector__XXX
 SG_ FFFA_Bucket04_NQ2 : 688|16@1+ (1,0) [0|65535] "" Vector__XXX
 SG_ FFFA_Bucket04_DQ2 : 672|16@1+ (1,0) [0|65535] "" Vector__XXX
 SG_ FFFA_Bucket04_TN : 656|16@1+ (1,0) [0|65535] "" Vector__XXX
 SG_ FFFA_Bucket04_Width : 640|16@1+ (1,0) [0|65535] "" Vector__XXX
 SG_ FFFA_Bucket04_NQ1 : 624|16@1+ (1,0) [0|65535] "" Vector__XXX
 SG_ FFFA_Bucket04_DQ1 : 608|16@1+ (1,0) [0|65535] "" Vector__XXX
 SG_ FFFA_Bucket04_DN : 592|16@1+ (1,0) [0|65535] "" Vector__XXX
 SG_ FFFA_Bucket04_DG : 576|16@1+ (1,0) [0|65535] "" Vector__XXX
 SG_ FFFA_Bucket03_AngleGDN : 560|16@1+ (1,0) [0|65535] "" Vector__XXX
 SG_ FFFA_Bucket03_DT : 544|16@1+ (1,0) [0|65535] "" Vector__XXX
 SG_ FFFA_Bucket03_NQ3 : 528|16@1+ (1,0) [0|65535] "" Vector__XXX
 SG_ FFFA_Bucket03_DQ3 : 512|16@1+ (1,0) [0|65535] "" Vector__XXX
 SG_ FFFA_Bucket03_NQ2 : 496|16@1+ (1,0) [0|65535] "" Vector__XXX
 SG_ FFFA_Bucket03_DQ2 : 480|16@1+ (1,0) [0|65535] "" Vector__XXX
 SG_ FFFA_Bucket03_TN : 464|16@1+ (1,0) [0|65535] "" Vector__XXX
 SG_ FFFA_Bucket03_Width : 448|16@1+ (1,0) [0|65535] "" Vector__XXX
 SG_ FFFA_Bucket03_NQ1 : 432|16@1+ (1,0) [0|65535] "" Vector__XXX
 SG_ FFFA_Bucket03_DQ1 : 416|16@1+ (1,0) [0|65535] "" Vector__XXX
 SG_ FFFA_Bucket03_DN : 400|16@1+ (1,0) [0|65535] "" Vector__XXX
 SG_ FFFA_Bucket03_DG : 384|16@1+ (1,0) [0|65535] "" Vector__XXX
 SG_ FFFA_Bucket02_AngleGDN : 368|16@1+ (1,0) [0|65535] "" Vector__XXX
 SG_ FFFA_Bucket02_DT : 352|16@1+ (1,0) [0|65535] "" Vector__XXX
 SG_ FFFA_Bucket02_NQ3 : 336|16@1+ (1,0) [0|65535] "" Vector__XXX
 SG_ FFFA_Bucket02_DQ3 : 320|16@1+ (1,0) [0|65535] "" Vector__XXX
 SG_ FFFA_Bucket02_NQ2 : 304|16@1+ (1,0) [0|65535] "" Vector__XXX
 SG_ FFFA_Bucket02_DQ2 : 288|16@1+ (1,0) [0|65535] "" Vector__XXX
 SG_ FFFA_Bucket02_TN : 272|16@1+ (1,0) [0|65535] "" Vector__XXX
 SG_ FFFA_Bucket02_Width : 256|16@1+ (1,0) [0|65535] "" Vector__XXX
 SG_ FFFA_Bucket02_NQ1 : 240|16@1+ (1,0) [0|65535] "" Vector__XXX
 SG_ FFFA_Bucket02_DQ1 : 224|16@1+ (1,0) [0|65535] "" Vector__XXX
 SG_ FFFA_Bucket02_DN : 208|16@1+ (1,0) [0|65535] "" Vector__XXX
 SG_ FFFA_Bucket02_DG : 192|16@1+ (1,0) [0|65535] "" Vector__XXX
 SG_ FFFA_Bucket01_AngleGDN : 176|16@1+ (1,0) [0|65535] "" Vector__XXX
 SG_ FFFA_Bucket01_DT : 160|16@1+ (1,0) [0|65535] "" Vector__XXX
 SG_ FFFA_Bucket01_NQ3 : 144|16@1+ (1,0) [0|65535] "" Vector__XXX
 SG_ FFFA_Bucket01_DQ3 : 128|16@1+ (1,0) [0|65535] "" Vector__XXX
 SG_ FFFA_Bucket01_NQ2 : 112|16@1+ (1,0) [0|65535] "" Vector__XXX
 SG_ FFFA_Bucket01_DQ2 : 96|16@1+ (1,0) [0|65535] "" Vector__XXX
 SG_ FFFA_Bucket01_TN : 80|16@1+ (1,0) [0|65535] "" Vector__XXX
 SG_ FFFA_Bucket01_Width : 64|16@1+ (1,0) [0|65535] "" Vector__XXX
 SG_ FFFA_Bucket01_NQ1 : 48|16@1+ (1,0) [0|65535] "" Vector__XXX
 SG_ FFFA_Bucket01_DQ1 : 32|16@1+ (1,0) [0|65535] "" Vector__XXX
 SG_ FFFA_Bucket01_DN : 16|16@1+ (1,0) [0|65535] "" Vector__XXX
 SG_ FFFA_Bucket01_DG : 0|16@1+ (1,0) [0|65535] "" Vector__XXX

BO_ 2566834790 FuelSensor_DM1_Copy_1: 13 Vector__XXX
 SG_ FECA_03_SPN3 : 101|3@1+ (1,0) [0|7] "" Vector__XXX
 SG_ FECA_03_SPN2 : 88|8@1+ (1,0) [0|255] "" Vector__XXX
 SG_ FECA_03_SPN1 : 80|8@1+ (1,0) [0|255] "" Vector__XXX
 SG_ FECA_03_FMI : 96|5@1+ (1,0) [0|31] "" Vector__XXX
 SG_ FECA_02_SPN3 : 69|3@1+ (1,0) [0|7] "" Vector__XXX
 SG_ FECA_02_SPN2 : 56|8@1+ (1,0) [0|255] "" Vector__XXX
 SG_ FECA_02_SPN1 : 48|8@1+ (1,0) [0|255] "" Vector__XXX
 SG_ FECA_02_FMI : 64|5@1+ (1,0) [0|31] "" Vector__XXX
 SG_ FECA_01_SPN1 : 16|16@1+ (1,0) [0|65535] "" Vector__XXX
 SG_ FECA_01_FMI : 32|5@1+ (1,0) [0|31] "" Vector__XXX

BO_ 2566834789 FuelSensor_DM1: 13 Vector__XXX
 SG_ FECA_01_SPN2 : 37|3@1+ (1,0) [0|7] "" Vector__XXX
 SG_ FECA_01_SPN1 : 16|16@1+ (1,0) [0|65535] "" Vector__XXX
 SG_ FECA_01_FMI : 32|5@1+ (1,0) [0|31] "" Vector__XXX

BO_ 2566866977 VCU_GPG2: 8 Vector__XXX
 SG_ FF48_Target_Roll_Slope : 40|8@1+ (1,0) [0|255] "" Vector__XXX
 SG_ FF48_Target_Pitch_Slope : 32|8@1+ (1,0) [0|255] "" Vector__XXX
 SG_ FF48_Reserved : 48|16@1+ (1,0) [0|65535] "" Vector__XXX
 SG_ FF48_Corrected_Roll_Slope : 24|8@1+ (1,0) [0|255] "" Vector__XXX
 SG_ FF48_Corrected_Roll_Angle : 8|8@1+ (0.5,-65) [-65|62.5] "" Vector__XXX
 SG_ FF48_Corrected_Pitch_Slope : 16|8@1+ (1,0) [0|255] "" Vector__XXX
 SG_ FF48_Corrected_Pitch_Angle : 0|8@1+ (0.5,-65) [-65|62.5] "deg" Vector__XXX

BO_ 2566908711 VCU_TWG_T4F: 7 Vector__XXX
 SG_ FFEB_RealtimeBucketWeight : 0|16@1+ (1,0) [0|65535] "kg" Vector__XXX
 SG_ FFEB_BucketCountOfCurrentTruck : 24|16@1+ (1,0) [0|65535] "" Vector__XXX
 SG_ FFEB_TotalWeightOfCurrentTruck : 40|16@1+ (1,0) [0|65535] "" Vector__XXX
 SG_ FFEB_WeightStatus : 16|4@1+ (1,0) [0|15] "" Vector__XXX

BO_ 2566894388 SMART_KEY_Info: 8 Vector__XXX
 SG_ FFB3_FOBDetect : 2|1@1+ (1,0) [0|1] "" Vector__XXX
 SG_ FFB3_MachineTonage : 8|16@1+ (1,0) [0|65535] "" Vector__XXX
 SG_ FFB3_KeyStatusChange : 0|2@1+ (1,0) [0|3] "" Vector__XXX

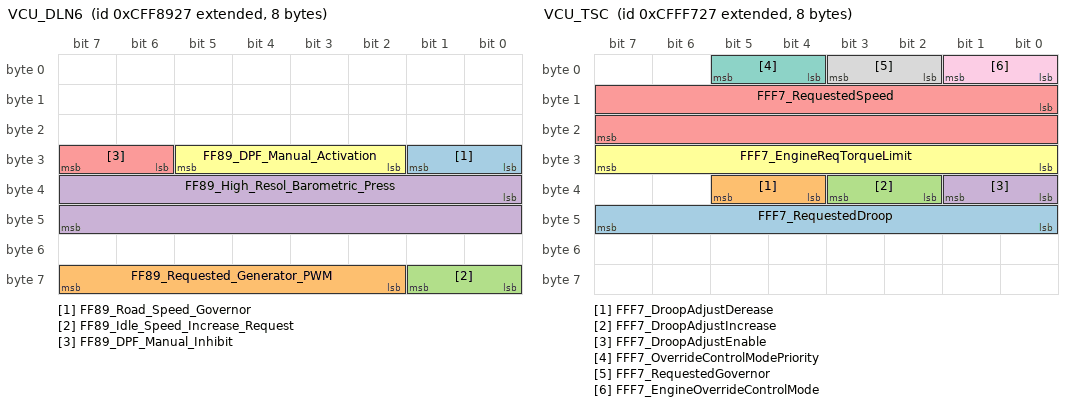
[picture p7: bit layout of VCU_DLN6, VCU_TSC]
BO_ 2365557031 VCU_DLN6: 8 Vector__XXX
 SG_ FF89_Road_Speed_Governor : 24|2@1+ (1,0) [0|3] "" Vector__XXX
 SG_ FF89_Requested_Generator_PWM : 58|6@1+ (1,0) [0|63] "" Vector__XXX
 SG_ FF89_Idle_Speed_Increase_Request : 56|2@1+ (1,0) [0|3] "" Vector__XXX
 SG_ FF89_High_Resol_Barometric_Press : 32|16@1+ (0.05,0) [0|3212.75] "kPa" Vector__XXX
 SG_ FF89_DPF_Manual_Inhibit : 30|2@1+ (1,0) [0|3] "" Vector__XXX
 SG_ FF89_DPF_Manual_Activation : 26|4@1+ (1,0) [0|15] "" Vector__XXX

BO_ 2566869287 VCU_CoolingCon: 8 Vector__XXX
 SG_ FF51_RequestCoolingFanSpeed : 8|8@1+ (1,0) [0|255] "" Vector__XXX

BO_ 2365585191 VCU_TSC: 8 Vector__XXX
 SG_ FFF7_RequestedDroop : 40|8@1+ (0.1,0) [0|25] "%" Vector__XXX
 SG_ FFF7_DroopAdjustDerease : 36|2@1+ (1,0) [0|3] "" Vector__XXX
 SG_ FFF7_DroopAdjustIncrease : 34|2@1+ (1,0) [0|3] "" Vector__XXX
 SG_ FFF7_DroopAdjustEnable : 32|2@1+ (1,0) [0|3] "" Vector__XXX
 SG_ FFF7_RequestedSpeed : 8|16@1+ (0.125,0) [0|8031.875] "rpm" Vector__XXX
 SG_ FFF7_EngineReqTorqueLimit : 24|8@1- (0.01,0) [-1.28|1.27] "%" Vector__XXX
 SG_ FFF7_OverrideControlModePriority : 4|2@1+ (1,0) [0|3] "" Vector__XXX
 SG_ FFF7_RequestedGovernor : 2|2@1+ (1,0) [0|3] "" Vector__XXX
 SG_ FFF7_EngineOverrideControlMode : 0|2@1+ (1,0) [0|3] "" Vector__XXX

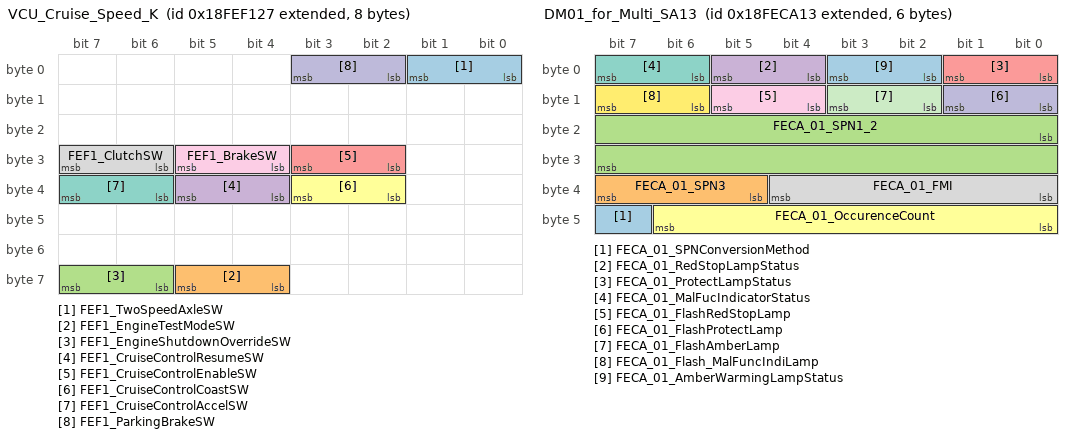
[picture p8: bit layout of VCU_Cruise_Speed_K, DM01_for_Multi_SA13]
BO_ 2566844711 VCU_Cruise_Speed_K: 8 Vector__XXX
 SG_ FEF1_TwoSpeedAxleSW : 0|2@1+ (1,0) [0|3] "" Vector__XXX
 SG_ FEF1_EngineTestModeSW : 60|2@1+ (1,0) [0|3] "" Vector__XXX
 SG_ FEF1_EngineShutdownOverrideSW : 62|2@1+ (1,0) [0|3] "" Vector__XXX
 SG_ FEF1_CruiseControlResumeSW : 36|2@1+ (1,0) [0|3] "" Vector__XXX
 SG_ FEF1_CruiseControlEnableSW : 26|2@1+ (1,0) [0|3] "" Vector__XXX
 SG_ FEF1_CruiseControlCoastSW : 34|2@1+ (1,0) [0|3] "" Vector__XXX
 SG_ FEF1_CruiseControlAccelSW : 38|2@1+ (1,0) [0|3] "" Vector__XXX
 SG_ FEF1_ClutchSW : 30|2@1+ (1,0) [0|3] "" Vector__XXX
 SG_ FEF1_BrakeSW : 28|2@1+ (1,0) [0|3] "" Vector__XXX
 SG_ FEF1_ParkingBrakeSW : 2|2@1+ (1,0) [0|3] "" Vector__XXX

BO_ 2565482535 VCU_RQST_T4F: 3 Vector__XXX
 SG_ ParameterGroupNumber : 0|24@1+ (1,0) [0|16777215] "" Vector__XXX

BO_ 2565472295 VCU_RQST_SA21_T4F: 3 Vector__XXX
 SG_ ParameterGroupNumber : 0|24@1+ (1,0) [0|16777215] "" Vector__XXX

BO_ 2566907175 VCU_SWVER_T4F: 8 Vector__XXX
 SG_ FFE5_VCU_SW_Version_Year : 48|8@1+ (1,0) [0|255] "" Vector__XXX
 SG_ FFE5_VCU_SW_Version_Day : 40|8@1+ (1,0) [0|255] "" Vector__XXX
 SG_ FFE5_VCU_SW_Version_Month : 32|8@1+ (1,0) [0|255] "" Vector__XXX
 SG_ FFE5_VCU_SW_Version : 0|32@1+ (1,0) [0|4294967295] "" Vector__XXX

BO_ 2348810279 VCU_TSC1_T4F: 8 Vector__XXX
 SG_ TSC1_EngineRequestedTorqueLimit : 24|8@1- (0.01,0) [-1.28|1.27] "%" Vector__XXX
 SG_ TSC1_RequestedSpeedLimit : 8|16@1+ (0.125,0) [0|8031.875] "rpm" Vector__XXX
 SG_ TSC1_OverrideControlModePriority : 4|2@1+ (1,0) [0|3] "" Vector__XXX
 SG_ TSC1_EngineRequestedSpeedControl : 2|2@1+ (1,0) [0|3] "" Vector__XXX
 SG_ TSC1EngineOverrideCtrlMode : 0|2@1+ (1,0) [0|3] "" Vector__XXX

BO_ 2566834707 DM01_for_Multi_SA13: 6 Vector__XXX
 SG_ FECA_01_SPNConversionMethod : 47|1@1+ (1,0) [0|1] "" Vector__XXX
 SG_ FECA_01_SPN3 : 37|3@1+ (1,0) [0|7] "" Vector__XXX
 SG_ FECA_01_SPN1_2 : 16|16@1+ (1,0) [0|65535] "" Vector__XXX
 SG_ FECA_01_RedStopLampStatus : 4|2@1+ (1,0) [0|3] "" Vector__XXX
 SG_ FECA_01_ProtectLampStatus : 0|2@1+ (1,0) [0|3] "" Vector__XXX
 SG_ FECA_01_OccurenceCount : 40|7@1+ (1,0) [0|127] "" Vector__XXX
 SG_ FECA_01_MalFucIndicatorStatus : 6|2@1+ (1,0) [0|3] "" Vector__XXX
 SG_ FECA_01_FMI : 32|5@1+ (1,0) [0|31] "" Vector__XXX
 SG_ FECA_01_FlashRedStopLamp : 12|2@1+ (1,0) [0|3] "" Vector__XXX
 SG_ FECA_01_FlashProtectLamp : 8|2@1+ (1,0) [0|3] "" Vector__XXX
 SG_ FECA_01_FlashAmberLamp : 10|2@1+ (1,0) [0|3] "" Vector__XXX
 SG_ FECA_01_Flash_MalFuncIndiLamp : 14|2@1+ (1,0) [0|3] "" Vector__XXX
 SG_ FECA_01_AmberWarmingLampStatus : 2|2@1+ (1,0) [0|3] "" Vector__XXX

BO_ 2566907681 VCU_ECOGI: 21 Vector__XXX
 SG_ FFE7_AutoUsingScore : 40|8@1+ (1,0) [0|255] "" Vector__XXX
 SG_ FFE7_Reserved2 : 120|48@1+ (1,0) [0|281474976710655] "" Vector__XXX
 SG_ FFE7_OilPressureScore : 104|8@1+ (1,0) [0|255] "" Vector__XXX
 SG_ FFE7_NotUsingStateScore : 56|8@1+ (1,0) [0|255] "" Vector__XXX
 SG_ FFE7_NotIntendingBreakScore : 96|8@1+ (1,0) [0|255] "" Vector__XXX
 SG_ FFE7_LockUpScore : 72|8@1+ (1,0) [0|255] "" Vector__XXX
 SG_ FFE7_LISSpeedUpScore : 24|8@1+ (1,0) [0|255] "" Vector__XXX
 SG_ FFE7_LISSpeedDownScore : 32|8@1+ (1,0) [0|255] "" Vector__XXX
 SG_ FFE7_LISFunctionScore : 16|8@1+ (1,0) [0|255] "" Vector__XXX
 SG_ FFE7_ICCOUsingScore : 112|8@1+ (1,0) [0|255] "" Vector__XXX
 SG_ FFE7_GearNormalRpmUpScore : 64|8@1+ (1,0) [0|255] "" Vector__XXX
 SG_ FFE7_GearMaxSpeedScore : 48|8@1+ (1,0) [0|255] "" Vector__XXX
 SG_ FFE7_EngineModeDownScore : 80|8@1+ (1,0) [0|255] "" Vector__XXX
 SG_ FFE7_BreakProtectingScore : 88|8@1+ (1,0) [0|255] "" Vector__XXX
 SG_ FFE7_Reserved : 6|10@1+ (1,0) [0|1023] "" Vector__XXX
 SG_ FFE7_ECOGIActiveControl : 0|6@1+ (1,0) [0|63] "" Vector__XXX

BO_ 2566910534 ETC_Tx: 8 Vector__XXX
 SG_ FFF2_Auto_CalibrationMode : 4|1@1+ (1,0) [0|1] "" Vector__XXX
 SG_ FFF2_TPSCalibrationState : 0|3@1+ (1,0) [0|7] "" Vector__XXX
 SG_ FFF2_RequestCalibration : 3|1@1+ (1,0) [0|1] "" Vector__XXX

BO_ 2364539937 VCU_EEC1: 8 Vector__XXX
 SG_ DriversDemandEnginePercentTorque : 8|8@1+ (1,-125) [-125|125] "%" Vector__XXX
 SG_ ActualEnginePercentTorque : 16|8@1+ (1,-125) [-125|125] "%" Vector__XXX
 SG_ EngineSpeed : 24|16@1+ (0.125,0) [0|8031.875] "rpm" Vector__XXX

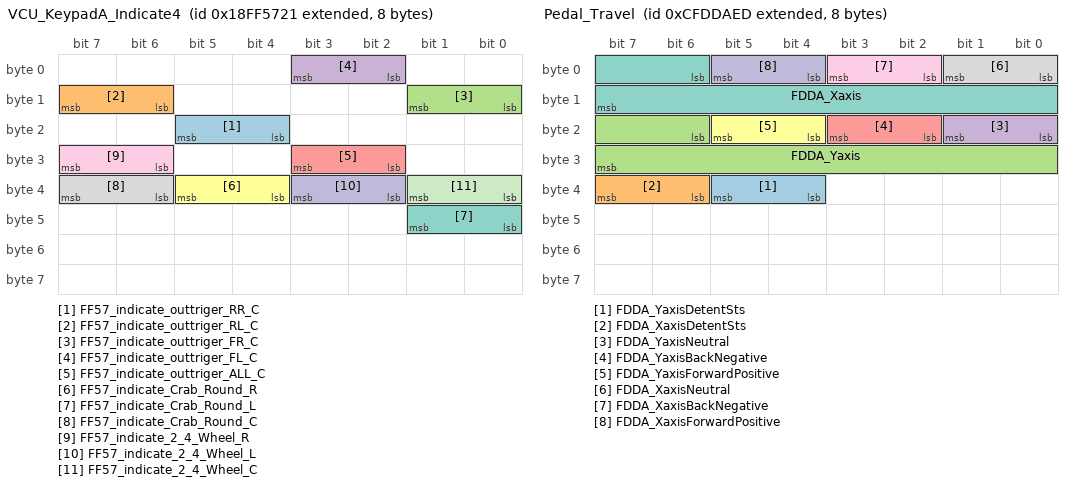
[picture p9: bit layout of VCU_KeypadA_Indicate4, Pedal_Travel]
BO_ 2566870817 VCU_KeypadA_Indicate4: 8 Vector__XXX
 SG_ FF57_indicate_outtriger_RR_C : 20|2@1+ (1,0) [0|3] "" Vector__XXX
 SG_ FF57_indicate_outtriger_RL_C : 14|2@1+ (1,0) [0|3] "" Vector__XXX
 SG_ FF57_indicate_outtriger_FR_C : 8|2@1+ (1,0) [0|3] "" Vector__XXX
 SG_ FF57_indicate_outtriger_FL_C : 2|2@1+ (1,0) [0|3] "" Vector__XXX
 SG_ FF57_indicate_outtriger_ALL_C : 26|2@1+ (1,0) [0|3] "" Vector__XXX
 SG_ FF57_indicate_Crab_Round_R : 36|2@1+ (1,0) [0|3] "" Vector__XXX
 SG_ FF57_indicate_Crab_Round_L : 40|2@1+ (1,0) [0|3] "" Vector__XXX
 SG_ FF57_indicate_Crab_Round_C : 38|2@1+ (1,0) [0|3] "" Vector__XXX
 SG_ FF57_indicate_2_4_Wheel_R : 30|2@1+ (1,0) [0|3] "" Vector__XXX
 SG_ FF57_indicate_2_4_Wheel_L : 34|2@1+ (1,0) [0|3] "" Vector__XXX
 SG_ FF57_indicate_2_4_Wheel_C : 32|2@1+ (1,0) [0|3] "" Vector__XXX

BO_ 2566891688 C2C_CAV: 8 Vector__XXX
 SG_ FFA8_PWM_Laggiing : 48|16@1+ (0.0025,0) [0|160.6375] "%" Vector__XXX
 SG_ FFA8_PWM_Leading : 32|16@1+ (0.0025,0) [0|160.6375] "%" Vector__XXX
 SG_ FFA8_Currnetinput : 0|16@1+ (0.4,0) [0|21000] "ฅ์A" Vector__XXX

BO_ 2365403377 Pedal_Option_TravelStraight: 8 Vector__XXX
 SG_ FD30_YaxisDetentSts : 36|2@1+ (1,0) [0|3] "" Vector__XXX
 SG_ FD30_Xaxis : 22|10@1+ (0.1,0) [0|102.3] "" Vector__XXX
 SG_ FD30_XaxisNeutral : 16|2@1+ (1,0) [0|3] "" Vector__XXX
 SG_ FD30_XaxisBackNegative : 18|2@1+ (1,0) [0|3] "" Vector__XXX
 SG_ FD30_XaxisForwardPositive : 20|2@1+ (1,0) [0|3] "" Vector__XXX

BO_ 2365403376 Pedal_Option_Arti: 8 Vector__XXX
 SG_ FD30_YaxisDetentSts : 36|2@1+ (1,0) [0|3] "" Vector__XXX
 SG_ FD30_Xaxis : 22|10@1+ (0.1,0) [0|102.3] "" Vector__XXX
 SG_ FD30_XaxisNeutral : 16|2@1+ (1,0) [0|3] "" Vector__XXX
 SG_ FD30_XaxisBackNegative : 18|2@1+ (1,0) [0|3] "" Vector__XXX
 SG_ FD30_XaxisForwardPositive : 20|2@1+ (1,0) [0|3] "" Vector__XXX

BO_ 2365403375 Pedal_Option_Rotating: 8 Vector__XXX
 SG_ FD30_YaxisDetentSts : 36|2@1+ (1,0) [0|3] "" Vector__XXX
 SG_ FD30_Xaxis : 22|10@1+ (0.1,0) [0|102.3] "" Vector__XXX
 SG_ FD30_XaxisNeutral : 16|2@1+ (1,0) [0|3] "" Vector__XXX
 SG_ FD30_XaxisBackNegative : 18|2@1+ (1,0) [0|3] "" Vector__XXX
 SG_ FD30_XaxisForwardPositive : 20|2@1+ (1,0) [0|3] "" Vector__XXX

BO_ 2365403374 Pedal_Option_2way: 8 Vector__XXX
 SG_ FD30_YaxisDetentSts : 36|2@1+ (1,0) [0|3] "" Vector__XXX
 SG_ FD30_Xaxis : 22|10@1+ (0.1,0) [0|102.3] "" Vector__XXX
 SG_ FD30_XaxisNeutral : 16|2@1+ (1,0) [0|3] "" Vector__XXX
 SG_ FD30_XaxisBackNegative : 18|2@1+ (1,0) [0|3] "" Vector__XXX
 SG_ FD30_XaxisForwardPositive : 20|2@1+ (1,0) [0|3] "" Vector__XXX

BO_ 2365446893 Pedal_Travel: 8 Vector__XXX
 SG_ FDDA_YaxisDetentSts : 36|2@1+ (1,0) [0|3] "" Vector__XXX
 SG_ FDDA_XaxisDetentSts : 38|2@1+ (1,0) [0|3] "" Vector__XXX
 SG_ FDDA_Yaxis : 22|10@1+ (0.1,0) [0|102.3] "" Vector__XXX
 SG_ FDDA_YaxisNeutral : 16|2@1+ (1,0) [0|3] "" Vector__XXX
 SG_ FDDA_YaxisBackNegative : 18|2@1+ (1,0) [0|3] "" Vector__XXX
 SG_ FDDA_YaxisForwardPositive : 20|2@1+ (1,0) [0|3] "" Vector__XXX
 SG_ FDDA_Xaxis : 6|10@1+ (0.1,0) [0|102.3] "" Vector__XXX
 SG_ FDDA_XaxisNeutral : 0|2@1+ (1,0) [0|3] "" Vector__XXX
 SG_ FDDA_XaxisBackNegative : 2|2@1+ (1,0) [0|3] "" Vector__XXX
 SG_ FDDA_XaxisForwardPositive : 4|2@1+ (1,0) [0|3] "" Vector__XXX

BO_ 2365446608 JoystickLH_EJM2: 8 Vector__XXX
 SG_ FDD9_Grip_Xaxis : 6|10@1+ (0.1,0) [0|102.3] "" Vector__XXX
 SG_ FDD9_Grip_XaxisNeutral : 0|2@1+ (1,0) [0|3] "" Vector__XXX
 SG_ FDD9_Grip_XaxisLeftNegative : 2|2@1+ (1,0) [0|3] "" Vector__XXX
 SG_ FDD9_Grip_XaxisRightPositive : 4|2@1+ (1,0) [0|3] "" Vector__XXX

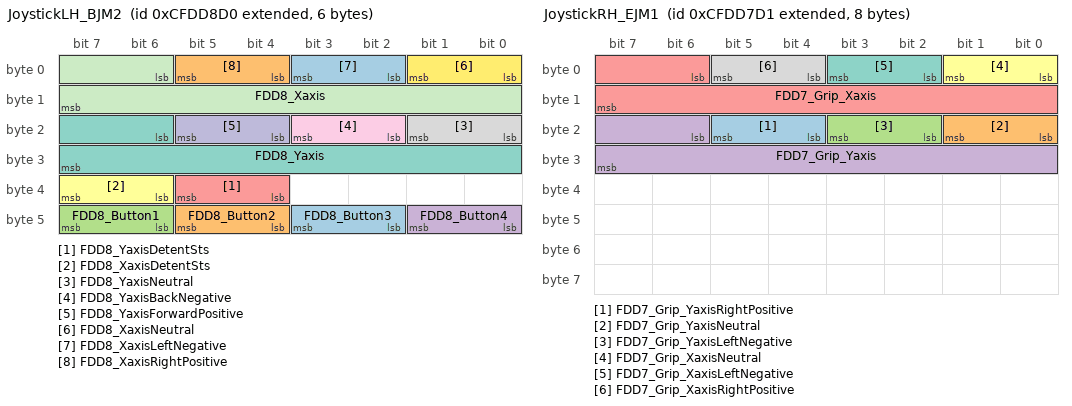
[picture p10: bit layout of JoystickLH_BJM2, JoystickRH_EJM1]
BO_ 2365446352 JoystickLH_BJM2: 6 Vector__XXX
 SG_ FDD8_Button3 : 42|2@1+ (1,0) [0|3] "" Vector__XXX
 SG_ FDD8_Button2 : 44|2@1+ (1,0) [0|3] "" Vector__XXX
 SG_ FDD8_Button1 : 46|2@1+ (1,0) [0|3] "" Vector__XXX
 SG_ FDD8_Button4 : 40|2@1+ (1,0) [0|3] "" Vector__XXX
 SG_ FDD8_YaxisDetentSts : 36|2@1+ (1,0) [0|3] "" Vector__XXX
 SG_ FDD8_XaxisDetentSts : 38|2@1+ (1,0) [0|3] "" Vector__XXX
 SG_ FDD8_Yaxis : 22|10@1+ (0.1,0) [0|102.3] "" Vector__XXX
 SG_ FDD8_YaxisNeutral : 16|2@1+ (1,0) [0|3] "" Vector__XXX
 SG_ FDD8_YaxisBackNegative : 18|2@1+ (1,0) [0|3] "" Vector__XXX
 SG_ FDD8_YaxisForwardPositive : 20|2@1+ (1,0) [0|3] "" Vector__XXX
 SG_ FDD8_Xaxis : 6|10@1+ (0.1,0) [0|102.3] "" Vector__XXX
 SG_ FDD8_XaxisNeutral : 0|2@1+ (1,0) [0|3] "" Vector__XXX
 SG_ FDD8_XaxisLeftNegative : 2|2@1+ (1,0) [0|3] "" Vector__XXX
 SG_ FDD8_XaxisRightPositive : 4|2@1+ (1,0) [0|3] "" Vector__XXX

BO_ 2365446097 JoystickRH_EJM1: 8 Vector__XXX
 SG_ FDD7_Grip_YaxisRightPositive : 20|2@1+ (1,0) [0|3] "" Vector__XXX
 SG_ FDD7_Grip_YaxisNeutral : 16|2@1+ (1,0) [0|3] "" Vector__XXX
 SG_ FDD7_Grip_YaxisLeftNegative : 18|2@1+ (1,0) [0|3] "" Vector__XXX
 SG_ FDD7_Grip_Yaxis : 22|10@1+ (0.1,0) [0|102.3] "" Vector__XXX
 SG_ FDD7_Grip_Xaxis : 6|10@1+ (0.1,0) [0|102.3] "" Vector__XXX
 SG_ FDD7_Grip_XaxisNeutral : 0|2@1+ (1,0) [0|3] "" Vector__XXX
 SG_ FDD7_Grip_XaxisLeftNegative : 2|2@1+ (1,0) [0|3] "" Vector__XXX
 SG_ FDD7_Grip_XaxisRightPositive : 4|2@1+ (1,0) [0|3] "" Vector__XXX

BO_ 2365445841 JoystickRH_BJM1: 8 Vector__XXX
 SG_ FDD6_Button5 : 54|2@1+ (1,0) [0|3] "" Vector__XXX
 SG_ FDD6_Button6 : 52|2@1+ (1,0) [0|3] "" Vector__XXX
 SG_ FDD6_Button7 : 50|2@1+ (1,0) [0|3] "" Vector__XXX
 SG_ FDD6_Button1 : 46|2@1+ (1,0) [0|3] "" Vector__XXX
 SG_ FDD6_Button4 : 40|2@1+ (1,0) [0|3] "" Vector__XXX
 SG_ FDD6_Button3 : 42|2@1+ (1,0) [0|3] "" Vector__XXX
 SG_ FDD6_Button2 : 44|2@1+ (1,0) [0|3] "" Vector__XXX
 SG_ FDD6_YaxisDetentSts : 36|2@1+ (1,0) [0|3] "" Vector__XXX
 SG_ FDD6_XaxisDetentSts : 38|2@1+ (1,0) [0|3] "" Vector__XXX
 SG_ FDD6_Yaxis : 22|10@1+ (0.1,0) [0|102.3] "" Vector__XXX
 SG_ FDD6_YaxisNeutral : 16|2@1+ (1,0) [0|3] "" Vector__XXX
 SG_ FDD6_YaxisBackNegative : 18|2@1+ (1,0) [0|3] "" Vector__XXX
 SG_ FDD6_YaxisForwardPositive : 20|2@1+ (1,0) [0|3] "" Vector__XXX
 SG_ FDD6_Xaxis : 6|10@1+ (0.1,0) [0|102.3] "" Vector__XXX
 SG_ FDD6_XaxisNeutral : 0|2@1+ (1,0) [0|3] "" Vector__XXX
 SG_ FDD6_XaxisLeftNegative : 2|2@1+ (1,0) [0|3] "" Vector__XXX
 SG_ FDD6_XaxisRightPositive : 4|2@1+ (1,0) [0|3] "" Vector__XXX

BO_ 2365565344 AUDIO_Acronym: 8 Vector__XXX
 SG_ FFA9_AudioFrequencytoGP : 0|1@1+ (1,0) [0|1] "" Vector__XXX

BO_ 2365550881 VCU_ZFSFS1: 8 Vector__XXX
 SG_ ZFSFS1_MessageCounter : 52|4@1+ (1,0) [0|15] "" Vector__XXX
 SG_ ZFSFS1_MessageChecksum : 56|8@1+ (1,0) [0|255] "" Vector__XXX
 SG_ ZFSFS1_AccelPedalPosition : 8|8@1+ (0.4,0) [0|100] "" Vector__XXX

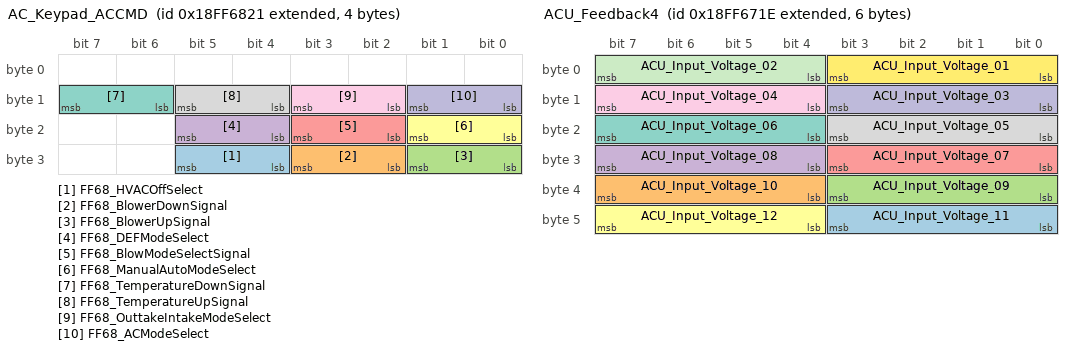
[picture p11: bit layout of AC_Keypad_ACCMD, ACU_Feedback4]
BO_ 2566875169 AC_Keypad_ACCMD: 4 Vector__XXX
 SG_ FF68_HVACOffSelect : 28|2@1+ (1,0) [0|3] "" Vector__XXX
 SG_ FF68_BlowerDownSignal : 26|2@1+ (1,0) [0|3] "" Vector__XXX
 SG_ FF68_BlowerUpSignal : 24|2@1+ (1,0) [0|3] "" Vector__XXX
 SG_ FF68_DEFModeSelect : 20|2@1+ (1,0) [0|3] "" Vector__XXX
 SG_ FF68_BlowModeSelectSignal : 18|2@1+ (1,0) [0|3] "" Vector__XXX
 SG_ FF68_ManualAutoModeSelect : 16|2@1+ (1,0) [0|3] "" Vector__XXX
 SG_ FF68_TemperatureDownSignal : 14|2@1+ (1,0) [0|3] "" Vector__XXX
 SG_ FF68_TemperatureUpSignal : 12|2@1+ (1,0) [0|3] "" Vector__XXX
 SG_ FF68_OuttakeIntakeModeSelect : 10|2@1+ (1,0) [0|3] "" Vector__XXX
 SG_ FF68_ACModeSelect : 8|2@1+ (1,0) [0|3] "" Vector__XXX

BO_ 2566875422 ACU_Feedback5: 4 Vector__XXX
 SG_ ACU_Output_Current_12 : 24|8@1+ (0.1,0) [0|25.3] "A" Vector__XXX
 SG_ ACU_Output_Current_11 : 16|8@1+ (0.1,0) [0|25.3] "A" Vector__XXX
 SG_ ACU_Output_Current_10 : 8|8@1+ (0.1,0) [0|25.3] "A" Vector__XXX
 SG_ ACU_Output_Current_09 : 0|8@1+ (0.1,0) [0|25.3] "A" Vector__XXX

BO_ 2566874654 ACU_Feedback3: 8 Vector__XXX
 SG_ Output_FB_ActiveLow_Current_08 : 62|2@1+ (1,0) [0|3] "" Vector__XXX
 SG_ Output_FB_ActiveLow_Current_07 : 60|2@1+ (1,0) [0|3] "" Vector__XXX
 SG_ Output_FB_ActiveLow_Current_06 : 58|2@1+ (1,0) [0|3] "" Vector__XXX
 SG_ Output_FB_ActiveLow_Current_05 : 56|2@1+ (1,0) [0|3] "" Vector__XXX
 SG_ Output_FB_ActiveLow_Current_04 : 54|2@1+ (1,0) [0|3] "" Vector__XXX
 SG_ Output_FB_ActiveLow_Current_03 : 52|2@1+ (1,0) [0|3] "" Vector__XXX
 SG_ Output_FB_ActiveLow_Current_02 : 50|2@1+ (1,0) [0|3] "" Vector__XXX
 SG_ Output_FB_ActiveLow_Current_01 : 48|2@1+ (1,0) [0|3] "" Vector__XXX
 SG_ Output_FB_ActiveHigh_Current_15 : 46|2@1+ (1,0) [0|3] "" Vector__XXX
 SG_ Output_FB_ActiveHigh_Current_14 : 44|2@1+ (1,0) [0|3] "" Vector__XXX
 SG_ Output_FB_ActiveHigh_Current_13 : 42|2@1+ (1,0) [0|3] "" Vector__XXX
 SG_ Output_FB_ActiveHigh_Current_12 : 40|2@1+ (1,0) [0|3] "" Vector__XXX
 SG_ Output_FB_ActiveHigh_Current_11 : 38|2@1+ (1,0) [0|3] "" Vector__XXX
 SG_ Output_FB_ActiveHigh_Current_10 : 36|2@1+ (1,0) [0|3] "" Vector__XXX
 SG_ Output_FB_ActiveHigh_Current_09 : 34|2@1+ (1,0) [0|3] "" Vector__XXX
 SG_ Output_FB_ActiveHigh_Current_08 : 32|2@1+ (1,0) [0|3] "" Vector__XXX
 SG_ Output_FB_ActiveHigh_Current_07 : 30|2@1+ (1,0) [0|3] "" Vector__XXX
 SG_ Output_FB_ActiveHigh_Current_06 : 28|2@1+ (1,0) [0|3] "" Vector__XXX
 SG_ Output_FB_ActiveHigh_Current_05 : 26|2@1+ (1,0) [0|3] "" Vector__XXX
 SG_ Output_FB_ActiveHigh_Current_04 : 24|2@1+ (1,0) [0|3] "" Vector__XXX
 SG_ Output_FB_ActiveHigh_Current_03 : 16|8@1+ (0.1,0) [0|25.3] "A" Vector__XXX
 SG_ Output_FB_ActiveHigh_Current_02 : 8|8@1+ (0.1,0) [0|25.3] "A" Vector__XXX
 SG_ Output_FB_ActiveHigh_Current_01 : 0|8@1+ (0.1,0) [0|25.3] "A" Vector__XXX

BO_ 2566874910 ACU_Feedback4: 6 Vector__XXX
 SG_ ACU_Input_Voltage_11 : 40|4@1+ (2,0) [0|30] "V" Vector__XXX
 SG_ ACU_Input_Voltage_10 : 36|4@1+ (2,0) [0|30] "V" Vector__XXX
 SG_ ACU_Input_Voltage_09 : 32|4@1+ (2,0) [0|30] "V" Vector__XXX
 SG_ ACU_Input_Voltage_08 : 28|4@1+ (2,0) [0|30] "V" Vector__XXX
 SG_ ACU_Input_Voltage_07 : 24|4@1+ (2,0) [0|30] "V" Vector__XXX
 SG_ ACU_Input_Voltage_12 : 44|4@1+ (2,0) [0|30] "V" Vector__XXX
 SG_ ACU_Input_Voltage_06 : 20|4@1+ (2,0) [0|30] "V" Vector__XXX
 SG_ ACU_Input_Voltage_05 : 16|4@1+ (2,0) [0|30] "V" Vector__XXX
 SG_ ACU_Input_Voltage_04 : 12|4@1+ (2,0) [0|30] "V" Vector__XXX
 SG_ ACU_Input_Voltage_03 : 8|4@1+ (2,0) [0|30] "V" Vector__XXX
 SG_ ACU_Input_Voltage_02 : 4|4@1+ (2,0) [0|30] "V" Vector__XXX
 SG_ ACU_Input_Voltage_01 : 0|4@1+ (2,0) [0|30] "V" Vector__XXX

BO_ 2566875678 ACU_Feedback6: 28 Vector__XXX
 SG_ SJB_IPS_totalCurrent : 144|16@1+ (1,0) [0|65535] "" Vector__XXX
 SG_ SJB_MiniRelayFuse_30A_02 : 221|1@1+ (1,0) [0|1] "" Vector__XXX
 SG_ SJB_MiniRelayFuse_30A_01 : 220|1@1+ (1,0) [0|1] "" Vector__XXX
 SG_ SJB_MicroRelayFuse_20A_05 : 219|1@1+ (1,0) [0|1] "" Vector__XXX
 SG_ SJB_MicroRelayFuse_20A_04 : 218|1@1+ (1,0) [0|1] "" Vector__XXX
 SG_ SJB_MicroRelayFuse_20A_03 : 217|1@1+ (1,0) [0|1] "" Vector__XXX
 SG_ SJB_MicroRelayFuse_20A_02 : 216|1@1+ (1,0) [0|1] "" Vector__XXX
 SG_ SJB_MicroRelayFuse_20A_01 : 215|1@1+ (1,0) [0|1] "" Vector__XXX
 SG_ SJB_KeyOn_Fuse_30A_05 : 214|1@1+ (1,0) [0|1] "" Vector__XXX
 SG_ SJB_KeyOn_Fuse_30A_04 : 213|1@1+ (1,0) [0|1] "" Vector__XXX
 SG_ SJB_KeyOn_Fuse_30A_03 : 212|1@1+ (1,0) [0|1] "" Vector__XXX
 SG_ SJB_KeyOn_Fuse_30A_02 : 211|1@1+ (1,0) [0|1] "" Vector__XXX
 SG_ SJB_KeyOn_Fuse_30A_01 : 210|1@1+ (1,0) [0|1] "" Vector__XXX
 SG_ SJB_KeyOn_Fuse_20A_10 : 209|1@1+ (1,0) [0|1] "" Vector__XXX
 SG_ SJB_KeyOn_Fuse_20A_09 : 208|1@1+ (1,0) [0|1] "" Vector__XXX
 SG_ SJB_KeyOn_Fuse_20A_08 : 207|1@1+ (1,0) [0|1] "" Vector__XXX
 SG_ SJB_KeyOn_Fuse_20A_07 : 206|1@1+ (1,0) [0|1] "" Vector__XXX
 SG_ SJB_KeyOn_Fuse_20A_06 : 205|1@1+ (1,0) [0|1] "" Vector__XXX
 SG_ SJB_KeyOn_Fuse_20A_05 : 204|1@1+ (1,0) [0|1] "" Vector__XXX
 SG_ SJB_KeyOn_Fuse_20A_04 : 203|1@1+ (1,0) [0|1] "" Vector__XXX
 SG_ SJB_KeyOn_Fuse_20A_03 : 202|1@1+ (1,0) [0|1] "" Vector__XXX
 SG_ SJB_KeyOn_Fuse_20A_02 : 201|1@1+ (1,0) [0|1] "" Vector__XXX
 SG_ SJB_KeyOn_Fuse_20A_01 : 200|1@1+ (1,0) [0|1] "" Vector__XXX
 SG_ SJB_KeyOn_Fuse_10A_05 : 199|1@1+ (1,0) [0|1] "" Vector__XXX
 SG_ SJB_KeyOn_Fuse_10A_04 : 198|1@1+ (1,0) [0|1] "" Vector__XXX
 SG_ SJB_KeyOn_Fuse_10A_03 : 197|1@1+ (1,0) [0|1] "" Vector__XXX
 SG_ SJB_KeyOn_Fuse_10A_02 : 196|1@1+ (1,0) [0|1] "" Vector__XXX
 SG_ SJB_KeyOn_Fuse_10A_01 : 195|1@1+ (1,0) [0|1] "" Vector__XXX
 SG_ SJB_KeyOn_Fuse_5A_15 : 194|1@1+ (1,0) [0|1] "" Vector__XXX
 SG_ SJB_KeyOn_Fuse_5A_14 : 193|1@1+ (1,0) [0|1] "" Vector__XXX
 SG_ SJB_KeyOn_Fuse_5A_13 : 192|1@1+ (1,0) [0|1] "" Vector__XXX
 SG_ SJB_KeyOn_Fuse_5A_12 : 191|1@1+ (1,0) [0|1] "" Vector__XXX
 SG_ SJB_KeyOn_Fuse_5A_11 : 190|1@1+ (1,0) [0|1] "" Vector__XXX
 SG_ SJB_KeyOn_Fuse_5A_10 : 189|1@1+ (1,0) [0|1] "" Vector__XXX
 SG_ SJB_KeyOn_Fuse_5A_09 : 188|1@1+ (1,0) [0|1] "" Vector__XXX
 SG_ SJB_KeyOn_Fuse_5A_08 : 187|1@1+ (1,0) [0|1] "" Vector__XXX
 SG_ SJB_KeyOn_Fuse_5A_07 : 186|1@1+ (1,0) [0|1] "" Vector__XXX
 SG_ SJB_KeyOn_Fuse_5A_06 : 185|1@1+ (1,0) [0|1] "" Vector__XXX
 SG_ SJB_KeyOn_Fuse_5A_05 : 184|1@1+ (1,0) [0|1] "" Vector__XXX
 SG_ SJB_KeyOn_Fuse_5A_04 : 183|1@1+ (1,0) [0|1] "" Vector__XXX
 SG_ SJB_KeyOn_Fuse_5A_03 : 182|1@1+ (1,0) [0|1] "" Vector__XXX
 SG_ SJB_KeyOn_Fuse_5A_02 : 181|1@1+ (1,0) [0|1] "" Vector__XXX
 SG_ SJB_KeyOn_Fuse_5A_01 : 180|1@1+ (1,0) [0|1] "" Vector__XXX
 SG_ SJB_Bplus_Fuse_30A_05 : 179|1@1+ (1,0) [0|1] "" Vector__XXX
 SG_ SJB_Bplus_Fuse_30A_04 : 178|1@1+ (1,0) [0|1] "" Vector__XXX
 SG_ SJB_Bplus_Fuse_30A_03 : 177|1@1+ (1,0) [0|1] "" Vector__XXX
 SG_ SJB_Bplus_Fuse_30A_02 : 176|1@1+ (1,0) [0|1] "" Vector__XXX
 SG_ SJB_Bplus_Fuse_30A_01 : 175|1@1+ (1,0) [0|1] "" Vector__XXX
 SG_ SJB_Bplus_Fuse_20A_05 : 174|1@1+ (1,0) [0|1] "" Vector__XXX
 SG_ SJB_Bplus_Fuse_20A_04 : 173|1@1+ (1,0) [0|1] "" Vector__XXX
 SG_ SJB_Bplus_Fuse_20A_03 : 172|1@1+ (1,0) [0|1] "" Vector__XXX
 SG_ SJB_Bplus_Fuse_20A_02 : 171|1@1+ (1,0) [0|1] "" Vector__XXX
 SG_ SJB_Bplus_Fuse_20A_01 : 170|1@1+ (1,0) [0|1] "" Vector__XXX
 SG_ SJB_Bplus_Fuse_5A_10 : 169|1@1+ (1,0) [0|1] "" Vector__XXX
 SG_ SJB_Bplus_Fuse_5A_09 : 168|1@1+ (1,0) [0|1] "" Vector__XXX
 SG_ SJB_Bplus_Fuse_5A_08 : 167|1@1+ (1,0) [0|1] "" Vector__XXX
 SG_ SJB_Bplus_Fuse_5A_07 : 166|1@1+ (1,0) [0|1] "" Vector__XXX
 SG_ SJB_Bplus_Fuse_5A_06 : 165|1@1+ (1,0) [0|1] "" Vector__XXX
 SG_ SJB_Bplus_Fuse_5A_05 : 164|1@1+ (1,0) [0|1] "" Vector__XXX
 SG_ SJB_Bplus_Fuse_5A_04 : 163|1@1+ (1,0) [0|1] "" Vector__XXX
 SG_ SJB_Bplus_Fuse_5A_03 : 162|1@1+ (1,0) [0|1] "" Vector__XXX
 SG_ SJB_Bplus_Fuse_5A_02 : 161|1@1+ (1,0) [0|1] "" Vector__XXX
 SG_ SJB_Bplus_Fuse_5A_01 : 160|1@1+ (1,0) [0|1] "" Vector__XXX
 SG_ SJB_MiniFuseCurrent_02 : 128|16@1+ (1,0) [0|65535] "" Vector__XXX
 SG_ SJB_MiniFuseCurrent_01 : 112|16@1+ (1,0) [0|65535] "" Vector__XXX
 SG_ SJB_MicroFuseCurrent_05 : 96|16@1+ (1,0) [0|65535] "" Vector__XXX
 SG_ SJB_MicroFuseCurrent_04 : 80|16@1+ (1,0) [0|65535] "" Vector__XXX
 SG_ SJB_MicroFuseCurrent_03 : 64|16@1+ (1,0) [0|65535] "" Vector__XXX
 SG_ SJB_MicroFuseCurrent_02 : 48|16@1+ (1,0) [0|65535] "" Vector__XXX
 SG_ SJB_MicroFuseCurrent_01 : 32|16@1+ (1,0) [0|65535] "" Vector__XXX
 SG_ SJB_KEYON_Current : 16|16@1+ (1,0) [0|65535] "" Vector__XXX
 SG_ SJB_B_Current : 0|16@1+ (1,0) [0|65535] "" Vector__XXX

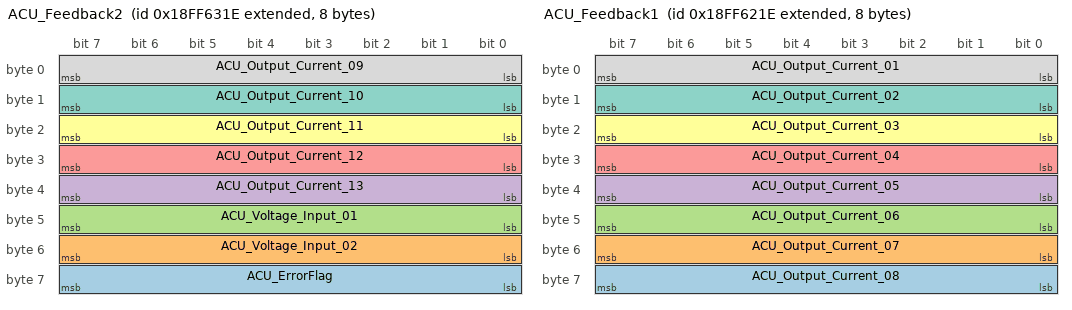
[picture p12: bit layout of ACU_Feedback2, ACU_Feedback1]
BO_ 2566873886 ACU_Feedback2: 8 Vector__XXX
 SG_ ACU_ErrorFlag : 56|8@1+ (1,0) [0|255] "" Vector__XXX
 SG_ ACU_Voltage_Input_02 : 48|8@1+ (0.125,0) [0|31.625] "V" Vector__XXX
 SG_ ACU_Voltage_Input_01 : 40|8@1+ (0.125,0) [0|31.625] "V" Vector__XXX
 SG_ ACU_Output_Current_13 : 32|8@1+ (0.05,0) [0|12.65] "A" Vector__XXX
 SG_ ACU_Output_Current_12 : 24|8@1+ (0.05,0) [0|12.65] "A" Vector__XXX
 SG_ ACU_Output_Current_11 : 16|8@1+ (0.05,0) [0|12.65] "A" Vector__XXX
 SG_ ACU_Output_Current_10 : 8|8@1+ (0.05,0) [0|12.65] "A" Vector__XXX
 SG_ ACU_Output_Current_09 : 0|8@1+ (0.05,0) [0|12.65] "A" Vector__XXX

BO_ 2566873630 ACU_Feedback1: 8 Vector__XXX
 SG_ ACU_Output_Current_08 : 56|8@1+ (0.05,0) [0|12.65] "A" Vector__XXX
 SG_ ACU_Output_Current_07 : 48|8@1+ (0.05,0) [0|12.65] "A" Vector__XXX
 SG_ ACU_Output_Current_06 : 40|8@1+ (0.05,0) [0|12.65] "A" Vector__XXX
 SG_ ACU_Output_Current_05 : 32|8@1+ (0.05,0) [0|12.65] "A" Vector__XXX
 SG_ ACU_Output_Current_04 : 24|8@1+ (0.05,0) [0|12.65] "A" Vector__XXX
 SG_ ACU_Output_Current_03 : 16|8@1+ (0.05,0) [0|12.65] "A" Vector__XXX
 SG_ ACU_Output_Current_02 : 8|8@1+ (0.05,0) [0|12.65] "A" Vector__XXX
 SG_ ACU_Output_Current_01 : 0|8@1+ (0.05,0) [0|12.65] "A" Vector__XXX

BO_ 2566875815 SJB_Feedback6: 28 Vector__XXX
 SG_ SJB_IPS_totalCurrent : 144|16@1+ (0.05,0) [0|3212.75] "A" Vector__XXX
 SG_ SJB_MiniRelayFuse_30A_02 : 221|1@1+ (1,0) [0|1] "" Vector__XXX
 SG_ SJB_MiniRelayFuse_30A_01 : 220|1@1+ (1,0) [0|1] "" Vector__XXX
 SG_ SJB_MicroRelayFuse_20A_05 : 219|1@1+ (1,0) [0|1] "" Vector__XXX
 SG_ SJB_MicroRelayFuse_20A_04 : 218|1@1+ (1,0) [0|1] "" Vector__XXX
 SG_ SJB_MicroRelayFuse_20A_03 : 217|1@1+ (1,0) [0|1] "" Vector__XXX
 SG_ SJB_MicroRelayFuse_20A_02 : 216|1@1+ (1,0) [0|1] "" Vector__XXX
 SG_ SJB_MicroRelayFuse_20A_01 : 215|1@1+ (1,0) [0|1] "" Vector__XXX
 SG_ SJB_KeyOn_Fuse_30A_05 : 214|1@1+ (1,0) [0|1] "" Vector__XXX
 SG_ SJB_KeyOn_Fuse_30A_04 : 213|1@1+ (1,0) [0|1] "" Vector__XXX
 SG_ SJB_KeyOn_Fuse_30A_03 : 212|1@1+ (1,0) [0|1] "" Vector__XXX
 SG_ SJB_KeyOn_Fuse_30A_02 : 211|1@1+ (1,0) [0|1] "" Vector__XXX
 SG_ SJB_KeyOn_Fuse_30A_01 : 210|1@1+ (1,0) [0|1] "" Vector__XXX
 SG_ SJB_KeyOn_Fuse_20A_10 : 209|1@1+ (1,0) [0|1] "" Vector__XXX
 SG_ SJB_KeyOn_Fuse_20A_09 : 208|1@1+ (1,0) [0|1] "" Vector__XXX
 SG_ SJB_KeyOn_Fuse_20A_08 : 207|1@1+ (1,0) [0|1] "" Vector__XXX
 SG_ SJB_KeyOn_Fuse_20A_07 : 206|1@1+ (1,0) [0|1] "" Vector__XXX
 SG_ SJB_KeyOn_Fuse_20A_06 : 205|1@1+ (1,0) [0|1] "" Vector__XXX
 SG_ SJB_KeyOn_Fuse_20A_05 : 204|1@1+ (1,0) [0|1] "" Vector__XXX
 SG_ SJB_KeyOn_Fuse_20A_04 : 203|1@1+ (1,0) [0|1] "" Vector__XXX
 SG_ SJB_KeyOn_Fuse_20A_03 : 202|1@1+ (1,0) [0|1] "" Vector__XXX
 SG_ SJB_KeyOn_Fuse_20A_02 : 201|1@1+ (1,0) [0|1] "" Vector__XXX
 SG_ SJB_KeyOn_Fuse_20A_01 : 200|1@1+ (1,0) [0|1] "" Vector__XXX
 SG_ SJB_KeyOn_Fuse_10A_05 : 199|1@1+ (1,0) [0|1] "" Vector__XXX
 SG_ SJB_KeyOn_Fuse_10A_04 : 198|1@1+ (1,0) [0|1] "" Vector__XXX
 SG_ SJB_KeyOn_Fuse_10A_03 : 197|1@1+ (1,0) [0|1] "" Vector__XXX
 SG_ SJB_KeyOn_Fuse_10A_02 : 196|1@1+ (1,0) [0|1] "" Vector__XXX
 SG_ SJB_KeyOn_Fuse_10A_01 : 195|1@1+ (1,0) [0|1] "" Vector__XXX
 SG_ SJB_KeyOn_Fuse_5A_15 : 194|1@1+ (1,0) [0|1] "" Vector__XXX
 SG_ SJB_KeyOn_Fuse_5A_14 : 193|1@1+ (1,0) [0|1] "" Vector__XXX
 SG_ SJB_KeyOn_Fuse_5A_13 : 192|1@1+ (1,0) [0|1] "" Vector__XXX
 SG_ SJB_KeyOn_Fuse_5A_12 : 191|1@1+ (1,0) [0|1] "" Vector__XXX
 SG_ SJB_KeyOn_Fuse_5A_11 : 190|1@1+ (1,0) [0|1] "" Vector__XXX
 SG_ SJB_KeyOn_Fuse_5A_10 : 189|1@1+ (1,0) [0|1] "" Vector__XXX
 SG_ SJB_KeyOn_Fuse_5A_09 : 188|1@1+ (1,0) [0|1] "" Vector__XXX
 SG_ SJB_KeyOn_Fuse_5A_08 : 187|1@1+ (1,0) [0|1] "" Vector__XXX
 SG_ SJB_KeyOn_Fuse_5A_07 : 186|1@1+ (1,0) [0|1] "" Vector__XXX
 SG_ SJB_KeyOn_Fuse_5A_06 : 185|1@1+ (1,0) [0|1] "" Vector__XXX
 SG_ SJB_KeyOn_Fuse_5A_05 : 184|1@1+ (1,0) [0|1] "" Vector__XXX
 SG_ SJB_KeyOn_Fuse_5A_04 : 183|1@1+ (1,0) [0|1] "" Vector__XXX
 SG_ SJB_KeyOn_Fuse_5A_03 : 182|1@1+ (1,0) [0|1] "" Vector__XXX
 SG_ SJB_KeyOn_Fuse_5A_02 : 181|1@1+ (1,0) [0|1] "" Vector__XXX
 SG_ SJB_KeyOn_Fuse_5A_01 : 180|1@1+ (1,0) [0|1] "" Vector__XXX
 SG_ SJB_Bplus_Fuse_30A_05 : 179|1@1+ (1,0) [0|1] "" Vector__XXX
 SG_ SJB_Bplus_Fuse_30A_04 : 178|1@1+ (1,0) [0|1] "" Vector__XXX
 SG_ SJB_Bplus_Fuse_30A_03 : 177|1@1+ (1,0) [0|1] "" Vector__XXX
 SG_ SJB_Bplus_Fuse_30A_02 : 176|1@1+ (1,0) [0|1] "" Vector__XXX
 SG_ SJB_Bplus_Fuse_30A_01 : 175|1@1+ (1,0) [0|1] "" Vector__XXX
 SG_ SJB_Bplus_Fuse_20A_05 : 174|1@1+ (1,0) [0|1] "" Vector__XXX
 SG_ SJB_Bplus_Fuse_20A_04 : 173|1@1+ (1,0) [0|1] "" Vector__XXX
 SG_ SJB_Bplus_Fuse_20A_03 : 172|1@1+ (1,0) [0|1] "" Vector__XXX
 SG_ SJB_Bplus_Fuse_20A_02 : 171|1@1+ (1,0) [0|1] "" Vector__XXX
 SG_ SJB_Bplus_Fuse_20A_01 : 170|1@1+ (1,0) [0|1] "" Vector__XXX
 SG_ SJB_Bplus_Fuse_5A_10 : 169|1@1+ (1,0) [0|1] "" Vector__XXX
 SG_ SJB_Bplus_Fuse_5A_09 : 168|1@1+ (1,0) [0|1] "" Vector__XXX
 SG_ SJB_Bplus_Fuse_5A_08 : 167|1@1+ (1,0) [0|1] "" Vector__XXX
 SG_ SJB_Bplus_Fuse_5A_07 : 166|1@1+ (1,0) [0|1] "" Vector__XXX
 SG_ SJB_Bplus_Fuse_5A_06 : 165|1@1+ (1,0) [0|1] "" Vector__XXX
 SG_ SJB_Bplus_Fuse_5A_05 : 164|1@1+ (1,0) [0|1] "" Vector__XXX
 SG_ SJB_Bplus_Fuse_5A_04 : 163|1@1+ (1,0) [0|1] "" Vector__XXX
 SG_ SJB_Bplus_Fuse_5A_03 : 162|1@1+ (1,0) [0|1] "" Vector__XXX
 SG_ SJB_Bplus_Fuse_5A_02 : 161|1@1+ (1,0) [0|1] "" Vector__XXX
 SG_ SJB_Bplus_Fuse_5A_01 : 160|1@1+ (1,0) [0|1] "" Vector__XXX
 SG_ SJB_MiniFuseCurrent_02 : 128|16@1+ (0.05,0) [0|3212.75] "A" Vector__XXX
 SG_ SJB_MiniFuseCurrent_01 : 112|16@1+ (0.05,0) [0|3212.75] "A" Vector__XXX
 SG_ SJB_MicroFuseCurrent_05 : 96|16@1+ (0.05,0) [0|3212.75] "A" Vector__XXX
 SG_ SJB_MicroFuseCurrent_04 : 80|16@1+ (0.05,0) [0|3212.75] "A" Vector__XXX
 SG_ SJB_MicroFuseCurrent_03 : 64|16@1+ (0.05,0) [0|3212.75] "A" Vector__XXX
 SG_ SJB_MicroFuseCurrent_02 : 48|16@1+ (0.05,0) [0|3212.75] "A" Vector__XXX
 SG_ SJB_MicroFuseCurrent_01 : 32|16@1+ (0.05,0) [0|3212.75] "A" Vector__XXX
 SG_ SJB_KEYON_Current : 16|16@1+ (0.05,0) [0|3212.75] "A" Vector__XXX
 SG_ SJB_B_Current : 0|16@1+ (0.05,0) [0|3212.75] "A" Vector__XXX

BO_ 2566875559 SJB_Feedback5: 4 Vector__XXX
 SG_ SJB_Output_Current_12 : 24|8@1+ (0.05,0) [0|12.65] "A" Vector__XXX
 SG_ SJB_Output_Current_11 : 16|8@1+ (0.05,0) [0|12.65] "A" Vector__XXX
 SG_ SJB_Output_Current_10 : 8|8@1+ (0.05,0) [0|12.65] "A" Vector__XXX
 SG_ SJB_Output_Current_09 : 0|8@1+ (0.05,0) [0|12.65] "A" Vector__XXX

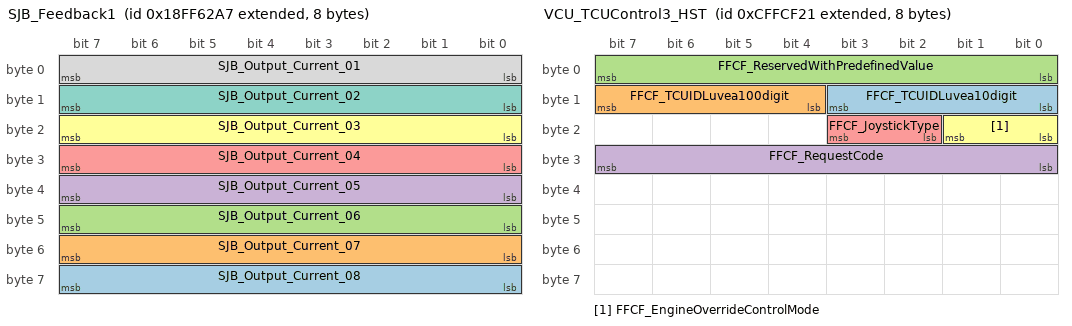
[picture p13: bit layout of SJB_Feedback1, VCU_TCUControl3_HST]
BO_ 2566873767 SJB_Feedback1: 8 Vector__XXX
 SG_ SJB_Output_Current_08 : 56|8@1+ (0.05,0) [0|12.65] "A" Vector__XXX
 SG_ SJB_Output_Current_07 : 48|8@1+ (0.05,0) [0|12.65] "A" Vector__XXX
 SG_ SJB_Output_Current_06 : 40|8@1+ (0.05,0) [0|12.65] "A" Vector__XXX
 SG_ SJB_Output_Current_05 : 32|8@1+ (0.05,0) [0|12.65] "A" Vector__XXX
 SG_ SJB_Output_Current_04 : 24|8@1+ (0.05,0) [0|12.65] "A" Vector__XXX
 SG_ SJB_Output_Current_03 : 16|8@1+ (0.05,0) [0|12.65] "A" Vector__XXX
 SG_ SJB_Output_Current_02 : 8|8@1+ (0.05,0) [0|12.65] "A" Vector__XXX
 SG_ SJB_Output_Current_01 : 0|8@1+ (0.05,0) [0|12.65] "A" Vector__XXX

BO_ 2566873377 VCU_ACU_CONTROL_SJB: 8 Vector__XXX
 SG_ SJB_Output_Request_15 : 28|2@1+ (1,0) [0|3] "" Vector__XXX
 SG_ SJB_Output_Request_14 : 26|2@1+ (1,0) [0|3] "" Vector__XXX
 SG_ SJB_Output_Request_13 : 24|2@1+ (1,0) [0|3] "" Vector__XXX
 SG_ ACU_LowOutPut_8 : 46|2@1+ (1,0) [0|3] "" Vector__XXX
 SG_ ACU_LowOutput_7 : 44|2@1+ (1,0) [0|3] "" Vector__XXX
 SG_ ACU_LowOutput_6 : 42|2@1+ (1,0) [0|3] "" Vector__XXX
 SG_ ACU_LowOutput_5 : 40|2@1+ (1,0) [0|3] "" Vector__XXX
 SG_ ACU_LowOutput_4 : 38|2@1+ (1,0) [0|3] "" Vector__XXX
 SG_ ACU_LowOutput_3 : 36|2@1+ (1,0) [0|3] "" Vector__XXX
 SG_ ACU_LowOutput_2 : 34|2@1+ (1,0) [0|3] "" Vector__XXX
 SG_ ACU_LowOutput_1 : 32|2@1+ (1,0) [0|3] "" Vector__XXX
 SG_ SJB_Output_Request_12 : 22|2@1+ (1,0) [0|3] "" Vector__XXX
 SG_ SJB_Output_Request_11 : 20|2@1+ (1,0) [0|3] "" Vector__XXX
 SG_ SJB_Output_Request_10 : 18|2@1+ (1,0) [0|3] "" Vector__XXX
 SG_ SJB_Output_Request_09 : 16|2@1+ (1,0) [0|3] "" Vector__XXX
 SG_ SJB_Output_Request_08 : 14|2@1+ (1,0) [0|3] "" Vector__XXX
 SG_ SJB_Output_Request_07 : 12|2@1+ (1,0) [0|3] "" Vector__XXX
 SG_ SJB_Output_Request_06 : 10|2@1+ (1,0) [0|3] "" Vector__XXX
 SG_ SJB_Output_Request_05 : 8|2@1+ (1,0) [0|3] "" Vector__XXX
 SG_ SJB_Output_Request_04 : 6|2@1+ (1,0) [0|3] "" Vector__XXX
 SG_ SJB_Output_Request_03 : 4|2@1+ (1,0) [0|3] "" Vector__XXX
 SG_ SJB_Output_Request_02 : 2|2@1+ (1,0) [0|3] "" Vector__XXX
 SG_ SJB_Output_Request_01 : 0|2@1+ (1,0) [0|3] "" Vector__XXX

BO_ 2566858785 VCU_FanCtrl: 8 Vector__XXX
 SG_ FF28_Speed_04_VCU : 32|2@1+ (1,0) [0|3] "" Vector__XXX
 SG_ FF28_Speed_03_VCU : 24|2@1+ (1,0) [0|3] "" Vector__XXX
 SG_ FF28_Speed_02_VCU : 16|2@1+ (1,0) [0|3] "" Vector__XXX
 SG_ FF28_Speed_01_VCU : 8|2@1+ (1,0) [0|3] "" Vector__XXX
 SG_ FF28_Speed_00_VCU : 0|2@1+ (1,0) [0|3] "" Vector__XXX

BO_ 2566866721 VCU_SIG3: 10 Vector__XXX
 SG_ FF47_PopUpReChargingRequest : 63|1@1+ (1,0) [0|1] "" Vector__XXX
 SG_ FF47_PopUp_ChargingAbnormal : 60|1@1+ (1,0) [0|1] "" Vector__XXX
 SG_ FF47_ChargingStatus : 58|2@1+ (1,0) [0|3] "" Vector__XXX
 SG_ FF47_Working_TravelEnable : 56|2@1+ (1,0) [0|3] "" Vector__XXX
 SG_ FF47_LowBattery : 55|1@1+ (1,0) [0|1] "" Vector__XXX
 SG_ FF47_HydraulicLock : 54|1@1+ (1,0) [0|1] "" Vector__XXX
 SG_ FF47_Popup_HillDescentCtrl : 53|1@1+ (1,0) [0|1] "" Vector__XXX
 SG_ FF47_HillDescentCtrl : 52|1@1+ (1,0) [0|1] "" Vector__XXX
 SG_ FF47_OperatorPresence : 51|1@1+ (1,0) [0|1] "" Vector__XXX
 SG_ FF47_BucketDusting : 50|1@1+ (1,0) [0|1] "" Vector__XXX
 SG_ FF47_PopUp_EMCVFingertipLever : 44|1@1+ (1,0) [0|1] "" Vector__XXX
 SG_ FF47_DACState : 45|3@1+ (1,0) [0|7] "" Vector__XXX
 SG_ FF47_BMSPreheatLamp : 48|2@1+ (1,0) [0|3] "" Vector__XXX
 SG_ FF47_Popup_FNR : 42|2@1+ (1,0) [0|3] "" Vector__XXX
 SG_ FF47_Illumination : 40|2@1+ (1,0) [0|3] "" Vector__XXX
 SG_ FF47_CHMSL_status : 36|4@1+ (1,0) [0|15] "" Vector__XXX
 SG_ FF47_Wheel_SteeringMode : 30|2@1+ (1,0) [0|3] "" Vector__XXX
 SG_ FF47_Wheel_CurrentMaxSpeedminor : 32|2@1+ (1,0) [0|3] "" Vector__XXX
 SG_ FF47_Symbol_Reverse_Condensor : 35|1@1+ (1,0) [0|1] "" Vector__XXX
 SG_ FF47_Symbol_Reverse_CAC : 34|1@1+ (1,0) [0|1] "" Vector__XXX
 SG_ FF47_Weighing_GND_Slope : 29|1@1+ (1,0) [0|1] "" Vector__XXX
 SG_ FF47_Weighing_OilTemp_Low : 28|1@1+ (1,0) [0|1] "" Vector__XXX
 SG_ FF47_Weighing_Confirm_MSG : 24|4@1+ (1,0) [0|15] "" Vector__XXX
 SG_ FF47_QuickCoolingStatus : 21|2@1+ (1,0) [0|3] "" Vector__XXX
 SG_ FF47_Popup_BucketAssistTargetSet : 20|1@1+ (1,0) [0|1] "" Vector__XXX
 SG_ FF47_Attachment_Oper_Signal : 23|1@1+ (1,0) [0|1] "" Vector__XXX
 SG_ FF47_LimpHome : 19|1@1+ (1,0) [0|1] "" Vector__XXX
 SG_ FF47_DozingAutoStopRequest : 18|1@1+ (1,0) [0|1] "" Vector__XXX
 SG_ FF47_KeyOffTimeDelay : 16|2@1+ (1,0) [0|3] "" Vector__XXX
 SG_ FF47_Rollover : 14|2@1+ (1,0) [0|3] "" Vector__XXX
 SG_ FF47_ArmPosition : 13|1@1+ (1,0) [0|1] "" Vector__XXX
 SG_ FF47_ThumbWheel : 12|1@1+ (1,0) [0|1] "" Vector__XXX
 SG_ FF47_RAMLockInfo : 10|2@1+ (1,0) [0|3] "" Vector__XXX
 SG_ FF47_Warning_HSTOilFilter : 9|1@1+ (1,0) [0|1] "" Vector__XXX
 SG_ FF47_Warning_GearboxOverTemp : 8|1@1+ (1,0) [0|1] "" Vector__XXX
 SG_ FF47_TractionLevel : 6|2@1+ (1,0) [0|3] "" Vector__XXX
 SG_ FF47_Wheel_LIS : 4|2@1+ (1,0) [0|3] "" Vector__XXX
 SG_ FF47_DozerTrailerHitch : 3|1@1+ (1,0) [0|1] "" Vector__XXX
 SG_ FF47_SwingAlign : 2|1@1+ (1,0) [0|1] "" Vector__XXX
 SG_ FF47_RAMLockAuto : 0|2@1+ (1,0) [0|3] "" Vector__XXX

BO_ 2365574945 VCU_TCUControl3_HST: 8 Vector__XXX
 SG_ FFCF_TCUIDLuvea10digit : 8|4@1+ (1,0) [0|15] "" Vector__XXX
 SG_ FFCF_TCUIDLuvea100digit : 12|4@1+ (1,0) [0|15] "" Vector__XXX
 SG_ FFCF_ReservedWithPredefinedValue : 0|8@1+ (1,0) [0|255] "" Vector__XXX
 SG_ FFCF_RequestCode : 24|8@1+ (1,0) [0|255] "" Vector__XXX
 SG_ FFCF_JoystickType : 18|2@1+ (1,0) [0|3] "" Vector__XXX
 SG_ FFCF_EngineOverrideControlMode : 16|2@1+ (1,0) [0|3] "" Vector__XXX

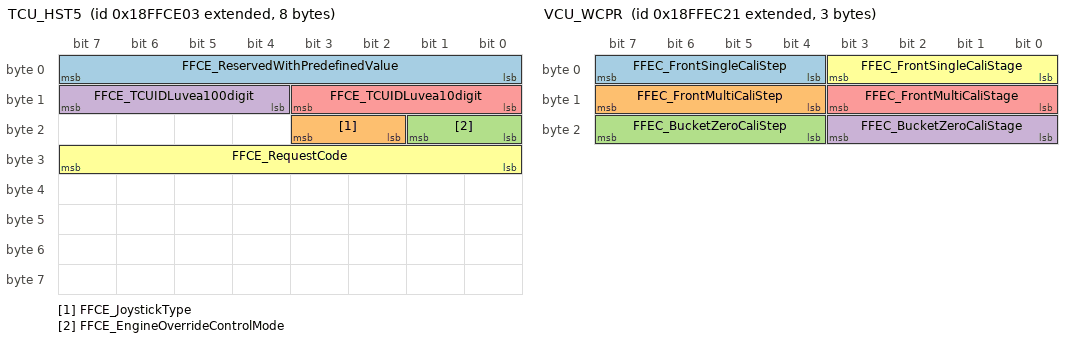
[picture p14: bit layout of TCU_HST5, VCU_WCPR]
BO_ 2566901251 TCU_HST5: 8 Vector__XXX
 SG_ FFCE_ReservedWithPredefinedValue : 0|8@1+ (1,0) [0|255] "" Vector__XXX
 SG_ FFCE_JoystickType : 18|2@1+ (1,0) [0|3] "" Vector__XXX
 SG_ FFCE_EngineOverrideControlMode : 16|2@1+ (1,0) [0|3] "" Vector__XXX
 SG_ FFCE_TCUIDLuvea100digit : 12|4@1+ (1,0) [0|15] "" Vector__XXX
 SG_ FFCE_TCUIDLuvea10digit : 8|4@1+ (1,0) [0|15] "" Vector__XXX
 SG_ FFCE_RequestCode : 24|8@1+ (1,0) [0|255] "" Vector__XXX

BO_ 2566910241 VCU_ASRG: 3 Vector__XXX
 SG_ FFF1_SwingAngle : 0|24@1+ (1,0) [0|16777215] "" Vector__XXX

BO_ 2566909729 VCU_LADG: 8 Vector__XXX
 SG_ FFEF_ActualLoad : 0|16@1+ (1,0) [0|65535] "" Vector__XXX
 SG_ FFEF_Reach : 48|16@1+ (1,0) [0|65535] "" Vector__XXX
 SG_ FFEF_Hight : 32|16@1+ (1,0) [0|65535] "" Vector__XXX
 SG_ FFEF_RatedLoad : 16|16@1+ (1,0) [0|65535] "" Vector__XXX

BO_ 2566909473 VCU_WCJA: 6 Vector__XXX
 SG_ FFEE_ArmJointAngle_EndPosi : 40|8@1+ (1,0) [0|255] "" Vector__XXX
 SG_ FFEE_ArmJointAngle_StartPosi : 32|8@1+ (1,0) [0|255] "" Vector__XXX
 SG_ FFEE_Current_ArmJointAngle : 24|8@1+ (1,0) [0|255] "" Vector__XXX
 SG_ FFEE_BoomJointAngle_EndPosition : 16|8@1+ (1,0) [0|255] "" Vector__XXX
 SG_ FFEE_BoomJointAngle_StartPosi : 8|8@1+ (1,0) [0|255] "" Vector__XXX
 SG_ FFEE_CurrenBoomJointAngle : 0|8@1+ (1,0) [0|255] "" Vector__XXX

BO_ 2566909217 VCU_WCCV: 6 Vector__XXX
 SG_ FFED_TarArmCyliVelo_UpperLimit : 40|8@1+ (1,0) [0|255] "mm/sec" Vector__XXX
 SG_ FFED_TarArmCyliVelo_LowerLimit : 32|8@1+ (1,0) [0|255] "mm/sec" Vector__XXX
 SG_ FFED_CurrentArmCylinderVelocity : 24|8@1+ (1,0) [0|255] "mm/sec" Vector__XXX
 SG_ FFED_BoomCylinVelo_UpperLimit : 16|8@1+ (1,0) [0|255] "mm/sec" Vector__XXX
 SG_ FFED_BoomCylinVelo_LowerLimit : 8|8@1+ (1,0) [0|255] "mm/sec" Vector__XXX
 SG_ FFED_Curr_Boom_Cylin_Velocity : 0|8@1+ (1,0) [0|255] "mm/sec" Vector__XXX

BO_ 2566908961 VCU_WCPR: 3 Vector__XXX
 SG_ FFEC_FrontSingleCaliStep : 4|4@1- (1,0) [-8|7] "" Vector__XXX
 SG_ FFEC_FrontMultiCaliStep : 12|4@1- (1,0) [-8|7] "" Vector__XXX
 SG_ FFEC_BucketZeroCaliStep : 20|4@1+ (1,0) [0|15] "" Vector__XXX
 SG_ FFEC_BucketZeroCaliStage : 16|4@1+ (1,0) [0|15] "" Vector__XXX
 SG_ FFEC_FrontMultiCaliStage : 8|4@1+ (1,0) [0|15] "" Vector__XXX
 SG_ FFEC_FrontSingleCaliStage : 0|4@1+ (1,0) [0|15] "" Vector__XXX

BO_ 2566908705 VCU_TWG: 7 Vector__XXX
 SG_ FFEB_WeightStatus : 16|4@1+ (1,0) [0|15] "" Vector__XXX
 SG_ FFEB_TotalWeightOfCurrentTruck : 40|16@1+ (1,0) [0|65535] "" Vector__XXX
 SG_ FFEB_BucketCountOfCurrentTruck : 24|16@1+ (1,0) [0|65535] "" Vector__XXX
 SG_ FFEB_RealtimeBucketWeight : 0|16@1+ (1,0) [0|65535] "kg" Vector__XXX

BO_ 2566908449 VCU_MWIG: 9 Vector__XXX
 SG_ FFEA_AssistStatus_SwingRight : 46|2@1+ (1,0) [0|3] "" Vector__XXX
 SG_ FFEA_AssistStatus_SwingLeft : 44|2@1+ (1,0) [0|3] "" Vector__XXX
 SG_ FFEA_AssistStatus_Grade : 40|2@1+ (1,0) [0|3] "" Vector__XXX
 SG_ FFEA_AssistStatus_Bucket : 42|2@1+ (1,0) [0|3] "" Vector__XXX
 SG_ FFEA_SafeWorkingIndi_SideFar : 36|2@1+ (1,0) [0|3] "" Vector__XXX
 SG_ FFEA_SafeWorkingIndi_SideMid : 34|2@1+ (1,0) [0|3] "" Vector__XXX
 SG_ FFEA_SafeWorkingIndi_SideNear : 32|2@1+ (1,0) [0|3] "" Vector__XXX
 SG_ FFEA_SafeWorkingIndi_FrontFar : 28|2@1+ (1,0) [0|3] "" Vector__XXX
 SG_ FFEA_SafeWorkingIndi_FrontMid : 26|2@1+ (1,0) [0|3] "" Vector__XXX
 SG_ FFEA_SafeWorkingIndi_FrontNear : 24|2@1+ (1,0) [0|3] "" Vector__XXX
 SG_ FFEA_FrontMoveGuide_ArmOut : 22|2@1+ (1,0) [0|3] "" Vector__XXX
 SG_ FFEA_FrontMoveGuide_ArmIn : 20|2@1+ (1,0) [0|3] "" Vector__XXX
 SG_ FFEA_FrontMoveGuide_BoomDown : 18|2@1+ (1,0) [0|3] "" Vector__XXX
 SG_ FFEA_FrontMoveGuide_BoomUp : 16|2@1+ (1,0) [0|3] "" Vector__XXX
 SG_ FFEA_E_FenceWarning_Track : 14|2@1+ (1,0) [0|3] "" Vector__XXX
 SG_ FFEA_E_FenceWarning_Dozer : 12|2@1+ (1,0) [0|3] "" Vector__XXX
 SG_ FFEA_E_FenceWarning_Cabin : 10|2@1+ (1,0) [0|3] "" Vector__XXX
 SG_ FFEA_E_FenceWarning_SwingRight : 8|2@1+ (1,0) [0|3] "" Vector__XXX
 SG_ FFEA_E_FenceWarning_SwingLeft : 6|2@1+ (1,0) [0|3] "" Vector__XXX
 SG_ FFEA_E_FenceWarning_Ceiling : 4|2@1+ (1,0) [0|3] "" Vector__XXX
 SG_ FFEA_E_FenceWarning_Floor : 2|2@1+ (1,0) [0|3] "" Vector__XXX
 SG_ FFEA_E_FenceWarning_Wall : 0|2@1+ (1,0) [0|3] "" Vector__XXX

BO_ 2365571843 TCU_Message3toVCU: 8 Vector__XXX
 SG_ FFC3_BrakeAngleSensor2Percentage : 40|8@1+ (0.4,0) [0|100] "%" Vector__XXX
 SG_ FFC3_BrakeAngleSensor1Percentage : 32|8@1+ (0.4,0) [0|100] "%" Vector__XXX
 SG_ FFC3_FootPedalPercentage : 24|8@1+ (0.4,0) [0|100] "%" Vector__XXX
 SG_ FFC3_BrakeAngleSensor2Voltage : 16|8@1+ (0.025,0) [0|6.25] "V" Vector__XXX
 SG_ FFC3_BrakeAngleSensor1Voltage : 8|8@1+ (0.025,0) [0|6.25] "V" Vector__XXX
 SG_ FFC3_EngineControlDialVoltage : 0|8@1+ (0.025,0) [0|6.25] "V" Vector__XXX

BO_ 2365571587 TCU_Message2toVCU: 8 Vector__XXX
 SG_ FFC2_LHTravelMotorSpeedSensor : 48|16@1+ (0.0078125,0) [0|501] "Hz" Vector__XXX
 SG_ FFC2_RHTravelMotorSpeedSensor : 32|16@1+ (0.0078125,0) [0|501] "Hz" Vector__XXX
 SG_ FFC2_LHRTravelPumpPressureSensor : 24|8@1+ (0.025,0) [0|6.25] "V" Vector__XXX
 SG_ FFC2_LHFTravelPumpPressureSensor : 16|8@1+ (0.025,0) [0|6.25] "V" Vector__XXX
 SG_ FFC2_RHRTravelPumpPressureSensor : 8|8@1+ (0.025,0) [0|6.25] "V" Vector__XXX
 SG_ FFC2_RHFTravelPumpPressureSensor : 0|8@1+ (0.025,0) [0|6.25] "V" Vector__XXX

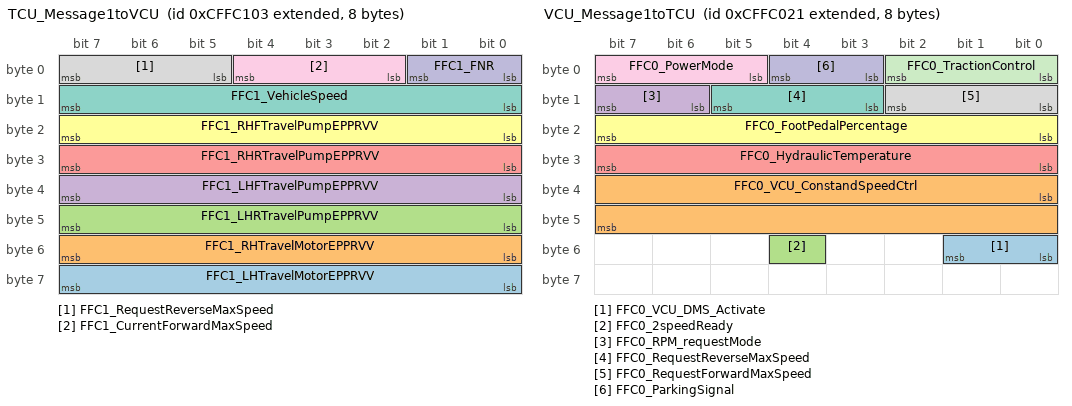
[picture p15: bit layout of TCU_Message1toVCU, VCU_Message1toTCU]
BO_ 2365571331 TCU_Message1toVCU: 8 Vector__XXX
 SG_ FFC1_LHTravelMotorEPPRVV : 56|8@1- (5,0) [0|635] "mA" Vector__XXX
 SG_ FFC1_RHTravelMotorEPPRVV : 48|8@1- (5,0) [0|635] "mA" Vector__XXX
 SG_ FFC1_LHRTravelPumpEPPRVV : 40|8@1+ (5,0) [0|1250] "mA" Vector__XXX
 SG_ FFC1_LHFTravelPumpEPPRVV : 32|8@1- (5,0) [0|635] "mA" Vector__XXX
 SG_ FFC1_RHRTravelPumpEPPRVV : 24|8@1+ (5,0) [0|1250] "mA" Vector__XXX
 SG_ FFC1_RHFTravelPumpEPPRVV : 16|8@1- (5,0) [0|635] "mA" Vector__XXX
 SG_ FFC1_VehicleSpeed : 8|8@1+ (0.125,0) [0|31.25] "km/h" Vector__XXX
 SG_ FFC1_RequestReverseMaxSpeed : 5|3@1+ (1,0) [0|7] "" Vector__XXX
 SG_ FFC1_CurrentForwardMaxSpeed : 2|3@1+ (1,0) [0|7] "" Vector__XXX
 SG_ FFC1_FNR : 0|2@1+ (1,0) [0|3] "" Vector__XXX

BO_ 2365571105 VCU_Message1toTCU: 8 Vector__XXX
 SG_ FFC0_VCU_DMS_Activate : 48|2@1+ (1,0) [0|3] "" Vector__XXX
 SG_ FFC0_VCU_ConstandSpeedCtrl : 32|16@1+ (0.125,0) [0|8031.875] "%" Vector__XXX
 SG_ FFC0_2speedReady : 52|1@1+ (1,0) [0|1] "" Vector__XXX
 SG_ FFC0_RPM_requestMode : 14|2@1+ (1,0) [0|3] "" Vector__XXX
 SG_ FFC0_HydraulicTemperature : 24|8@1- (1,-40) [-40|87] "deg" Vector__XXX
 SG_ FFC0_FootPedalPercentage : 16|8@1+ (0.4,0) [0|100] "%" Vector__XXX
 SG_ FFC0_RequestReverseMaxSpeed : 11|3@1+ (1,0) [0|7] "" Vector__XXX
 SG_ FFC0_RequestForwardMaxSpeed : 8|3@1+ (1,0) [0|7] "" Vector__XXX
 SG_ FFC0_PowerMode : 5|3@1+ (1,0) [0|7] "" Vector__XXX
 SG_ FFC0_ParkingSignal : 3|2@1+ (1,0) [0|3] "" Vector__XXX
 SG_ FFC0_TractionControl : 0|3@1+ (1,0) [0|7] "" Vector__XXX

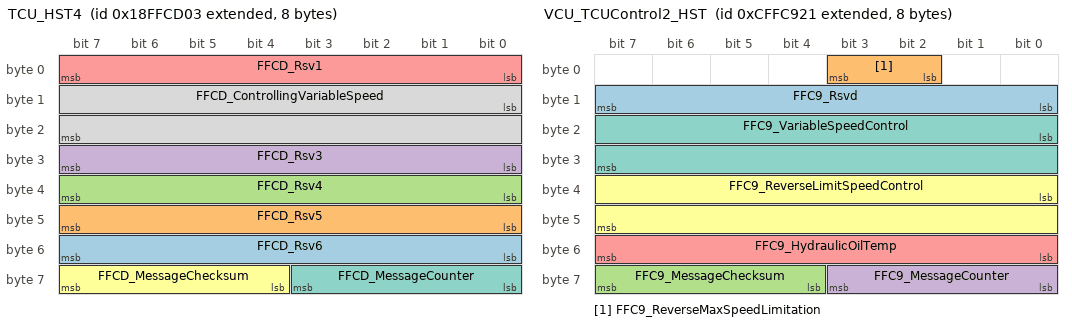
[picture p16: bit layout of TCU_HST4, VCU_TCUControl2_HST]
BO_ 2566900995 TCU_HST4: 8 Vector__XXX
 SG_ FFCD_Rsv6 : 48|8@1+ (1,0) [0|255] "" Vector__XXX
 SG_ FFCD_Rsv5 : 40|8@1+ (1,0) [0|255] "" Vector__XXX
 SG_ FFCD_Rsv4 : 32|8@1+ (1,0) [0|255] "" Vector__XXX
 SG_ FFCD_Rsv3 : 24|8@1+ (1,0) [0|255] "" Vector__XXX
 SG_ FFCD_Rsv1 : 0|8@1+ (1,0) [0|255] "" Vector__XXX
 SG_ FFCD_MessageChecksum : 60|4@1+ (1,0) [0|15] "" Vector__XXX
 SG_ FFCD_MessageCounter : 56|4@1+ (1,0) [0|15] "" Vector__XXX
 SG_ FFCD_ControllingVariableSpeed : 8|16@1+ (0.2,0) [0|50] "km/h" Vector__XXX

BO_ 2365573409 VCU_TCUControl2_HST: 8 Vector__XXX
 SG_ FFC9_Rsvd : 8|8@1+ (1,0) [0|255] "" Vector__XXX
 SG_ FFC9_ReverseMaxSpeedLimitation : 2|2@1+ (1,0) [0|3] "" Vector__XXX
 SG_ FFC9_MessageChecksum : 60|4@1- (1,0) [-8|7] "" Vector__XXX
 SG_ FFC9_MessageCounter : 56|4@1+ (1,0) [0|15] "" Vector__XXX
 SG_ FFC9_HydraulicOilTemp : 48|8@1+ (1,-30) [0|145] "deg" Vector__XXX
 SG_ FFC9_ReverseLimitSpeedControl : 32|16@1+ (0.2,0) [0|50] "km/h" Vector__XXX
 SG_ FFC9_VariableSpeedControl : 16|16@1+ (0.2,0) [0|50] "km/h" Vector__XXX

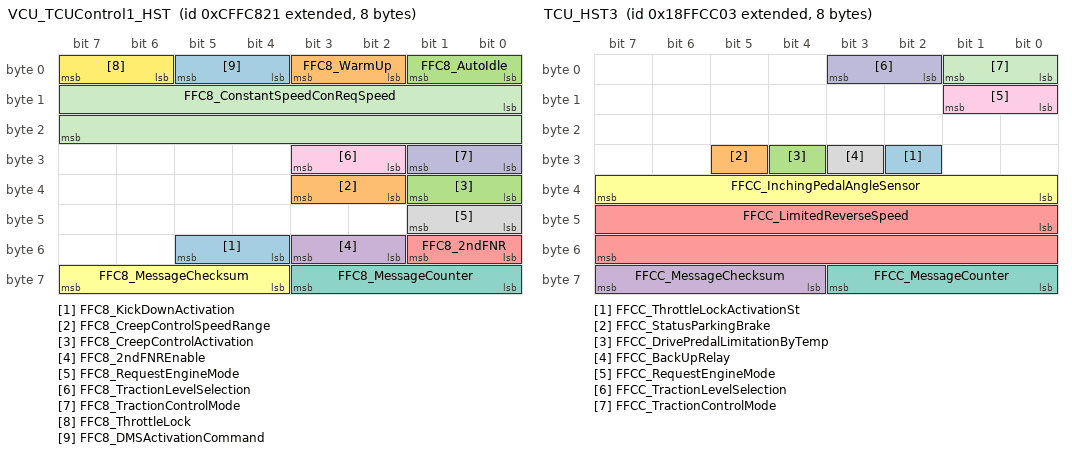
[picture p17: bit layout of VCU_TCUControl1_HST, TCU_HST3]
BO_ 2365573153 VCU_TCUControl1_HST: 8 Vector__XXX
 SG_ FFC8_KickDownActivation : 52|2@1+ (1,0) [0|3] "" Vector__XXX
 SG_ FFC8_CreepControlSpeedRange : 34|2@1+ (1,0) [0|3] "" Vector__XXX
 SG_ FFC8_CreepControlActivation : 32|2@1+ (1,0) [0|3] "" Vector__XXX
 SG_ FFC8_2ndFNREnable : 50|2@1+ (1,0) [0|3] "" Vector__XXX
 SG_ FFC8_2ndFNR : 48|2@1+ (1,0) [0|3] "" Vector__XXX
 SG_ FFC8_MessageChecksum : 60|4@1+ (1,0) [0|15] "" Vector__XXX
 SG_ FFC8_MessageCounter : 56|4@1+ (1,0) [0|15] "" Vector__XXX
 SG_ FFC8_RequestEngineMode : 40|2@1+ (1,0) [0|3] "" Vector__XXX
 SG_ FFC8_TractionLevelSelection : 26|2@1+ (1,0) [0|3] "" Vector__XXX
 SG_ FFC8_TractionControlMode : 24|2@1+ (1,0) [0|3] "" Vector__XXX
 SG_ FFC8_ConstantSpeedConReqSpeed : 8|16@1+ (0.125,0) [0|8191.875] "rpm" Vector__XXX
 SG_ FFC8_ThrottleLock : 6|2@1+ (1,0) [0|3] "" Vector__XXX
 SG_ FFC8_DMSActivationCommand : 4|2@1+ (1,0) [0|3] "" Vector__XXX
 SG_ FFC8_WarmUp : 2|2@1+ (1,0) [0|3] "" Vector__XXX
 SG_ FFC8_AutoIdle : 0|2@1+ (1,0) [0|3] "" Vector__XXX

BO_ 2566900739 TCU_HST3: 8 Vector__XXX
 SG_ FFCC_ThrottleLockActivationSt : 26|1@1+ (1,0) [0|1] "" Vector__XXX
 SG_ FFCC_StatusParkingBrake : 29|1@1+ (1,0) [0|1] "" Vector__XXX
 SG_ FFCC_DrivePredalLimitationByTemp : 28|1@1+ (1,0) [0|1] "" Vector__XXX
 SG_ FFCC_MessageChecksum : 60|4@1+ (1,0) [0|15] "" Vector__XXX
 SG_ FFCC_LimitedReverseSpeed : 40|16@1+ (0.2,0) [0|50] "km/h" Vector__XXX
 SG_ FFCC_InchingPedalAngleSensor : 32|8@1+ (0.025,0) [0|6.25] "V" Vector__XXX
 SG_ FFCC_MessageCounter : 56|4@1+ (1,0) [0|15] "" Vector__XXX
 SG_ FFCC_BackUpRelay : 27|1@1+ (1,0) [0|1] "" Vector__XXX
 SG_ FFCC_RequestEngineMode : 8|2@1+ (1,0) [0|3] "" Vector__XXX
 SG_ FFCC_TractionLevelSelection : 2|2@1+ (1,0) [0|3] "" Vector__XXX
 SG_ FFCC_TractionControlMode : 0|2@1+ (1,0) [0|3] "" Vector__XXX

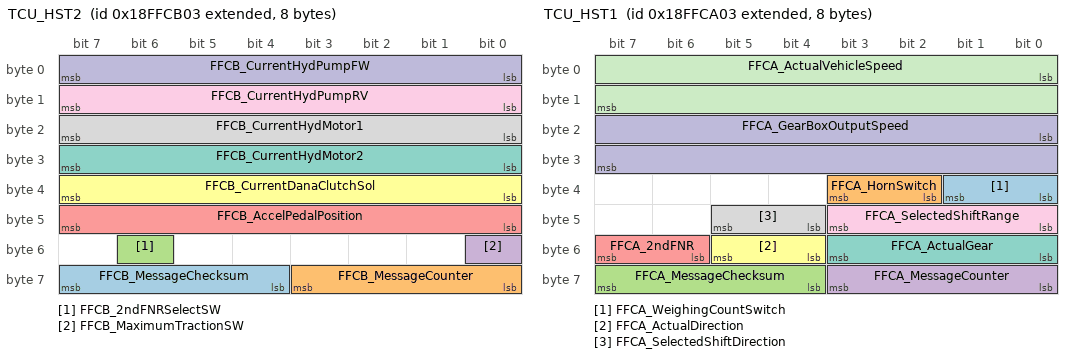
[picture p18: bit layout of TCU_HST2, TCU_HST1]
BO_ 2566900483 TCU_HST2: 8 Vector__XXX
 SG_ FFCB_MessageChecksum : 60|4@1+ (1,0) [0|15] "" Vector__XXX
 SG_ FFCB_MessageCounter : 56|4@1+ (1,0) [0|15] "" Vector__XXX
 SG_ FFCB_2ndFNRSelectSW : 54|1@1+ (1,0) [0|1] "" Vector__XXX
 SG_ FFCB_MaximumTractionSW : 48|1@1+ (1,0) [0|1] "" Vector__XXX
 SG_ FFCB_AccelPedalPosition : 40|8@1+ (0.4,0) [0|100] "%" Vector__XXX
 SG_ FFCB_CurrentDanaClutchSol : 32|8@1+ (5,0) [0|1250] "mA" Vector__XXX
 SG_ FFCB_CurrentHydMotor2 : 24|8@1+ (5,0) [0|1250] "mA" Vector__XXX
 SG_ FFCB_CurrentHydMotor1 : 16|8@1+ (5,0) [0|1250] "mA" Vector__XXX
 SG_ FFCB_CurrentHydPumpRV : 8|8@1+ (5,0) [0|1250] "mA" Vector__XXX
 SG_ FFCB_CurrentHydPumpFW : 0|8@1+ (5,0) [0|1250] "mA" Vector__XXX

BO_ 2566900227 TCU_HST1: 8 Vector__XXX
 SG_ FFCA_WeighingCountSwitch : 32|2@1+ (1,0) [0|3] "" Vector__XXX
 SG_ FFCA_HornSwitch : 34|2@1+ (1,0) [0|3] "" Vector__XXX
 SG_ FFCA_MessageChecksum : 60|4@1+ (1,0) [0|15] "" Vector__XXX
 SG_ FFCA_MessageCounter : 56|4@1+ (1,0) [0|15] "" Vector__XXX
 SG_ FFCA_2ndFNR : 54|2@1+ (1,0) [0|3] "" Vector__XXX
 SG_ FFCA_ActualDirection : 52|2@1+ (1,0) [0|3] "" Vector__XXX
 SG_ FFCA_ActualGear : 48|4@1+ (1,0) [0|15] "" Vector__XXX
 SG_ FFCA_SelectedShiftDirection : 44|2@1+ (1,0) [0|3] "" Vector__XXX
 SG_ FFCA_SelectedShiftRange : 40|4@1+ (1,0) [0|15] "" Vector__XXX
 SG_ FFCA_GearBoxOutputSpeed : 16|16@1+ (0.125,0) [0|8191.875] "rpm" Vector__XXX
 SG_ FFCA_ActualVehicleSpeed : 0|16@1+ (0.2,0) [0|50] "km/h" Vector__XXX

BO_ 2566733312 ECU_ATS1SCRExGasTemp: 8 Vector__XXX
 SG_ FD3E_ATS1SCRcataOurtakeGasTemp : 24|16@1+ (0.03125,-273) [-273|1734.96875] "C" Vector__XXX
 SG_ FD3E_ATS1SCRcataIntakeGasTemp : 0|16@1+ (0.03125,-273) [-273|1734.96875] "C" Vector__XXX

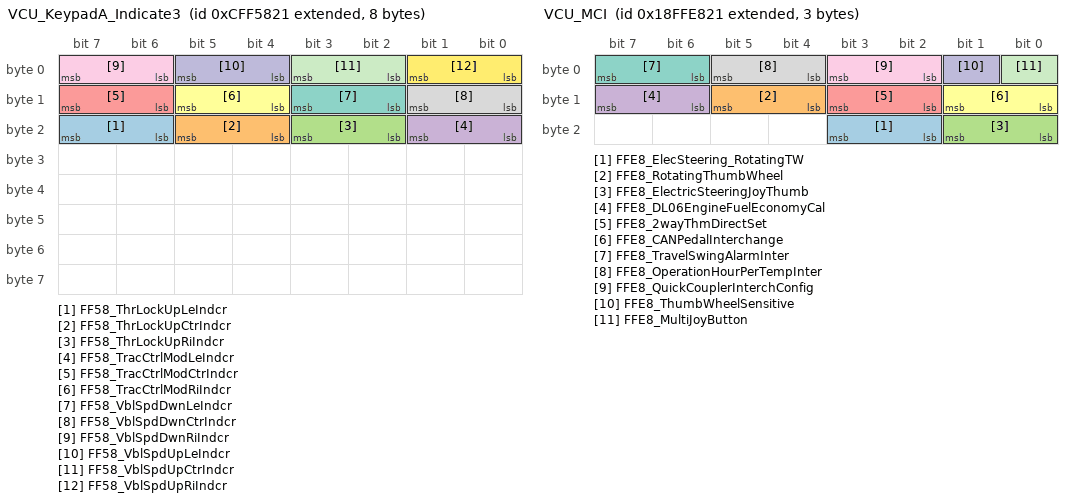
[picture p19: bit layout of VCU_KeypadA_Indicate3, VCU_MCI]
BO_ 2365544481 VCU_KeypadA_Indicate3: 8 Vector__XXX
 SG_ FF58_ThrLockUpLeIndcr : 22|2@1+ (1,0) [0|3] "" Vector__XXX
 SG_ FF58_ThrLockUpCtrIndcr : 20|2@1+ (1,0) [0|3] "" Vector__XXX
 SG_ FF58_ThrLockUpRiIndcr : 18|2@1+ (1,0) [0|3] "" Vector__XXX
 SG_ FF58_TracCtrlModLeIndcr : 16|2@1+ (1,0) [0|3] "" Vector__XXX
 SG_ FF58_TracCtrlModCtrIndcr : 14|2@1+ (1,0) [0|3] "" Vector__XXX
 SG_ FF58_TracCtrlModRiIndcr : 12|2@1+ (1,0) [0|3] "" Vector__XXX
 SG_ FF58_VblSpdDwnLeIndcr : 10|2@1+ (1,0) [0|3] "" Vector__XXX
 SG_ FF58_VblSpdDwnCtrIndcr : 8|2@1+ (1,0) [0|3] "" Vector__XXX
 SG_ FF58_VblSpdDwnRiIndcr : 6|2@1+ (1,0) [0|3] "" Vector__XXX
 SG_ FF58_VblSpdUpLeIndcr : 4|2@1+ (1,0) [0|3] "" Vector__XXX
 SG_ FF58_VblSpdUpCtrIndcr : 2|2@1+ (1,0) [0|3] "" Vector__XXX
 SG_ FF58_VblSpdUpRiIndcr : 0|2@1+ (1,0) [0|3] "" Vector__XXX

BO_ 2565406497 VCU_ACK_Message: 8 Vector__XXX
 SG_ E8FF_PGNofRequestedInformation : 40|24@1+ (1,0) [0|16777215] "" Vector__XXX
 SG_ E8FF_GroupFunctionValue : 8|8@1+ (1,0) [0|255] "" Vector__XXX
 SG_ E8FF_ControlByte : 0|8@1+ (1,0) [0|255] "" Vector__XXX
 SG_ E8FF_AddressAcknowledged : 32|8@1+ (1,0) [0|255] "" Vector__XXX

BO_ 2566907937 VCU_MCI: 3 Vector__XXX
 SG_ FFE8_ElecSteering_RotatingTW : 18|2@1+ (1,0) [0|3] "" Vector__XXX
 SG_ FFE8_RotatingThumbWheel : 12|2@1+ (1,0) [0|3] "" Vector__XXX
 SG_ FFE8_ElectricSteeringJoyThumb : 16|2@1+ (1,0) [0|3] "" Vector__XXX
 SG_ FFE8_DL06EngineFuelEconomyCal : 14|2@1+ (1,0) [0|3] "" Vector__XXX
 SG_ FFE8_2wayThmDirectSet : 10|2@1+ (1,0) [0|3] "" Vector__XXX
 SG_ FFE8_CANPedalInterchange : 8|2@1+ (1,0) [0|3] "" Vector__XXX
 SG_ FFE8_TravelSwingAlarmInter : 6|2@1+ (1,0) [0|3] "" Vector__XXX
 SG_ FFE8_OperationHourPerTempInter : 4|2@1+ (1,0) [0|3] "" Vector__XXX
 SG_ FFE8_QuickCouplerInterchConfig : 2|2@1+ (1,0) [0|3] "" Vector__XXX
 SG_ FFE8_ThumbWheelSensitive : 1|1@1+ (1,0) [0|1] "" Vector__XXX
 SG_ FFE8_MultiJoyButton : 0|1@1+ (1,0) [0|1] "" Vector__XXX

BO_ 2566866465 VCU_UPD: 8 Vector__XXX
 SG_ FF46_ArmAngleInformation : 56|8@1+ (1,0) [0|255] "" Vector__XXX
 SG_ FF46_Reserved2 : 32|24@1+ (1,0) [0|16777215] "" Vector__XXX
 SG_ FF46_Reserved : 27|5@1+ (1,0) [0|31] "" Vector__XXX
 SG_ FF46_DesignDepth2 : 26|1@1+ (1,0) [0|1] "" Vector__XXX
 SG_ FF46_DesignDepth1 : 25|1@1+ (1,0) [0|1] "" Vector__XXX
 SG_ FF46_DoubleGradient2 : 24|1@1+ (1,0) [0|1] "" Vector__XXX
 SG_ FF46_DoubleGradient1 : 23|1@1+ (1,0) [0|1] "" Vector__XXX
 SG_ FF46_DesignData2 : 22|1@1+ (1,0) [0|1] "" Vector__XXX
 SG_ FF46_DesignData1 : 21|1@1+ (1,0) [0|1] "" Vector__XXX
 SG_ FF46_UserSurface2 : 20|1@1+ (1,0) [0|1] "" Vector__XXX
 SG_ FF46_UserSurface1 : 19|1@1+ (1,0) [0|1] "" Vector__XXX
 SG_ FF46_GradientCon2 : 18|1@1+ (1,0) [0|1] "" Vector__XXX
 SG_ FF46_GradientCon1 : 17|1@1+ (1,0) [0|1] "" Vector__XXX
 SG_ FF46_StandardPointUnselectSignal : 5|1@1+ (1,0) [0|1] "" Vector__XXX
 SG_ FF46_LaserAndTouchPointSignal : 4|1@1+ (1,0) [0|1] "" Vector__XXX
 SG_ FF46_BenchmarkSignal : 3|1@1+ (1,0) [0|1] "" Vector__XXX
 SG_ FF46_CameraSignal : 2|1@1+ (1,0) [0|1] "" Vector__XXX
 SG_ FF46_AudioMuteSignal : 1|1@1+ (1,0) [0|1] "" Vector__XXX
 SG_ FF46_Weighig_TruckCancel : 11|1@1+ (1,0) [0|1] "" Vector__XXX
 SG_ FF46_Weighing_TruckStore : 10|1@1+ (1,0) [0|1] "" Vector__XXX
 SG_ FF46_Weighing_BucketRecall : 9|1@1+ (1,0) [0|1] "" Vector__XXX
 SG_ FF46_Weighing_BucketCancel : 8|1@1+ (1,0) [0|1] "" Vector__XXX
 SG_ FF46_Weighing_Reweigh : 7|1@1+ (1,0) [0|1] "" Vector__XXX
 SG_ FF46_Weighing_On_Off : 6|1@1+ (1,0) [0|1] "" Vector__XXX
 SG_ FF46_MC_BucketAssist : 16|1@1+ (1,0) [0|1] "" Vector__XXX
 SG_ FF46_MC_SwingAssist_Right : 15|1@1+ (1,0) [0|1] "" Vector__XXX
 SG_ FF46_MC_SwingAssist_Left : 14|1@1+ (1,0) [0|1] "" Vector__XXX
 SG_ FF46_MC_GradeAssist_Mode_Select : 12|1@1+ (1,0) [0|1] "" Vector__XXX
 SG_ FF46_MC_GradeAssist_Precision : 13|1@1+ (1,0) [0|1] "" Vector__XXX
 SG_ FF46_MultiJoyButSignal : 0|1@1+ (1,0) [0|1] "" Vector__XXX

BO_ 2566769441 VCU_EngineControlSelect: 3 Vector__XXX
 SG_ FDCB_EngineDroopSelect : 16|4@1+ (1,0) [0|15] "" Vector__XXX

BO_ 2565865728 ECU_EBC1: 8 Vector__XXX
 SG_ F001_EngAuxShDnSW : 28|2@1+ (1,0) [0|3] "" Vector__XXX

BO_ 2566840209 ECU_EEC3_SA91: 8 Vector__XXX
 SG_ EEC3ATS1ExhaustGasMassFlow : 40|16@1+ (0.2,0) [0|12851] "kg/h" Vector__XXX
 SG_ EEC3EnginesDesiredOpSpeed : 8|16@1+ (0.125,0) [0|8031.875] "rpm" Vector__XXX
 SG_ EEC3EstimEngParaLossesPercTorque : 32|8@1+ (1,-125) [-125|125] "%" Vector__XXX
 SG_ EEC3NominalFrictionPercentTorque : 0|8@1+ (1,-125) [-125|125] "%" Vector__XXX

BO_ 2566846353 ECU_VEP1_SA91: 8 Vector__XXX
 SG_ NetBatteryCurrent : 0|8@1+ (1,-125) [-125|125] "A" Vector__XXX
 SG_ AlternatorCurrent : 8|8@1+ (1,0) [0|250] "A" Vector__XXX
 SG_ ChargingSystemPotential : 16|16@1+ (0.05,0) [0|3212.75] "V" Vector__XXX
 SG_ BatteryPotentialPowerInput1 : 32|16@1+ (0.05,0) [0|3212.75] "V" Vector__XXX
 SG_ KeyswitchBatteryPotential : 48|16@1+ (0.05,0) [0|3212.75] "V" Vector__XXX

BO_ 2566704273 ECU_EEC12_SA91: 8 Vector__XXX
 SG_ FCCC_Af1OutGasSenPwrSupply : 2|2@1+ (1,0) [0|3] "" Vector__XXX
 SG_ FCCC_Af1InGasSenPwrSupply : 0|2@1+ (1,0) [0|3] "" Vector__XXX

BO_ 2566700542 ECU_A1SCRSI2_SA91: 8 Vector__XXX
 SG_ FCBD_Af1TotalDieExFluUsed : 0|32@1+ (0.5,0) [0|2105540607.5] "Liter" Vector__XXX

BO_ 2566699409 ECU_AT1S2_SA91: 8 Vector__XXX
 SG_ FCB9_Af1DPFTimeToNextActRegen : 0|32@1+ (1,0) [0|4211081215] "Sec" Vector__XXX

BO_ 2566826496 ECU_AF2_SA91: 8 Vector__XXX
 SG_ FEAA_EngInManiAbPress : 8|16@1+ (0.1,0) [0|6425.5] "kPa" Vector__XXX

BO_ 2562785280 ECU_DM21: 8 Vector__XXX
 SG_ C100_MinRunByEngMilAct : 32|16@1+ (1,0) [0|64255] "Min" Vector__XXX
 SG_ C100_At1TotalFuelUsed : 0|16@1+ (1,0) [0|65535] "" Vector__XXX

BO_ 2566756352 ECU_At1HI: 48 Vector__XXX
 SG_ FD98_At1TotalFuelUsed : 0|32@1+ (0.5,0) [0|2105540607.5] "L" Vector__XXX

BO_ 2566768128 ECU_ColdStartAids: 8 Vector__XXX
 SG_ FDC6_EngColdEnableDev1 : 0|2@1+ (1,0) [0|3] "" Vector__XXX

BO_ 2164178944 ECU_SI: 8 Vector__XXX
 SG_ FEC0_SerCompId : 0|8@1+ (1,0) [0|250] "" Vector__XXX

BO_ 2633825280 ECU_EMAC: 8 Vector__XXX
 SG_ FCFC_EngiExhMani1BalValActCTRL : 0|16@1+ (0.0025,0) [0|160.6375] "%" Vector__XXX

BO_ 2565873920 ECU_ESSI: 8 Vector__XXX
 SG_ F021_EngSpdSen1TimePatStatus : 54|2@1+ (1,0) [0|3] "" Vector__XXX
 SG_ F021_EngSpdSen2TimePatStatus : 52|2@1+ (1,0) [0|3] "" Vector__XXX
 SG_ F021_EngSpeed2 : 16|16@1+ (0.5,0) [0|32127.5] "rpm" Vector__XXX
 SG_ F021_EngSpeed1 : 0|16@1+ (0.5,0) [0|32127.5] "rpm" Vector__XXX

BO_ 2566749329 ECU_DPFC1_SA91: 8 Vector__XXX
 SG_ DieselParticulateFilterLampCmd : 0|3@1+ (1,0) [0|7] "" Vector__XXX
 SG_ AftrtrtmntDslPFPassiveRegenStat : 8|2@1+ (1,0) [0|3] "" Vector__XXX
 SG_ AftrtrtmntDslPFActvRegenStatus : 10|2@1+ (1,0) [0|3] "" Vector__XXX
 SG_ AftrtrtmntDslPFStatus : 12|3@1+ (1,0) [0|7] "" Vector__XXX
 SG_ DslPFActvRegenInhbtdStatus : 16|2@1+ (1,0) [0|3] "" Vector__XXX
 SG_ DslPFActvRegenInhbtdDTInhbtSw : 18|2@1+ (1,0) [0|3] "" Vector__XXX
 SG_ DslPFActRegenInhbtdDTCltchDiseng : 20|2@1+ (1,0) [0|3] "" Vector__XXX
 SG_ DslPFActRegenInhbtdDTSrvcBrkActv : 22|2@1+ (1,0) [0|3] "" Vector__XXX
 SG_ DslPFActvRegenInhbtdDTPTOActv : 24|2@1+ (1,0) [0|3] "" Vector__XXX
 SG_ DPFActRegenInhbtdDTAcclPdlOffIdl : 26|2@1+ (1,0) [0|3] "" Vector__XXX
 SG_ DslPFActvRegenInhbtdDTOutOfNtrl : 28|2@1+ (1,0) [0|3] "" Vector__XXX
 SG_ DPFActRegInhDTVhclSpdAbvAllwdSpd : 30|2@1+ (1,0) [0|3] "" Vector__XXX
 SG_ DPFActRegenInhbtdDTPrkBrkNotSet : 32|2@1+ (1,0) [0|3] "" Vector__XXX
 SG_ DPFActRegenInhbtdDTLowExhstTemp : 34|2@1+ (1,0) [0|3] "" Vector__XXX
 SG_ DslPFActRegenInhbtdDTSysFaultAct : 36|2@1+ (1,0) [0|3] "" Vector__XXX
 SG_ DslPFActvRegenInhbtdDTSysTimeout : 38|2@1+ (1,0) [0|3] "" Vector__XXX
 SG_ DPFActRegenInhbtdDTTmprySysLckt : 40|2@1+ (1,0) [0|3] "" Vector__XXX
 SG_ DPFActRegenInhbtdDTPrmntSysLckt : 42|2@1+ (1,0) [0|3] "" Vector__XXX
 SG_ DPFActRegInhbtdDTEngNotWarmedUp : 44|2@1+ (1,0) [0|3] "" Vector__XXX
 SG_ DPFActRegInhDTVhclSpdBlwAllwdSpd : 46|2@1+ (1,0) [0|3] "" Vector__XXX
 SG_ DslPFAutoActvRegenInitConf : 48|2@1+ (1,0) [0|3] "" Vector__XXX
 SG_ ExhstSystemHghTemperatureLampCmd : 50|3@1+ (1,0) [0|7] "" Vector__XXX
 SG_ DslPFActvRegenForcedStatus : 53|3@1+ (1,0) [0|7] "" Vector__XXX
 SG_ HydrocarbonDoserPurgingEnable : 56|2@1+ (1,0) [0|3] "" Vector__XXX
 SG_ DPFActRegenInhbtdDTLowExhstPress : 58|2@1+ (1,0) [0|3] "" Vector__XXX
 SG_ Aft1DPFConditionsNotMetForActReg : 60|2@1+ (1,0) [0|3] "" Vector__XXX

BO_ 2566749073 ECU_AT1S1_SA91: 8 Vector__XXX
 SG_ Aftrtrtmnt1DslPFSootLoadPercent : 0|8@1+ (1,0) [0|250] "%" Vector__XXX
 SG_ Aftrtrtmnt1DslPFAshLoadPercent : 8|8@1+ (1,0) [0|250] "%" Vector__XXX
 SG_ Aft1DslPFTmeSncLastActvRegen : 16|32@1+ (1,0) [0|4211081215] "s" Vector__XXX
 SG_ Aft1DslPFSootLoadRegenTrshld : 48|16@1+ (0.0025,0) [0|160.6375] "%" Vector__XXX

BO_ 2566711296 ECU_IVAC: 8 Vector__XXX
 SG_ FCE8_IntVavOilPress1SolCTRL : 0|2@1+ (1,0) [0|3] "" Vector__XXX

BO_ 2558918400 ECU_CM2: 8 Vector__XXX
 SG_ AtRegenEngSpdAllowSW : 30|2@1+ (1,0) [0|3] "" Vector__XXX
 SG_ ElevEngSpdAllowSW : 28|2@1+ (1,0) [0|3] "" Vector__XXX

BO_ 2431654400 ECU_ETFACC: 8 Vector__XXX
 SG_ F01A_EngThroAct1CTRLCommand : 0|16@1+ (0.0025,0) [0|160.6375] "%" Vector__XXX

BO_ 2566835089 DM02_for_Multi_SA91: 42 Vector__XXX
 SG_ FECA_10_SPNConversionMethod : 335|1@1+ (1,0) [0|1] "" Vector__XXX
 SG_ FECA_10_SPN3 : 325|3@1+ (1,0) [0|7] "" Vector__XXX
 SG_ FECA_10_SPN1_2 : 304|16@1+ (1,0) [0|65535] "" Vector__XXX
 SG_ FECA_10_OccurenceCount : 328|7@1+ (1,0) [0|127] "" Vector__XXX
 SG_ FECA_10_FMI : 320|5@1+ (1,0) [0|31] "" Vector__XXX
 SG_ FECA_09_SPNConversionMethod : 303|1@1+ (1,0) [0|1] "" Vector__XXX
 SG_ FECA_09_SPN3 : 293|3@1+ (1,0) [0|7] "" Vector__XXX
 SG_ FECA_09_SPN1_2 : 272|16@1+ (1,0) [0|65535] "" Vector__XXX
 SG_ FECA_09_OccurenceCount : 296|7@1+ (1,0) [0|127] "" Vector__XXX
 SG_ FECA_09_FMI : 288|5@1+ (1,0) [0|31] "" Vector__XXX
 SG_ FECA_08_SPNConversionMethod : 271|1@1+ (1,0) [0|1] "" Vector__XXX
 SG_ FECA_08_SPN3 : 261|3@1+ (1,0) [0|7] "" Vector__XXX
 SG_ FECA_08_SPN1_2 : 240|16@1+ (1,0) [0|65535] "" Vector__XXX
 SG_ FECA_08_OccurenceCount : 264|7@1+ (1,0) [0|127] "" Vector__XXX
 SG_ FECA_08_FMI : 256|5@1+ (1,0) [0|31] "" Vector__XXX
 SG_ FECA_07_SPNConversionMethod : 239|1@1+ (1,0) [0|1] "" Vector__XXX
 SG_ FECA_07_SPN3 : 229|3@1+ (1,0) [0|7] "" Vector__XXX
 SG_ FECA_07_SPN1_2 : 208|16@1+ (1,0) [0|65535] "" Vector__XXX
 SG_ FECA_07_OccurenceCount : 232|7@1+ (1,0) [0|127] "" Vector__XXX
 SG_ FECA_07_FMI : 224|5@1+ (1,0) [0|31] "" Vector__XXX
 SG_ FECA_06_SPNConversionMethod : 207|1@1+ (1,0) [0|1] "" Vector__XXX
 SG_ FECA_06_SPN3 : 197|3@1+ (1,0) [0|7] "" Vector__XXX
 SG_ FECA_06_SPN1_2 : 176|16@1+ (1,0) [0|65535] "" Vector__XXX
 SG_ FECA_06_OccurenceCount : 200|7@1+ (1,0) [0|127] "" Vector__XXX
 SG_ FECA_06_FMI : 192|5@1+ (1,0) [0|31] "" Vector__XXX
 SG_ FECA_05_SPNConversionMethod : 175|1@1+ (1,0) [0|1] "" Vector__XXX
 SG_ FECA_05_SPN3 : 165|3@1+ (1,0) [0|7] "" Vector__XXX
 SG_ FECA_05_SPN1_2 : 144|16@1+ (1,0) [0|65535] "" Vector__XXX
 SG_ FECA_05_OccurenceCount : 168|7@1+ (1,0) [0|127] "" Vector__XXX
 SG_ FECA_05_FMI : 160|5@1+ (1,0) [0|31] "" Vector__XXX
 SG_ FECA_04_SPNConversionMethod : 143|1@1+ (1,0) [0|1] "" Vector__XXX
 SG_ FECA_04_SPN3 : 133|3@1+ (1,0) [0|7] "" Vector__XXX
 SG_ FECA_04_SPN1_2 : 112|16@1+ (1,0) [0|65535] "" Vector__XXX
 SG_ FECA_04_OccurenceCount : 136|7@1+ (1,0) [0|127] "" Vector__XXX
 SG_ FECA_04_FMI : 128|5@1+ (1,0) [0|31] "" Vector__XXX
 SG_ FECA_03_SPNConversionMethod : 111|1@1+ (1,0) [0|1] "" Vector__XXX
 SG_ FECA_03_SPN3 : 101|3@1+ (1,0) [0|7] "" Vector__XXX
 SG_ FECA_03_SPN1_2 : 80|16@1+ (1,0) [0|65535] "" Vector__XXX
 SG_ FECA_03_OccurenceCount : 104|7@1+ (1,0) [0|127] "" Vector__XXX
 SG_ FECA_03_FMI : 96|5@1+ (1,0) [0|31] "" Vector__XXX
 SG_ FECA_02_SPNConversionMethod : 79|1@1+ (1,0) [0|1] "" Vector__XXX
 SG_ FECA_02_SPN3 : 69|3@1+ (1,0) [0|7] "" Vector__XXX
 SG_ FECA_02_SPN1_2 : 48|16@1+ (1,0) [0|65535] "" Vector__XXX
 SG_ FECA_02_OccurenceCount : 72|7@1+ (1,0) [0|127] "" Vector__XXX
 SG_ FECA_02_FMI : 64|5@1+ (1,0) [0|31] "" Vector__XXX
 SG_ FECA_01_SPNConversionMethod : 47|1@1+ (1,0) [0|1] "" Vector__XXX
 SG_ FECA_01_SPN3 : 37|3@1+ (1,0) [0|7] "" Vector__XXX
 SG_ FECA_01_SPN1_2 : 16|16@1+ (1,0) [0|65535] "" Vector__XXX
 SG_ FECA_01_RedStopLampStatus : 4|2@1+ (1,0) [0|3] "" Vector__XXX
 SG_ FECA_01_ProtectLampStatus : 0|2@1+ (1,0) [0|3] "" Vector__XXX
 SG_ FECA_01_OccurenceCount : 40|7@1+ (1,0) [0|127] "" Vector__XXX
 SG_ FECA_01_MalFucIndicatorStatus : 6|2@1+ (1,0) [0|3] "" Vector__XXX
 SG_ FECA_01_FMI : 32|5@1+ (1,0) [0|31] "" Vector__XXX
 SG_ FECA_01_FlashRedStopLamp : 12|2@1+ (1,0) [0|3] "" Vector__XXX
 SG_ FECA_01_FlashProtectLamp : 8|2@1+ (1,0) [0|3] "" Vector__XXX
 SG_ FECA_01_FlashAmberLamp : 10|2@1+ (1,0) [0|3] "" Vector__XXX
 SG_ FECA_01_Flash_MalFuncIndiLamp : 14|2@1+ (1,0) [0|3] "" Vector__XXX
 SG_ FECA_01_AmberWarmingLampStatus : 2|2@1+ (1,0) [0|3] "" Vector__XXX

CM_ BO_ 2566757120 "Aftertreatment 1 Diesel Exhaust Fluid Information";
CM_ SG_ 2566890792 FFA5_JoystickPatternChange "uint_8";
CM_ BO_ 2566847015 "Brakes";
CM_ SG_ 2566847015 BParkingBrakeActuator "Signal which indicates the current state of the actuator(s) that control the parking brake (see also SPN 70).";
CM_ BO_ 2364539943 "Electronic Engine Controller 1";
CM_ BO_ 2565482535 "Request";
CM_ SG_ 2565482535 ParameterGroupNumber "PGN which is requested by Request2 message";
CM_ BO_ 2565472295 "Request";
CM_ BO_ 2348810279 "Torque/Speed Control 1";
CM_ BO_ 2364539937 "Electronic Engine Controller 1";
CM_ BO_ 2566900227 "ZF Clutch Calibration";
CM_ BO_ 2566840209 "Electronic Engine Controller 3";
CM_ SG_ 2566840209 EEC3EnginesDesiredOpSpeed "Parameter provided to the engine from external sources in the torque/speed control message.";
CM_ BO_ 2566846353 "Vehicle Electrical Power 1";
CM_ BO_ 2566749329 "Diesel Particulate Filter Control 1";
CM_ BO_ 2566749073 "Aftertreatment 1 Service 1";
BA_DEF_  "BusType" STRING ;
BA_DEF_  "ProtocolType" STRING ;
BA_DEF_ BO_  "VFrameFormat" ENUM  "StandardCAN","ExtendedCAN","reserved","J1939PG";
BA_DEF_ BO_  "GenMsgCycleTime" INT 0 65535;
BA_DEF_ SG_  "GenSigStartValue" FLOAT -3.4E+038 3.4E+038;
BA_DEF_ SG_  "SPN" INT -3.4E+038 3.4E+038;
BA_DEF_ SG_  "SigType" ENUM  "Default","Range","RangeSigned","ASCII","Discrete","Control","ReferencePGN","DTC","StringDelimiter","StringLength","StringLengthControl","MessageCounter","MessageChecksum";
BA_DEF_DEF_  "BusType" "CAN";
BA_DEF_DEF_  "ProtocolType" "J1939";
BA_DEF_DEF_  "VFrameFormat" "J1939PG";
BA_DEF_DEF_  "GenMsgCycleTime" 0;
BA_DEF_DEF_  "GenSigStartValue" 0;
BA_DEF_DEF_  "SPN" 0;
BA_DEF_DEF_  "SigType" "Default";
BA_ "GenMsgCycleTime" BO_ 2566757120 1000;
BA_ "GenMsgCycleTime" BO_ 2365544225 100;
BA_ "GenMsgCycleTime" BO_ 2365543760 100;
BA_ "GenMsgCycleTime" BO_ 2365543248 100;
BA_ "GenMsgCycleTime" BO_ 2566847015 1000;
BA_ "GenMsgCycleTime" BO_ 2364539943 10;
BA_ "GenMsgCycleTime" BO_ 2565876164 10;
BA_ "GenMsgCycleTime" BO_ 2565876163 10;
BA_ "GenMsgCycleTime" BO_ 2365445940 100;
BA_ "GenMsgCycleTime" BO_ 2365445684 100;
BA_ "GenMsgCycleTime" BO_ 2365445939 100;
BA_ "GenMsgCycleTime" BO_ 2365445683 100;
BA_ "GenMsgCycleTime" BO_ 2566869288 100;
BA_ "GenMsgCycleTime" BO_ 2565875998 10;
BA_ "GenMsgCycleTime" BO_ 2348810279 10;
BA_ "GenMsgCycleTime" BO_ 2364539937 10;
BA_ "GenMsgCycleTime" BO_ 2566909473 100;
BA_ "GenMsgCycleTime" BO_ 2566909217 100;
BA_ "GenMsgCycleTime" BO_ 2566908961 100;
BA_ "GenMsgCycleTime" BO_ 2365571843 100;
BA_ "GenMsgCycleTime" BO_ 2365571587 100;
BA_ "GenMsgCycleTime" BO_ 2365571331 100;
BA_ "GenMsgCycleTime" BO_ 2365571105 100;
BA_ "GenMsgCycleTime" BO_ 2566900227 100;
BA_ "GenMsgCycleTime" BO_ 2566840209 250;
BA_ "GenMsgCycleTime" BO_ 2566846353 1000;
BA_ "GenMsgCycleTime" BO_ 2566749329 1000;
BA_ "GenSigStartValue" SG_ 2566757120 Aftrtrtmnt1DslExhstFldTemp2 40;
BA_ "SPN" SG_ 2566757120 Aftrtrtmnt1DslExhstFldTemp2 3515;
BA_ "SPN" SG_ 2566757120 Aft1DslExhstFldConcentration 3516;
BA_ "SPN" SG_ 2566757120 Aft1DslExhstFldConductivity 3518;
BA_ "SPN" SG_ 2566757120 Aft1DslExhstFldTemp2PrelimFMI 3519;
BA_ "SPN" SG_ 2566757120 Aft1DslExhstFldPropPrelimFMI 3520;
BA_ "SPN" SG_ 2566757120 Aftrtrtmnt1DslExhstFluidProperty 3521;
BA_ "GenSigStartValue" SG_ 2566722633 FD14_Bat_Charger2_OutputCurrent 32000;
BA_ "GenSigStartValue" SG_ 2566722989 FD15_Battery_Charger1_Out_Curr 32000;
BA_ "GenSigStartValue" SG_ 2566722733 FD14_Bat_Charger2_OutputCurrent 32000;
BA_ "GenSigStartValue" SG_ 2354970657 _5E00_ReqDC_S_CurMaxRegen 2000;
BA_ "GenSigStartValue" SG_ 2354970657 _5E00_ReqDC_S_CurMaxDrive 2000;
BA_ "GenSigStartValue" SG_ 2566723059 FD15_Battery_Charger1_Out_Curr 32000;
BA_ "GenSigStartValue" SG_ 2566675955 FC5D_Recomm_Min_Op_Temp 8736;
BA_ "GenSigStartValue" SG_ 2566675955 FC5D_Recomm_Max_Op_Temp 8736;
BA_ "GenSigStartValue" SG_ 2565903859 F095_HVESS_Temp 40;
BA_ "GenSigStartValue" SG_ 2565903859 F095_HVESS_Outlet_Coolant_Temp 40;
BA_ "GenSigStartValue" SG_ 2565903859 F095_HVESS_Intanke_Coolant_Temp 40;
BA_ "GenSigStartValue" SG_ 2565903859 F095_HVESS_Electro_Temp 40;
BA_ "GenSigStartValue" SG_ 2565903603 F094_HVESS_Discharge_Curr_Lim 32000;
BA_ "GenSigStartValue" SG_ 2565903603 F094_HVESS_Charge_Curr_Lim 32000;
BA_ "GenSigStartValue" SG_ 2565902579 F090_HVESS_Current 32000;
BA_ "GenSigStartValue" SG_ 2566722889 FD15_Battery_Charger1_Out_Curr 32000;
BA_ "GenSigStartValue" SG_ 2351300641 _2600_MG1_InverterControl_SetReq 32000;
BA_ "GenSigStartValue" SG_ 2351300641 _2600_MG1_Inverter_Min 125;
BA_ "GenSigStartValue" SG_ 2351300641 _2600_MG1_Inverter_Max 125;
BA_ "SPN" SG_ 2364539943 EngineSpeed 190;
BA_ "GenSigStartValue" SG_ 2364539943 ActualEnginePercentTorque 125;
BA_ "SPN" SG_ 2364539943 ActualEnginePercentTorque 513;
BA_ "GenSigStartValue" SG_ 2364539943 DriversDemandEnginePercentTorque 125;
BA_ "SPN" SG_ 2364539943 DriversDemandEnginePercentTorque 512;
BA_ "GenSigStartValue" SG_ 2566826755 FEAB_LowestPossibleGear 125;
BA_ "GenSigStartValue" SG_ 2566826755 FEAB_HighestPossibleGear 125;
BA_ "GenSigStartValue" SG_ 2566826755 FEAB_RecommendedGear 125;
BA_ "GenSigStartValue" SG_ 2565876164 F029_RollAngle_C4 8192000;
BA_ "GenSigStartValue" SG_ 2565876164 F029_PitchAngle_C4 8192000;
BA_ "GenSigStartValue" SG_ 2565876163 F029_RollAngle_C3 8192000;
BA_ "GenSigStartValue" SG_ 2565876163 F029_PitchAngle_C3 8192000;
BA_ "GenSigStartValue" SG_ 2566867233 FF49_TargetRollSlope 32127;
BA_ "GenSigStartValue" SG_ 2566867233 FF49_TargetPitchSlope 32127;
BA_ "GenSigStartValue" SG_ 2566867233 FF49_CorrectedRollSlope 32127;
BA_ "GenSigStartValue" SG_ 2566867233 FF49_CorrectedPitchSlope 32127;
BA_ "GenSigStartValue" SG_ 2565875998 F029_RollAngle 8192000;
BA_ "GenSigStartValue" SG_ 2565875998 F029_PitchAngle 8192000;
BA_ "GenSigStartValue" SG_ 2566866977 FF48_Corrected_Roll_Angle 130;
BA_ "GenSigStartValue" SG_ 2566866977 FF48_Corrected_Pitch_Angle 130;
BA_ "SPN" SG_ 2565482535 ParameterGroupNumber 2574;
BA_ "SPN" SG_ 2565472295 ParameterGroupNumber 2540;
BA_ "GenSigStartValue" SG_ 2364539937 DriversDemandEnginePercentTorque 125;
BA_ "SPN" SG_ 2364539937 DriversDemandEnginePercentTorque 512;
BA_ "GenSigStartValue" SG_ 2364539937 ActualEnginePercentTorque 125;
BA_ "SPN" SG_ 2364539937 ActualEnginePercentTorque 513;
BA_ "SPN" SG_ 2364539937 EngineSpeed 190;
BA_ "GenSigStartValue" SG_ 2365571105 FFC0_HydraulicTemperature 40;
BA_ "GenSigStartValue" SG_ 2365573409 FFC9_HydraulicOilTemp 30;
BA_ "GenSigStartValue" SG_ 2566733312 FD3E_ATS1SCRcataOurtakeGasTemp 8736;
BA_ "GenSigStartValue" SG_ 2566733312 FD3E_ATS1SCRcataIntakeGasTemp 8736;
BA_ "GenSigStartValue" SG_ 2566846353 NetBatteryCurrent 125;
BA_ "SPN" SG_ 2566846353 NetBatteryCurrent 114;
BA_ "SPN" SG_ 2566846353 AlternatorCurrent 115;
BA_ "SPN" SG_ 2566846353 ChargingSystemPotential 167;
BA_ "SPN" SG_ 2566846353 BatteryPotentialPowerInput1 168;
BA_ "SPN" SG_ 2566846353 KeyswitchBatteryPotential 158;
BA_ "SPN" SG_ 2566749329 DieselParticulateFilterLampCmd 3697;
BA_ "SPN" SG_ 2566749329 AftrtrtmntDslPFPassiveRegenStat 3699;
BA_ "SPN" SG_ 2566749329 AftrtrtmntDslPFActvRegenStatus 3700;
BA_ "SPN" SG_ 2566749329 AftrtrtmntDslPFStatus 3701;
BA_ "SPN" SG_ 2566749329 DslPFActvRegenInhbtdStatus 3702;
BA_ "SPN" SG_ 2566749329 DslPFActvRegenInhbtdDTInhbtSw 3703;
BA_ "SPN" SG_ 2566749329 DslPFActRegenInhbtdDTCltchDiseng 3704;
BA_ "SPN" SG_ 2566749329 DslPFActRegenInhbtdDTSrvcBrkActv 3705;
BA_ "SPN" SG_ 2566749329 DslPFActvRegenInhbtdDTPTOActv 3706;
BA_ "SPN" SG_ 2566749329 DPFActRegenInhbtdDTAcclPdlOffIdl 3707;
BA_ "SPN" SG_ 2566749329 DslPFActvRegenInhbtdDTOutOfNtrl 3708;
BA_ "SPN" SG_ 2566749329 DPFActRegInhDTVhclSpdAbvAllwdSpd 3709;
BA_ "SPN" SG_ 2566749329 DPFActRegenInhbtdDTPrkBrkNotSet 3710;
BA_ "SPN" SG_ 2566749329 DPFActRegenInhbtdDTLowExhstTemp 3711;
BA_ "SPN" SG_ 2566749329 DslPFActRegenInhbtdDTSysFaultAct 3712;
BA_ "SPN" SG_ 2566749329 DslPFActvRegenInhbtdDTSysTimeout 3713;
BA_ "SPN" SG_ 2566749329 DPFActRegenInhbtdDTTmprySysLckt 3714;
BA_ "SPN" SG_ 2566749329 DPFActRegenInhbtdDTPrmntSysLckt 3715;
BA_ "SPN" SG_ 2566749329 DPFActRegInhbtdDTEngNotWarmedUp 3716;
BA_ "SPN" SG_ 2566749329 DPFActRegInhDTVhclSpdBlwAllwdSpd 3717;
BA_ "SPN" SG_ 2566749329 DslPFAutoActvRegenInitConf 3718;
BA_ "SPN" SG_ 2566749329 ExhstSystemHghTemperatureLampCmd 3698;
BA_ "SPN" SG_ 2566749329 DslPFActvRegenForcedStatus 4175;
BA_ "SPN" SG_ 2566749329 HydrocarbonDoserPurgingEnable 5504;
BA_ "SPN" SG_ 2566749329 DPFActRegenInhbtdDTLowExhstPress 5629;
BA_ "SPN" SG_ 2566749329 Aft1DPFConditionsNotMetForActReg 3750;
BA_ "SPN" SG_ 2566749073 Aftrtrtmnt1DslPFSootLoadPercent 3719;
BA_ "SPN" SG_ 2566749073 Aftrtrtmnt1DslPFAshLoadPercent 3720;
BA_ "SPN" SG_ 2566749073 Aft1DslPFTmeSncLastActvRegen 3721;
BA_ "SPN" SG_ 2566749073 Aft1DslPFSootLoadRegenTrshld 5466;
VAL_ 2566757120 Aftrtrtmnt1DslExhstFluidProperty 0 "Urea concentration too high" 1 "Urea concentration too low" 2 "Fluid is diesel" 3 "Diesel exhaust fluid is proper mixture" 13 "Fluid type unknown" 14 "Fluid property detection error" 15 "Not available" ;
VAL_ 2566864627 FF3E_ChargingState 7 "NotAvailable" 6 "ChargerError" 5 "_" 4 "Pause" 3 "Complete" 2 "Failure" 1 "Charging" 0 "Standby" ;
VAL_ 2348810279 TSC1EngineOverrideCtrlMode 0 "Override disabled" 1 "Speed control" 2 "Torque control" 3 "Speed/torque limit control" ;
VAL_ 2566866721 FF47_ChargingStatus 3 "Yellow" 2 "Green" 1 "Gray" 0 "Off" ;
VAL_ 2566866721 FF47_Working_TravelEnable 3 "Not Defined" 2 "Green" 1 "Gray" 0 "Off" ;
VAL_ 2565865728 F001_EngAuxShDnSW 3 "Not available" 2 "Error" 1 "On" 0 "Off" ;
VAL_ 2566704273 FCCC_Af1OutGasSenPwrSupply 3 "Unavailable" 2 "Error" 1 "On " 0 "Off" ;
VAL_ 2566704273 FCCC_Af1InGasSenPwrSupply 3 "Unavailable" 2 "Error" 1 "On " 0 "Off" ;
VAL_ 2566768128 FDC6_EngColdEnableDev1 3 "Not available" 2 "Reserved" 1 "Start enable ON" 0 "Start enable OFF" ;
VAL_ 2566749329 DieselParticulateFilterLampCmd 0 "Off" 1 "On - solid" 2 "reserved for SAE assignment " 3 "reserved for SAE assignment" 4 "On - fast blink (1 HZ)" 5 "reserved for SAE assignment" 6 "reserved for SAE assignment" 7 "not available" ;
VAL_ 2566749329 AftrtrtmntDslPFActvRegenStatus 0 "not active" 1 "active" 2 "regeneration needed" 3 "not available" ;
VAL_ 2566749329 AftrtrtmntDslPFStatus 0 "Regeneration not needed" 1 "Regeneration needed - lowest level" 2 "Regeneration needed - moderate level" 3 "Regeneration needed - highest level" 4 "reserved for SAE assignment" 5 "reserved for SAE assignment" 6 "reserved for SAE assignment" 7 "not available" ;
VAL_ 2566749329 DslPFActvRegenInhbtdStatus 0 "not inhibited" 1 "inhibited" 2 "reserved for SAE assignment" 3 "not available" ;
VAL_ 2566749329 DslPFActvRegenInhbtdDTInhbtSw 0 "not inhibited" 1 "inhibited" 2 "reserved for SAE assignment" 3 "not available" ;
VAL_ 2566749329 DslPFActRegenInhbtdDTCltchDiseng 0 "not inhibited" 1 "inhibited" 2 "reserved for SAE assignment" 3 "not available" ;
VAL_ 2566749329 DslPFActRegenInhbtdDTSrvcBrkActv 0 "not inhibited" 1 "inhibited" 2 "reserved for SAE assignment" 3 "not available" ;
VAL_ 2566749329 DslPFActvRegenInhbtdDTPTOActv 0 "not inhibited" 1 "inhibited" 2 "reserved for SAE assignment" 3 "not available" ;
VAL_ 2566749329 DPFActRegenInhbtdDTAcclPdlOffIdl 0 "not inhibited" 1 "inhibited" 2 "reserved for SAE assignment" 3 "not available" ;
VAL_ 2566749329 DslPFActvRegenInhbtdDTOutOfNtrl 0 "not inhibited" 1 "inhibited" 2 "reserved for SAE assignment" 3 "not available" ;
VAL_ 2566749329 DPFActRegInhDTVhclSpdAbvAllwdSpd 0 "not inhibited" 1 "inhibited" 2 "reserved for SAE assignment" 3 "not available" ;
VAL_ 2566749329 DPFActRegenInhbtdDTPrkBrkNotSet 0 "not inhibited" 1 "inhibited" 2 "reserved for SAE assignment" 3 "not available" ;
VAL_ 2566749329 DPFActRegenInhbtdDTLowExhstTemp 0 "not inhibited" 1 "inhibited" 2 "reserved for SAE assignment" 3 "not available" ;
VAL_ 2566749329 DslPFActRegenInhbtdDTSysFaultAct 0 "not inhibited" 1 "inhibited" 2 "reserved for SAE assignment" 3 "not available" ;
VAL_ 2566749329 DslPFActvRegenInhbtdDTSysTimeout 0 "not inhibited" 1 "inhibited" 2 "reserved for SAE assignment" 3 "not available" ;
VAL_ 2566749329 DPFActRegenInhbtdDTTmprySysLckt 0 "not inhibited" 1 "inhibited" 2 "reserved for SAE assignment" 3 "not available" ;
VAL_ 2566749329 DPFActRegenInhbtdDTPrmntSysLckt 0 "not inhibited" 1 "inhibited" 2 "reserved for SAE assignment" 3 "not available" ;
VAL_ 2566749329 DPFActRegInhbtdDTEngNotWarmedUp 0 "not inhibited" 1 "inhibited" 2 "reserved for SAE assignment" 3 "not available" ;
VAL_ 2566749329 DPFActRegInhDTVhclSpdBlwAllwdSpd 0 "not inhibited" 1 "inhibited" 2 "reserved for SAE assignment" 3 "not available" ;
VAL_ 2566749329 DslPFAutoActvRegenInitConf 0 "not enabled" 1 "enabled" 2 "reserved for SAE assignment" 3 "not available" ;
VAL_ 2566749329 ExhstSystemHghTemperatureLampCmd 0 "Off" 1 "On - solid " 2 "reserved for SAE assignment " 3 "reserved for SAE assignment" 4 "reserved for SAE assignment" 5 "reserved for SAE assignment" 6 "reserved for SAE assignment" 7 "not available" ;
VAL_ 2566749329 DslPFActvRegenForcedStatus 0 "Not Active" 1 "Active - Forced by Switch (See SPN 3696)" 2 "Active - Forced by Service Tool " 3 "Reserved for SAE Assignment" 4 "Reserved for SAE Assignment" 5 "Reserved for SAE Assignment" 6 "Reserved for SAE Assignment" 7 "not available" ;
VAL_ 2566749329 HydrocarbonDoserPurgingEnable 0 "Purging not enabled" 1 "Purging enabled" 2 "Purging enabled" 3 "Not available" ;
VAL_ 2566749329 DPFActRegenInhbtdDTLowExhstPress 0 "not inhibited" 1 "inhibited" 2 "reserved for SAE assignment" 3 "not available" ;
VAL_ 2566749329 Aft1DPFConditionsNotMetForActReg 0 "active DPF regeneration not inhibited" 1 "active DPF regeneration inhibited" 2 "reserved for SAE assignment" 3 "not available" ;
VAL_ 2558918400 AtRegenEngSpdAllowSW 3 "Not available" 2 "Error" 1 "AT regen is  allowed " 0 "AT regen is not allowed " ;
VAL_ 2558918400 ElevEngSpdAllowSW 3 "Not available" 2 "Error" 1 "Allowed to elevate engine speed" 0 "Not allow to elevate eng speed" ;
